VERSION "10.7.5"

NS_ :

BS_:

BU_: ADAS_Info AMP CPD DUMMY_DEBUG DUMMY_ECU EASC HUD MHU XGW_Info

BO_ 18 MHU_Climate_control: 8 CPD
  SG_ CPD_MHU_Climate_control : 7|2@0+ (1,0) [0|3] "" MHU

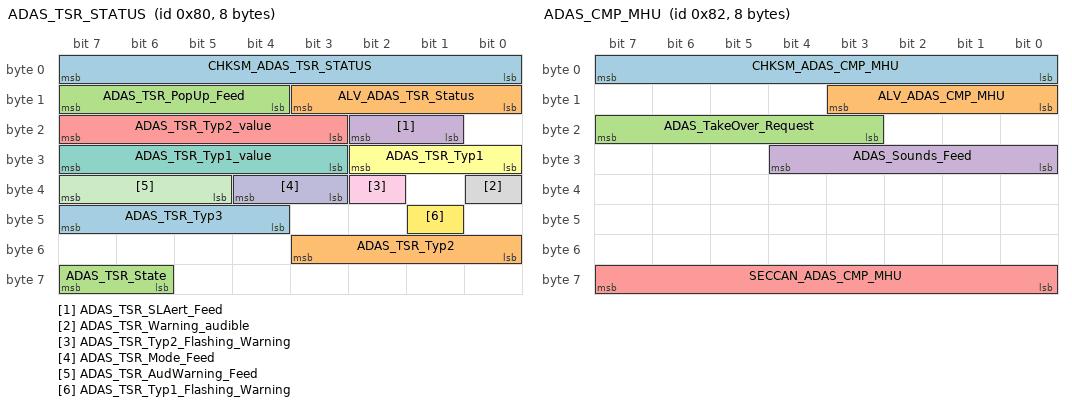
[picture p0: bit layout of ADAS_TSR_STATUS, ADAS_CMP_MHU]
BO_ 128 ADAS_TSR_STATUS: 8 ADAS_Info
  SG_ CHKSM_ADAS_TSR_STATUS : 7|8@0+ (1,0) [0|255] "" HUD,MHU
  SG_ ALV_ADAS_TSR_Status : 11|4@0+ (1,0) [0|14] "" HUD,MHU
  SG_ ADAS_TSR_PopUp_Feed : 15|4@0+ (1,0) [0|15] "-" MHU
  SG_ ADAS_TSR_SLAert_Feed : 18|2@0+ (1,0) [0|3] "-" HUD,MHU
  SG_ ADAS_TSR_Typ2_value : 23|5@0+ (1,0) [0|31] "-" HUD,MHU
  SG_ ADAS_TSR_Typ1 : 26|3@0+ (1,0) [0|7] "-" HUD,MHU
  SG_ ADAS_TSR_Typ1_value : 31|5@0+ (1,0) [0|31] "-" HUD,MHU
  SG_ ADAS_TSR_Warning_audible : 32|1@0+ (1,0) [0|1] "-" HUD,MHU
  SG_ ADAS_TSR_Typ2_Flashing_Warning : 34|1@0+ (1,0) [0|1] "-" HUD,MHU
  SG_ ADAS_TSR_Mode_Feed : 36|2@0+ (1,0) [0|3] "-" HUD,MHU
  SG_ ADAS_TSR_AudWarning_Feed : 39|3@0+ (1,0) [0|1] "-" HUD,MHU
  SG_ ADAS_TSR_Typ1_Flashing_Warning : 41|1@0+ (1,0) [0|1] "-" HUD,MHU
  SG_ ADAS_TSR_Typ3 : 47|4@0+ (1,0) [0|15] "-" HUD,MHU
  SG_ ADAS_TSR_Typ2 : 51|4@0+ (1,0) [0|15] "-" HUD,MHU
  SG_ ADAS_TSR_State : 63|2@0+ (1,0) [0|3] "-" HUD,MHU

BO_ 130 ADAS_CMP_MHU: 8 ADAS_Info
  SG_ CHKSM_ADAS_CMP_MHU : 7|8@0+ (1,0) [0|255] "" MHU
  SG_ ALV_ADAS_CMP_MHU : 11|4@0+ (1,0) [0|14] "" MHU
  SG_ ADAS_TakeOver_Request : 23|5@0+ (1,0) [0|31] "-" MHU
  SG_ ADAS_Sounds_Feed : 28|5@0+ (1,0) [0|31] "-" MHU
  SG_ SECCAN_ADAS_CMP_MHU : 63|8@0+ (1,0) [0|255] "" MHU

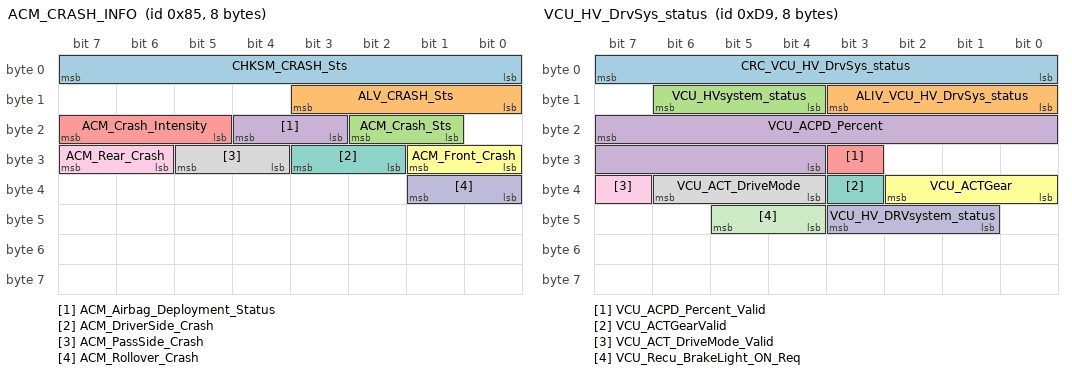
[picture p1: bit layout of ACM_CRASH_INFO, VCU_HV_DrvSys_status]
BO_ 133 ACM_CRASH_INFO: 8 XGW_Info
  SG_ CHKSM_CRASH_Sts : 7|8@0+ (1,0) [0|255] "" MHU
  SG_ ALV_CRASH_Sts : 11|4@0+ (1,0) [0|14] "" MHU
  SG_ ACM_Crash_Sts : 18|2@0+ (1,0) [0|3] "" MHU
  SG_ ACM_Airbag_Deployment_Status : 20|2@0+ (1,0) [0|3] "-" MHU
  SG_ ACM_Crash_Intensity : 23|3@0+ (1,0) [0|7] "" MHU
  SG_ ACM_Front_Crash : 25|2@0+ (1,0) [0|3] "-" MHU
  SG_ ACM_DriverSide_Crash : 27|2@0+ (1,0) [0|3] "" MHU
  SG_ ACM_PassSide_Crash : 29|2@0+ (1,0) [0|3] "-" MHU
  SG_ ACM_Rear_Crash : 31|2@0+ (1,0) [0|3] "-" MHU
  SG_ ACM_Rollover_Crash : 33|2@0+ (1,0) [0|3] "-" MHU

BO_ 147 IDB_MILEAGE: 4 XGW_Info
  SG_ CHKSM_MILEAGE : 7|8@0+ (1,0) [0|255] "" MHU
  SG_ ALIVE_MILEAGE : 11|4@0+ (1,0) [0|14] "" MHU
  SG_ Mileage : 23|16@0+ (1,0) [0|65535] "km" MHU

BO_ 149 IDB_FUNCTION: 8 XGW_Info
  SG_ CHKSM_IDB_FUNCTION : 7|8@0+ (1,0) [0|255] "" MHU
  SG_ ALV_IDB_FUNCTION : 11|4@0+ (1,0) [0|14] "" MHU
  SG_ STAT_ABS : 13|2@0+ (1,0) [0|3] "" MHU
  SG_ AYC_Active : 17|2@0+ (1,0) [0|3] "Bit" MHU
  SG_ ASR_Active : 19|2@0+ (1,0) [0|3] "-" MHU
  SG_ STAT_DSC : 21|2@0+ (1,0) [0|3] "-" MHU
  SG_ DSC_Active : 23|2@0+ (1,0) [0|3] "" MHU
  SG_ HBA_ActiveSignal : 25|2@0+ (1,0) [0|3] "" MHU
  SG_ ARM_ActiveSignal : 27|2@0+ (1,0) [0|3] "-" MHU
  SG_ STAT_AutoHazardBlinking : 29|2@0+ (1,0) [0|3] "Bit" MHU
  SG_ MSR_Active : 31|2@0+ (1,0) [0|3] "-" MHU
  SG_ HSA_ActiveSignal : 33|2@0+ (1,0) [0|3] "" MHU
  SG_ EPBi_ECD_ActiveSignal : 35|2@0+ (1,0) [0|3] "" MHU
  SG_ TSM_Active : 37|2@0+ (1,0) [0|3] "-" MHU
  SG_ HAS_Available : 41|2@0+ (1,0) [0|3] "" MHU
  SG_ STAT_EBD : 43|2@0+ (1,0) [0|3] "" MHU
  SG_ EBD_Active : 45|2@0+ (1,0) [0|3] "" MHU
  SG_ ST_BRG_MSA : 55|4@0+ (1,0) [0|15] "" MHU

BO_ 150 MHU_IDB_Mode_Select: 2 MHU
  SG_ CHKSM_MHU_IDB_Mode_Select : 7|8@0+ (1,0) [0|255] "" XGW_Info
  SG_ ALV_MHU_IDB_Mode_Select : 11|4@0+ (1,0) [0|14] "" XGW_Info
  SG_ MHU_IDB_Mode_Select_Signal : 15|2@0+ (1,0) [0|3] "" XGW_Info

BO_ 217 VCU_HV_DrvSys_status: 8 XGW_Info
  SG_ CRC_VCU_HV_DrvSys_status : 7|8@0+ (1,0) [0|255] "" CPD,MHU
  SG_ ALIV_VCU_HV_DrvSys_status : 11|4@0+ (1,0) [0|14] "" CPD,MHU
  SG_ VCU_HVsystem_status : 14|3@0+ (1,0) [0|7] "-" CPD,MHU
  SG_ VCU_ACPD_Percent : 23|12@0+ (0.0625,0) [0|100] "%" MHU
  SG_ VCU_ACPD_Percent_Valid : 27|1@0+ (1,0) [0|1] "" MHU
  SG_ VCU_ACTGear : 34|3@0+ (1,0) [0|7] "" HUD,MHU
  SG_ VCU_ACTGearValid : 35|1@0+ (1,0) [0|1] "" HUD,MHU
  SG_ VCU_ACT_DriveMode : 38|3@0+ (1,0) [0|7] "" HUD,MHU
  SG_ VCU_ACT_DriveMode_Valid : 39|1@0+ (1,0) [0|1] "-" HUD,MHU
  SG_ VCU_HV_DRVsystem_status : 43|3@0+ (1,0) [0|7] "" MHU
  SG_ VCU_Recu_BrakeLight_ON_Req : 45|2@0+ (1,0) [0|3] "-" MHU

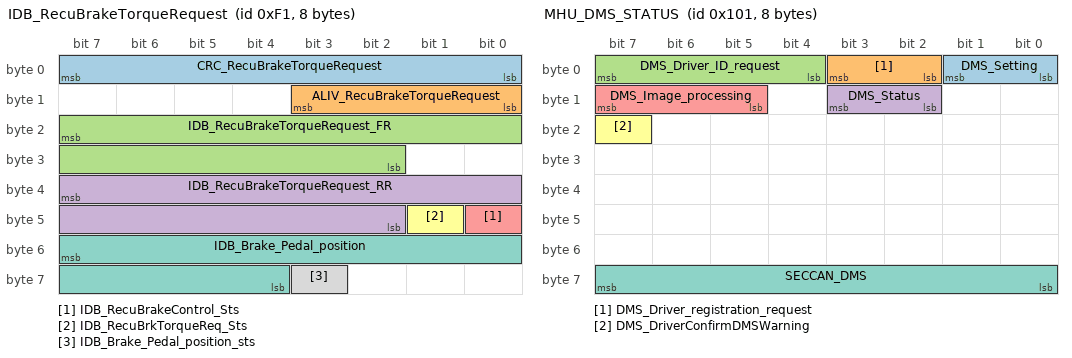
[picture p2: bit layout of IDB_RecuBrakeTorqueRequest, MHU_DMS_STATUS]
BO_ 241 IDB_RecuBrakeTorqueRequest: 8 XGW_Info
  SG_ CRC_RecuBrakeTorqueRequest : 7|8@0+ (1,0) [0|255] "" DUMMY_ECU,MHU
  SG_ ALIV_RecuBrakeTorqueRequest : 11|4@0+ (1,0) [0|14] "" DUMMY_ECU,MHU
  SG_ IDB_RecuBrakeTorqueRequest_FR : 23|14@0+ (1,0) [0|8000] "Nm" DUMMY_ECU
  SG_ IDB_RecuBrakeTorqueRequest_RR : 39|14@0+ (1,0) [0|8000] "Nm" DUMMY_ECU
  SG_ IDB_RecuBrakeControl_Sts : 40|1@0+ (1,0) [0|1] "" DUMMY_ECU
  SG_ IDB_RecuBrkTorqueReq_Sts : 41|1@0+ (1,0) [0|1] "" DUMMY_ECU
  SG_ IDB_Brake_Pedal_position : 55|12@0+ (0.0625,0) [0|100] "%" MHU
  SG_ IDB_Brake_Pedal_position_sts : 59|1@0+ (1,0) [0|1] "" MHU

BO_ 256 MHU_Vehicle_Info: 8 MHU
  SG_ CHKSM_MHU_VEH_INFO : 7|8@0+ (1,0) [0|255] "" ADAS_Info,HUD,XGW_Info
  SG_ ALV_MHU_VEH_INFO : 11|4@0+ (1,0) [0|14] "" ADAS_Info,HUD,XGW_Info
  SG_ MHU_UserProfileId : 23|4@0+ (1,0) [0|15] "-" HUD,XGW_Info
  SG_ MHU_Connectivity_Status : 47|3@0+ (1,0) [0|7] "" ADAS_Info,XGW_Info

BO_ 257 MHU_DMS_STATUS: 8 MHU
  SG_ DMS_Setting : 1|2@0+ (1,0) [0|3] "-" ADAS_Info
  SG_ DMS_Driver_registration_request : 3|2@0+ (1,0) [0|3] "-" ADAS_Info
  SG_ DMS_Driver_ID_request : 7|4@0+ (1,0) [0|15] "-" ADAS_Info
  SG_ DMS_Status : 11|2@0+ (1,0) [0|3] "-" ADAS_Info
  SG_ DMS_Image_processing : 15|3@0+ (1,0) [0|7] "-" ADAS_Info
  SG_ DMS_DriverConfirmDMSWarning : 23|1@0+ (1,0) [0|1] "" ADAS_Info
  SG_ SECCAN_DMS : 63|8@0+ (1,0) [0|255] "" ADAS_Info

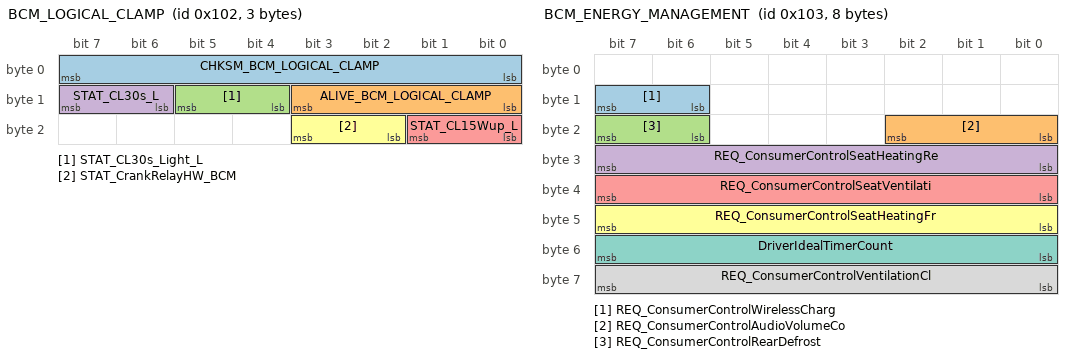
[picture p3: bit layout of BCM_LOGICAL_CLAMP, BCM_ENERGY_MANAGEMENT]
BO_ 258 BCM_LOGICAL_CLAMP: 3 XGW_Info
  SG_ CHKSM_BCM_LOGICAL_CLAMP : 7|8@0+ (1,0) [0|255] "" HUD,MHU
  SG_ ALIVE_BCM_LOGICAL_CLAMP : 11|4@0+ (1,0) [0|14] "" HUD,MHU
  SG_ STAT_CL30s_Light_L : 13|2@0+ (1,0) [0|3] "" MHU
  SG_ STAT_CL30s_L : 15|2@0+ (1,0) [0|3] "Bit" HUD,MHU
  SG_ STAT_CL15Wup_L : 17|2@0+ (1,0) [0|3] "Bit" MHU
  SG_ STAT_CrankRelayHW_BCM : 19|2@0+ (1,0) [0|3] "Bit" MHU

BO_ 259 BCM_ENERGY_MANAGEMENT: 8 XGW_Info
  SG_ REQ_ConsumerControlWirelessCharg : 15|2@0+ (1,0) [0|3] "-" MHU
  SG_ REQ_ConsumerControlAudioVolumeCo : 18|3@0+ (1,0) [0|7] "-" MHU
  SG_ REQ_ConsumerControlRearDefrost : 23|2@0+ (1,0) [0|3] "-" MHU
  SG_ REQ_ConsumerControlSeatHeatingRe : 31|8@0+ (1,0) [0|100] "%" MHU
  SG_ REQ_ConsumerControlSeatVentilati : 39|8@0+ (1,0) [0|100] "%" MHU
  SG_ REQ_ConsumerControlSeatHeatingFr : 47|8@0+ (1,0) [0|100] "%" MHU
  SG_ DriverIdealTimerCount : 55|8@0+ (5,0) [0|1275] "s" MHU
  SG_ REQ_ConsumerControlVentilationCl : 63|8@0+ (1,0) [0|100] "%" MHU

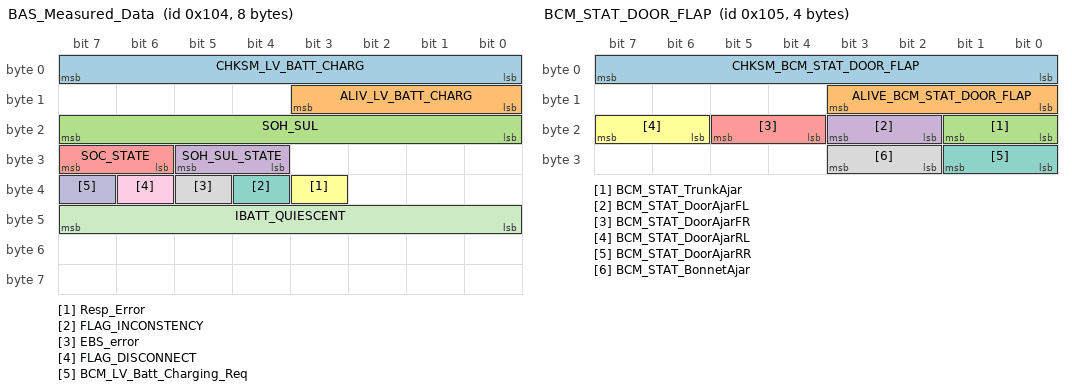
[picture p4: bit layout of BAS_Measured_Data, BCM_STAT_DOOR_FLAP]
BO_ 260 BAS_Measured_Data: 8 XGW_Info
  SG_ CHKSM_LV_BATT_CHARG : 7|8@0+ (1,0) [0|255] "" MHU
  SG_ ALIV_LV_BATT_CHARG : 11|4@0+ (1,0) [0|14] "" MHU
  SG_ SOH_SUL : 23|8@0+ (1,0) [0|100] "%" MHU
  SG_ SOH_SUL_STATE : 29|2@0+ (1,0) [0|3] "" MHU
  SG_ SOC_STATE : 31|2@0+ (1,0) [0|3] "%" MHU
  SG_ Resp_Error : 35|1@0+ (1,0) [0|1] "" MHU
  SG_ FLAG_INCONSTENCY : 36|1@0+ (1,0) [0|1] "%" MHU
  SG_ EBS_error : 37|1@0+ (1,0) [0|1] "" MHU
  SG_ FLAG_DISCONNECT : 38|1@0+ (1,0) [0|1] "" MHU
  SG_ BCM_LV_Batt_Charging_Req : 39|1@0+ (1,0) [0|1] "" MHU
  SG_ IBATT_QUIESCENT : 47|8@0+ (0.00390625,0) [0|0.984375] "" MHU

BO_ 261 BCM_STAT_DOOR_FLAP: 4 XGW_Info
  SG_ CHKSM_BCM_STAT_DOOR_FLAP : 7|8@0+ (1,0) [0|255] "" CPD,MHU
  SG_ ALIVE_BCM_STAT_DOOR_FLAP : 11|4@0+ (1,0) [0|14] "" CPD,MHU
  SG_ BCM_STAT_TrunkAjar : 17|2@0+ (1,0) [0|3] "Bit" CPD,MHU
  SG_ BCM_STAT_DoorAjarFL : 19|2@0+ (1,0) [0|3] "Bit" CPD,MHU
  SG_ BCM_STAT_DoorAjarFR : 21|2@0+ (1,0) [0|3] "Bit" CPD,MHU
  SG_ BCM_STAT_DoorAjarRL : 23|2@0+ (1,0) [0|3] "Bit" CPD,MHU
  SG_ BCM_STAT_DoorAjarRR : 25|2@0+ (1,0) [0|3] "Bit" CPD,MHU
  SG_ BCM_STAT_BonnetAjar : 27|2@0+ (1,0) [0|3] "Bit" CPD,MHU

BO_ 262 BCM_LIGHT: 8 XGW_Info
  SG_ CHKSM_BCM_LIGHT : 7|8@0+ (1,0) [0|255] "" HUD,MHU
  SG_ ALIVE_BCM_LIGHT : 11|4@0+ (1,0) [0|14] "" HUD,MHU
  SG_ BCM_DayRunningLampSts : 13|2@0+ (1,0) [0|3] "" HUD,MHU
  SG_ BCM_ReverseLightSts : 15|2@0+ (1,0) [0|3] "" HUD,MHU
  SG_ BCM_StopLightSts : 17|2@0+ (1,0) [0|3] "" HUD,MHU
  SG_ BCM_LicensePlateLightSts : 19|2@0+ (1,0) [0|3] "" HUD,MHU
  SG_ BCM_Fr_Dimming_dome_lampSts : 21|2@0+ (1,0) [0|3] "" HUD,MHU
  SG_ BCM_Rr_Dimming_dome_lampSts : 23|2@0+ (1,0) [0|3] "" HUD,MHU
  SG_ BCM_STAT_InteriorLight : 25|2@0+ (1,0) [0|3] "Bit" HUD,MHU
  SG_ BCM_STAT_LightActivation : 28|3@0+ (1,0) [0|7] "-" HUD,MHU
  SG_ BCM_HighBeamSts : 31|2@0+ (1,0) [0|3] "" HUD,MHU
  SG_ BCM_STAT_SwitchLightBrightness : 39|7@0+ (1,0) [0|100] "%" HUD,MHU
  SG_ BCM_LowBeamSts : 41|2@0+ (1,0) [0|3] "-" HUD,MHU
  SG_ BCM_RearFogLmpSts : 43|2@0+ (1,0) [0|3] "-" HUD,MHU
  SG_ BCM_FrntFogLmpSts : 45|2@0+ (1,0) [0|3] "" HUD,MHU
  SG_ BCM_PosLmpSts : 47|2@0+ (1,0) [0|3] "-" HUD,MHU
  SG_ BCM_HornSts : 53|2@0+ (1,0) [0|3] "" MHU
  SG_ BCM_TurnIndicatorSts : 55|2@0+ (1,0) [0|3] "" HUD,MHU

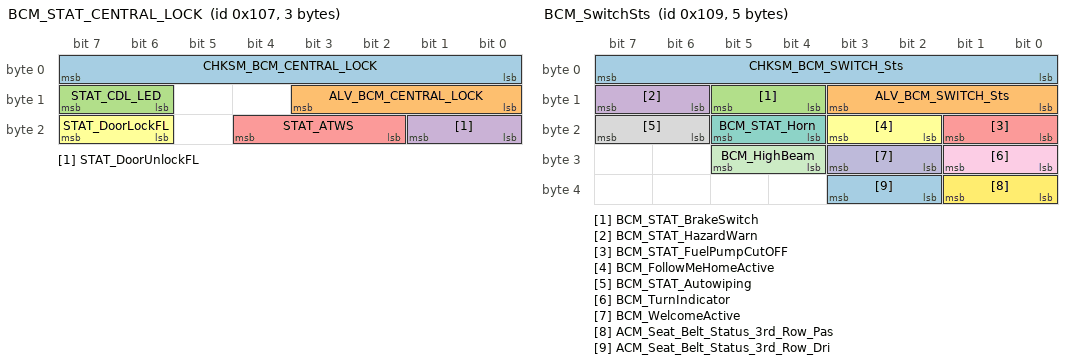
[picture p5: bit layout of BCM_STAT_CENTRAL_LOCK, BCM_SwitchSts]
BO_ 263 BCM_STAT_CENTRAL_LOCK: 3 XGW_Info
  SG_ CHKSM_BCM_CENTRAL_LOCK : 7|8@0+ (1,0) [0|255] "" CPD,MHU
  SG_ ALV_BCM_CENTRAL_LOCK : 11|4@0+ (1,0) [0|14] "" CPD,MHU
  SG_ STAT_CDL_LED : 15|2@0+ (1,0) [0|3] "-" MHU
  SG_ STAT_DoorUnlockFL : 17|2@0+ (1,0) [0|3] "Bit" MHU
  SG_ STAT_ATWS : 20|3@0+ (1,0) [0|7] "Bit" MHU
  SG_ STAT_DoorLockFL : 23|2@0+ (1,0) [0|3] "Bit" CPD,MHU

BO_ 265 BCM_SwitchSts: 5 XGW_Info
  SG_ CHKSM_BCM_SWITCH_Sts : 7|8@0+ (1,0) [0|255] "" MHU
  SG_ ALV_BCM_SWITCH_Sts : 11|4@0+ (1,0) [0|14] "" MHU
  SG_ BCM_STAT_BrakeSwitch : 13|2@0+ (1,0) [0|3] "" MHU
  SG_ BCM_STAT_HazardWarn : 15|2@0+ (1,0) [0|3] "-" MHU
  SG_ BCM_STAT_FuelPumpCutOFF : 17|2@0+ (1,0) [0|3] "" MHU
  SG_ BCM_FollowMeHomeActive : 19|2@0+ (1,0) [0|3] "" MHU
  SG_ BCM_STAT_Horn : 21|2@0+ (1,0) [0|3] "-" MHU
  SG_ BCM_STAT_Autowiping : 23|2@0+ (1,0) [0|3] "" MHU
  SG_ BCM_TurnIndicator : 25|2@0+ (1,0) [0|3] "" MHU
  SG_ BCM_WelcomeActive : 27|2@0+ (1,0) [0|3] "-" MHU
  SG_ BCM_HighBeam : 29|2@0+ (1,0) [0|3] "" MHU
  SG_ ACM_Seat_Belt_Status_3rd_Row_Pas : 33|2@0+ (1,0) [0|3] "" MHU
  SG_ ACM_Seat_Belt_Status_3rd_Row_Dri : 35|2@0+ (1,0) [0|3] "-" MHU

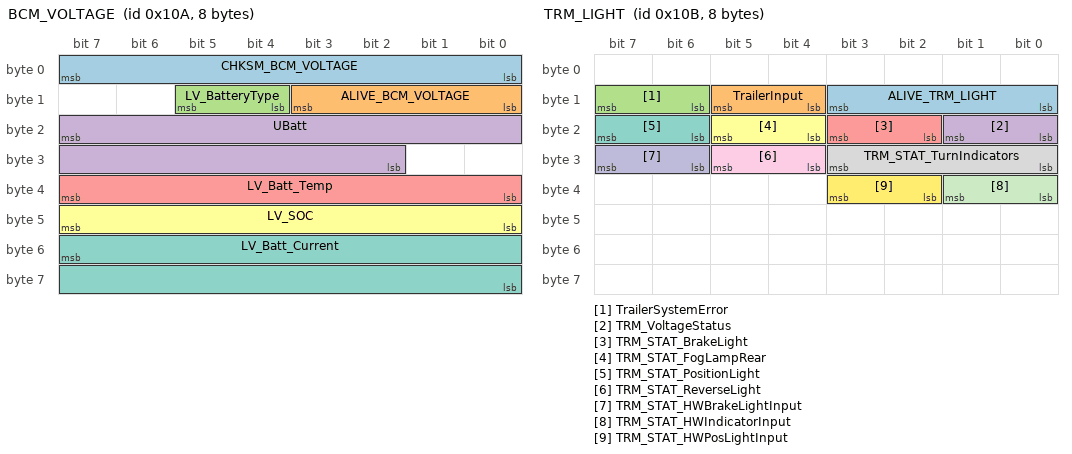
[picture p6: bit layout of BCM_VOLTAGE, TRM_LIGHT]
BO_ 266 BCM_VOLTAGE: 8 XGW_Info
  SG_ CHKSM_BCM_VOLTAGE : 7|8@0+ (1,0) [0|255] "" ADAS_Info,AMP,CPD,EASC,HUD,MHU
  SG_ ALIVE_BCM_VOLTAGE : 11|4@0+ (1,0) [0|14] "" ADAS_Info,AMP,CPD,EASC,HUD,MHU
  SG_ LV_BatteryType : 13|2@0+ (1,0) [0|3] "Number" MHU
  SG_ UBatt : 23|14@0+ (0.0009777,3) [3|18] "V" ADAS_Info,AMP,CPD,EASC,HUD,MHU
  SG_ LV_Batt_Temp : 39|8@0+ (1,-40) [-40|105] "Degree C" ADAS_Info,AMP,CPD,EASC,HUD,MHU
  SG_ LV_SOC : 47|8@0+ (1,0) [0|100] "%" ADAS_Info,AMP,CPD,EASC,HUD,MHU
  SG_ LV_Batt_Current : 55|16@0+ (0.03125,-1536) [-1536|511.90625] "A" ADAS_Info,AMP,CPD,EASC,HUD,MHU

BO_ 267 TRM_LIGHT: 8 XGW_Info
  SG_ ALIVE_TRM_LIGHT : 11|4@0+ (1,0) [0|14] "" MHU
  SG_ TrailerInput : 13|2@0+ (1,0) [0|3] "" MHU
  SG_ TrailerSystemError : 15|2@0+ (1,0) [0|3] "" MHU
  SG_ TRM_VoltageStatus : 17|2@0+ (1,0) [0|3] "" MHU
  SG_ TRM_STAT_BrakeLight : 19|2@0+ (1,0) [0|3] "" MHU
  SG_ TRM_STAT_FogLampRear : 21|2@0+ (1,0) [0|3] "" MHU
  SG_ TRM_STAT_PositionLight : 23|2@0+ (1,0) [0|3] "" MHU
  SG_ TRM_STAT_TurnIndicators : 27|4@0+ (1,0) [0|15] "" MHU
  SG_ TRM_STAT_ReverseLight : 29|2@0+ (1,0) [0|3] "" MHU
  SG_ TRM_STAT_HWBrakeLightInput : 31|2@0+ (1,0) [0|3] "" MHU
  SG_ TRM_STAT_HWIndicatorInput : 33|2@0+ (1,0) [0|3] "" MHU
  SG_ TRM_STAT_HWPosLightInput : 35|2@0+ (1,0) [0|3] "" MHU

BO_ 268 BCM_RemoteCtrlSts: 8 XGW_Info
  SG_ Checksum_0x10C : 7|8@0+ (1,0) [0|255] "" MHU
  SG_ Rolling_Counter_0x10C : 11|4@0+ (1,0) [0|14] "" MHU
  SG_ BCM_TboxAuthStatus : 23|2@0+ (1,0) [0|3] "-" MHU
  SG_ BCM_RandomNum32bit : 31|32@0+ (1,0) [0|4294967295] "-" MHU

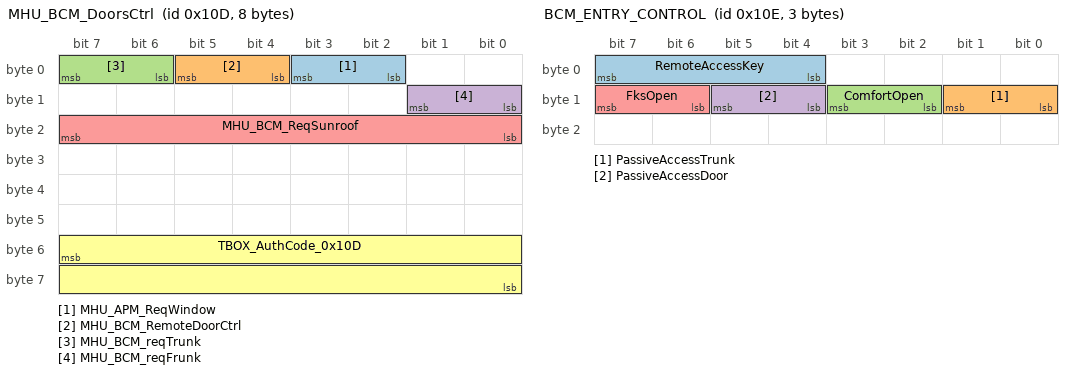
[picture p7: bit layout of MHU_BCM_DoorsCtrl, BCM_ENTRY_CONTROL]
BO_ 269 MHU_BCM_DoorsCtrl: 8 MHU
  SG_ MHU_APM_ReqWindow : 3|2@0+ (1,0) [0|3] "-" XGW_Info
  SG_ MHU_BCM_RemoteDoorCtrl : 5|2@0+ (1,0) [0|3] "-" XGW_Info
  SG_ MHU_BCM_reqTrunk : 7|2@0+ (1,0) [0|3] "-" XGW_Info
  SG_ MHU_BCM_reqFrunk : 9|2@0+ (1,0) [0|3] "-" XGW_Info
  SG_ MHU_BCM_ReqSunroof : 23|8@0+ (1,0) [0|255] "%" XGW_Info
  SG_ TBOX_AuthCode_0x10D : 55|16@0+ (1,0) [0|65535] "-" XGW_Info

BO_ 270 BCM_ENTRY_CONTROL: 3 XGW_Info
  SG_ RemoteAccessKey : 7|4@0+ (1,0) [0|15] "-" CPD,MHU
  SG_ PassiveAccessTrunk : 9|2@0+ (1,0) [0|3] "-" CPD,MHU
  SG_ ComfortOpen : 11|2@0+ (1,0) [0|3] "-" CPD,MHU
  SG_ PassiveAccessDoor : 13|2@0+ (1,0) [0|3] "-" CPD,MHU
  SG_ FksOpen : 15|2@0+ (1,0) [0|3] "" CPD,MHU

BO_ 271 MHU_BCM_HornLightControl: 8 MHU
  SG_ MHU_SetHornOnOff : 3|2@0+ (1,0) [0|3] "-" XGW_Info
  SG_ MHU_SetLowBeam : 5|2@0+ (1,0) [0|3] "" XGW_Info
  SG_ MHU_SetHighBeam : 7|2@0+ (1,0) [0|3] "" XGW_Info
  SG_ TBOX_AuthCode_0x10F : 55|16@0+ (1,0) [0|65535] "-" XGW_Info

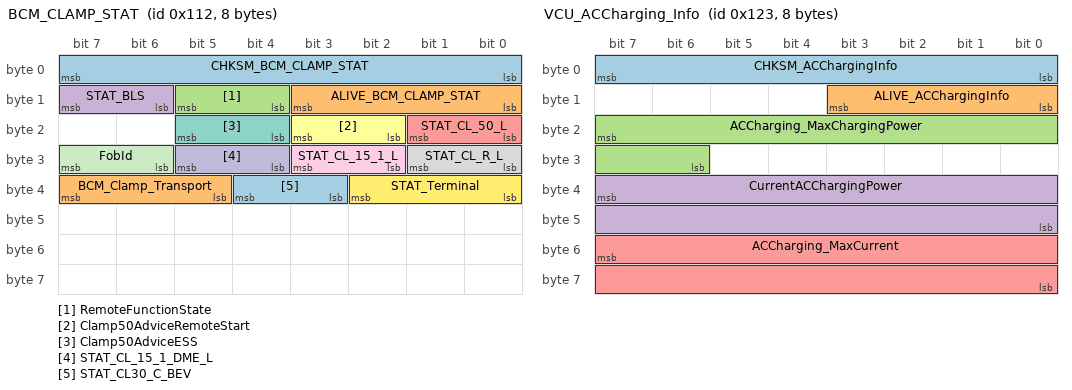
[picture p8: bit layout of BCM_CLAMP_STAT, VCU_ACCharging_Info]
BO_ 274 BCM_CLAMP_STAT: 8 XGW_Info
  SG_ CHKSM_BCM_CLAMP_STAT : 7|8@0+ (1,0) [0|255] "" ADAS_Info,AMP,EASC,HUD,MHU
  SG_ ALIVE_BCM_CLAMP_STAT : 11|4@0+ (1,0) [0|14] "" ADAS_Info,AMP,EASC,HUD,MHU
  SG_ RemoteFunctionState : 13|2@0+ (1,0) [0|3] "" ADAS_Info,AMP,EASC,HUD,MHU
  SG_ STAT_BLS : 15|2@0+ (1,0) [0|3] "-" ADAS_Info,AMP,EASC,HUD,MHU
  SG_ STAT_CL_50_L : 17|2@0+ (1,0) [0|3] "" ADAS_Info,AMP,EASC,HUD,MHU
  SG_ Clamp50AdviceRemoteStart : 19|2@0+ (1,0) [0|3] "-" ADAS_Info,AMP,EASC,HUD,MHU
  SG_ Clamp50AdviceESS : 21|2@0+ (1,0) [0|3] "-" ADAS_Info,AMP,EASC,HUD,MHU
  SG_ STAT_CL_R_L : 25|2@0+ (1,0) [0|3] "" ADAS_Info,AMP,EASC,HUD,MHU
  SG_ STAT_CL_15_1_L : 27|2@0+ (1,0) [0|3] "-" ADAS_Info,AMP,EASC,HUD,MHU
  SG_ STAT_CL_15_1_DME_L : 29|2@0+ (1,0) [0|3] "" ADAS_Info,AMP,EASC,HUD,MHU
  SG_ FobId : 31|2@0+ (1,0) [0|3] "Bit" ADAS_Info,AMP,EASC,HUD,MHU
  SG_ STAT_Terminal : 34|3@0+ (1,0) [0|7] "Bit" ADAS_Info,AMP,CPD,EASC,HUD,MHU
  SG_ STAT_CL30_C_BEV : 36|2@0+ (1,0) [0|3] "Bit" ADAS_Info,AMP,EASC,HUD,MHU
  SG_ BCM_Clamp_Transport : 39|3@0+ (1,0) [0|7] "" ADAS_Info,AMP,EASC,HUD,MHU

BO_ 276 BCM_LVBAT_Data: 8 XGW_Info
  SG_ CHKSM_LVBAT_DATA : 7|8@0+ (1,0) [0|255] ""  MHU
  SG_ ALIV_LVBAT_DATA : 11|4@0+ (1,0) [0|14] ""  MHU
  SG_ LV_ErrorSts : 14|3@0+ (1,0) [0|7] ""  MHU
  SG_ LV_MinCellVolt : 23|8@0+ (0.015625,1) [1|5] "V"  MHU
  SG_ LV_MaxCellVolt : 31|8@0+ (0.015625,1) [1|5] "V"  MHU
  SG_ LV_MinCellTemp : 39|8@0+ (1,-40) [-40|215] "Degree C"  MHU
  SG_ LV_MaxCellTemp : 47|8@0+ (1,-40) [-40|215] "Degree C"  MHU
  SG_ LV_Discharger_Err : 48|1@0+ (1,0) [0|1] ""  MHU
  SG_ LV_Discharger_Sts : 49|1@0+ (1,0) [0|1] ""  MHU
  SG_ LV_Charger_Err : 50|1@0+ (1,0) [0|1] ""  MHU
  SG_ LV_Charger_Sts : 51|1@0+ (1,0) [0|1] ""  MHU
  SG_ LV_OverVoltage : 52|1@0+ (1,0) [0|1] ""  MHU
  SG_ LV_UnderVoltage : 53|1@0+ (1,0) [0|1] ""  MHU
  SG_ LV_OverCurrent : 54|1@0+ (1,0) [0|1] ""  MHU
  SG_ LV_UnderTemp : 55|1@0+ (1,0) [0|1] ""  MHU
  SG_ LV_OverTemp : 56|1@0+ (1,0) [0|1] ""  MHU
  SG_ LV_OverCharge : 57|1@0+ (1,0) [0|1] ""  MHU
  SG_ LV_OverDischarge : 58|1@0+ (1,0) [0|1] ""  MHU
  SG_ LV_CellBalance_Sts : 59|1@0+ (1,0) [0|1] ""  MHU
  SG_ LV_CellBalance_Error : 60|1@0+ (1,0) [0|1] ""  MHU
  SG_ LV_ThermalRunaway : 61|1@0+ (1,0) [0|1] ""  MHU

BO_ 277 BCM_Childlock: 8 XGW_Info
  SG_ BCM_ChildLock_Feedback : 7|2@0+ (1,0) [0|3] "" MHU

BO_ 282 MHU_ServiceMode_Setting: 8 MHU
  SG_ MHU_SET_WiperServicePositionMod : 5|2@0+ (1,0) [0|3] "" XGW_Info
  SG_ MHU_Read_KeyFobOnCenterConsole : 7|2@0+ (1,0) [0|3] "" XGW_Info

BO_ 283 MHU_BCM_RemoteClampCtrl: 8 MHU
  SG_ TBOX_STAT_TerminalReq : 7|3@0+ (1,0) [0|7] "-" XGW_Info
  SG_ TBOX_AuthCode_0x11B : 55|16@0+ (1,0) [0|65535] "" XGW_Info

BO_ 284 MHU_BCM_FOTAClampCtrl: 8 MHU
  SG_ TBOX_FOTA_STAT_TerminalReq : 7|3@0+ (1,0) [0|7] "-" XGW_Info

BO_ 291 VCU_ACCharging_Info: 8 XGW_Info
  SG_ CHKSM_ACChargingInfo : 7|8@0+ (1,0) [0|255] "" MHU
  SG_ ALIVE_ACChargingInfo : 11|4@0+ (1,0) [0|14] "" MHU
  SG_ ACCharging_MaxChargingPower : 23|10@0+ (0.1,0) [0|102.2] "kW" MHU
  SG_ CurrentACChargingPower : 39|16@0+ (0.1,0) [0|6553.5] "kW" MHU
  SG_ ACCharging_MaxCurrent : 55|16@0+ (0.1,0) [0|3276.7] "A" MHU

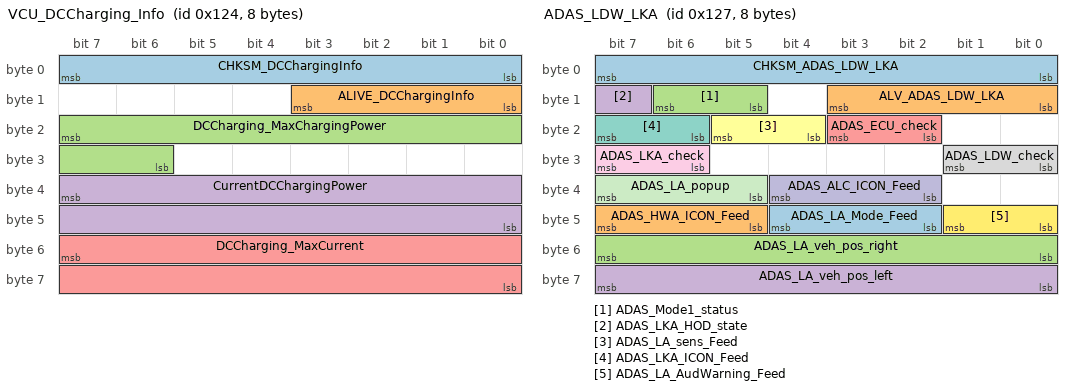
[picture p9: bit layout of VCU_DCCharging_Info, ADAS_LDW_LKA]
BO_ 292 VCU_DCCharging_Info: 8 XGW_Info
  SG_ CHKSM_DCChargingInfo : 7|8@0+ (1,0) [0|255] "" MHU
  SG_ ALIVE_DCChargingInfo : 11|4@0+ (1,0) [0|14] "" MHU
  SG_ DCCharging_MaxChargingPower : 23|10@0+ (0.1,0) [0|102.2] "kW" MHU
  SG_ CurrentDCChargingPower : 39|16@0+ (0.1,0) [0|6553.5] "kW" MHU
  SG_ DCCharging_MaxCurrent : 55|16@0+ (0.1,0) [0|3276.7] "A" MHU

BO_ 294 MHU_ISA_Speed: 1 MHU
  SG_ MHU_ISA_SpeedLimitCon_Percent : 3|3@0+ (1,0) [0|7] "-" ADAS_Info
  SG_ MHU_ISA_Speed_Setting : 7|4@0+ (1,0) [0|15] "-" ADAS_Info

BO_ 295 ADAS_LDW_LKA: 8 ADAS_Info
  SG_ CHKSM_ADAS_LDW_LKA : 7|8@0+ (1,0) [0|255] "" HUD,MHU
  SG_ ALV_ADAS_LDW_LKA : 11|4@0+ (1,0) [0|14] "" HUD,MHU
  SG_ ADAS_Mode1_status : 14|2@0+ (1,0) [0|3] "-" HUD,MHU
  SG_ ADAS_LKA_HOD_state : 15|1@0+ (1,0) [0|1] "-" HUD,MHU
  SG_ ADAS_ECU_check : 19|2@0+ (1,0) [0|3] "-" HUD,MHU
  SG_ ADAS_LA_sens_Feed : 21|2@0+ (1,0) [0|3] "-" HUD,MHU
  SG_ ADAS_LKA_ICON_Feed : 23|2@0+ (1,0) [0|3] "-" HUD,MHU
  SG_ ADAS_LDW_check : 25|2@0+ (1,0) [0|3] "-" HUD,MHU
  SG_ ADAS_LKA_check : 31|2@0+ (1,0) [0|3] "-" HUD,MHU
  SG_ ADAS_ALC_ICON_Feed : 36|3@0+ (1,0) [0|7] "-" HUD,MHU
  SG_ ADAS_LA_popup : 39|3@0+ (1,0) [0|7] "-" HUD,MHU
  SG_ ADAS_LA_AudWarning_Feed : 41|2@0+ (1,0) [0|3] "-" HUD,MHU
  SG_ ADAS_LA_Mode_Feed : 44|3@0+ (1,0) [0|7] "-" HUD,MHU
  SG_ ADAS_HWA_ICON_Feed : 47|3@0+ (1,0) [0|7] "-" HUD,MHU
  SG_ ADAS_LA_veh_pos_right : 55|8@0- (0.1,0) [-12.8|12.7] "m" HUD,MHU
  SG_ ADAS_LA_veh_pos_left : 63|8@0- (0.1,0) [-12.8|12.7] "m" HUD,MHU

BO_ 296 ADAS_FCW_RCTA: 8 ADAS_Info
  SG_ CHKSM_ADAS_FCW_RCTA : 7|8@0+ (1,0) [0|255] "" HUD,MHU
  SG_ ALV_ADAS_FCW_RCTA : 11|4@0+ (1,0) [0|14] "" HUD,MHU
  SG_ ADAS_RCTA_IndLeft : 13|2@0+ (1,0) [0|3] "-" HUD,MHU
  SG_ ADAS_RCTA_IndRight : 15|2@0+ (1,0) [0|3] "-" HUD,MHU
  SG_ ADAS_RCTA_SndWarn : 17|2@0+ (1,0) [0|3] "-" HUD,MHU
  SG_ ADAS_IA_check : 18|1@0+ (1,0) [0|1] "-" HUD,MHU
  SG_ ADAS_RCTA_state : 21|3@0+ (1,0) [0|7] "-" HUD,MHU
  SG_ ADAS_RCTA_sens_Feed : 23|2@0+ (1,0) [0|3] "-" HUD,MHU
  SG_ ADAS_IA_Left_warning : 25|2@0+ (1,0) [0|3] "-" HUD,MHU
  SG_ ADAS_FCW_Mode_Feed : 26|1@0+ (1,0) [0|1] "-" HUD,MHU
  SG_ ADAS_FCW_Sens_Feed : 28|2@0+ (1,0) [0|3] "-" HUD,MHU
  SG_ ADAS_FCW_state : 31|2@0+ (1,0) [0|3] "-" HUD,MHU
  SG_ ADAS_IA_state : 34|3@0+ (1,0) [0|7] "-" HUD,MHU
  SG_ ADAS_FCW_check : 36|2@0+ (1,0) [0|3] "-" HUD,MHU
  SG_ ADAS_IA_Right_warning : 38|2@0+ (1,0) [0|3] "-" HUD,MHU
  SG_ ADAS_IA_Mode_Feed : 39|1@0+ (1,0) [0|1] "-" HUD,MHU
  SG_ ADAS_RCTA_check : 42|2@0+ (1,0) [0|3] "-" HUD,MHU
  SG_ ADAS_RCTA_Mode_Feed : 43|1@0+ (1,0) [0|1] "-" HUD,MHU
  SG_ ADAS_FCW_warning : 47|2@0+ (1,0) [0|3] "-" HUD,MHU
  SG_ ADAS_LA_LeftLaneColor_Feed : 50|3@0+ (1,0) [0|7] "-" HUD,MHU
  SG_ ADAS_LA_RightLaneColor_Feed : 53|3@0+ (1,0) [0|7] "-" HUD,MHU

BO_ 297 MHU_LOCALSETTING: 8 MHU
  SG_ CHKSM_MHU_LocalSetting : 7|8@0+ (1,0) [0|255] "" ADAS_Info,HUD
  SG_ ALIVE_MHU_LocalSetting : 11|4@0+ (1,0) [0|14] "" ADAS_Info,HUD
  SG_ MHU_SETTING_DMSWarning : 47|2@0+ (1,0) [0|3] "" ADAS_Info,HUD
  SG_ MHU_STAT_SelectedCountry : 55|10@0+ (1,0) [0|1023] "" ADAS_Info,HUD

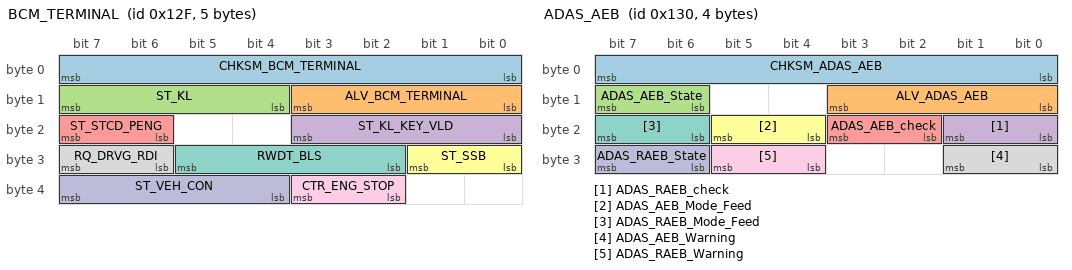
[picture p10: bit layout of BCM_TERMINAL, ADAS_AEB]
BO_ 303 BCM_TERMINAL: 5 XGW_Info
  SG_ CHKSM_BCM_TERMINAL : 7|8@0+ (1,0) [0|255] "" EASC,HUD,MHU
  SG_ ALV_BCM_TERMINAL : 11|4@0+ (1,0) [0|14] "" EASC,HUD,MHU
  SG_ ST_KL : 15|4@0+ (1,0) [0|15] "-" HUD,MHU
  SG_ ST_KL_KEY_VLD : 19|4@0+ (1,0) [0|15] "" HUD,MHU
  SG_ ST_STCD_PENG : 23|2@0+ (1,0) [0|3] "" HUD,MHU
  SG_ ST_SSB : 25|2@0+ (1,0) [0|3] "-" HUD,MHU
  SG_ RWDT_BLS : 29|4@0+ (1,0) [0|15] "-" HUD,MHU
  SG_ RQ_DRVG_RDI : 31|2@0+ (1,0) [0|3] "" HUD,MHU
  SG_ CTR_ENG_STOP : 35|2@0+ (1,0) [0|3] "Bit" HUD,MHU
  SG_ ST_VEH_CON : 39|4@0+ (1,0) [0|15] "-" EASC,HUD

BO_ 304 ADAS_AEB: 4 ADAS_Info
  SG_ CHKSM_ADAS_AEB : 7|8@0+ (1,0) [0|255] "" HUD,MHU
  SG_ ALV_ADAS_AEB : 11|4@0+ (1,0) [0|14] "" HUD,MHU
  SG_ ADAS_AEB_State : 15|2@0+ (1,0) [0|3] "-" HUD,MHU
  SG_ ADAS_RAEB_check : 17|2@0+ (1,0) [0|3] "-" HUD,MHU
  SG_ ADAS_AEB_check : 19|2@0+ (1,0) [0|3] "-" HUD,MHU
  SG_ ADAS_AEB_Mode_Feed : 21|2@0+ (1,0) [0|3] "-" HUD,MHU
  SG_ ADAS_RAEB_Mode_Feed : 23|2@0+ (1,0) [0|3] "-" HUD,MHU
  SG_ ADAS_AEB_Warning : 25|2@0+ (1,0) [0|3] "-" HUD,MHU
  SG_ ADAS_RAEB_Warning : 29|2@0+ (1,0) [0|3] "-" HUD,MHU
  SG_ ADAS_RAEB_State : 31|2@0+ (1,0) [0|3] "-" HUD,MHU

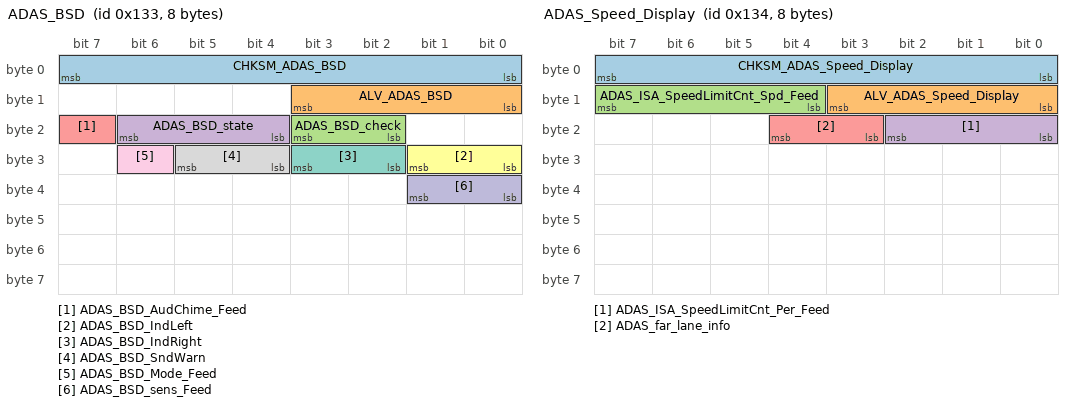
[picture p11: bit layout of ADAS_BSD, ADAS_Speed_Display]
BO_ 307 ADAS_BSD: 8 ADAS_Info
  SG_ CHKSM_ADAS_BSD : 7|8@0+ (1,0) [0|255] "" HUD,MHU
  SG_ ALV_ADAS_BSD : 11|4@0+ (1,0) [0|14] "" HUD,MHU
  SG_ ADAS_BSD_check : 19|2@0+ (1,0) [0|3] "-" HUD,MHU
  SG_ ADAS_BSD_state : 22|3@0+ (1,0) [0|7] "-" HUD,MHU
  SG_ ADAS_BSD_AudChime_Feed : 23|1@0+ (1,0) [0|1] "-" HUD,MHU
  SG_ ADAS_BSD_IndLeft : 25|2@0+ (1,0) [0|3] "-" HUD,MHU
  SG_ ADAS_BSD_IndRight : 27|2@0+ (1,0) [0|3] "-" HUD,MHU
  SG_ ADAS_BSD_SndWarn : 29|2@0+ (1,0) [0|3] "-" HUD,MHU
  SG_ ADAS_BSD_Mode_Feed : 30|1@0+ (1,0) [0|1] "-" HUD,MHU
  SG_ ADAS_BSD_sens_Feed : 33|2@0+ (1,0) [0|3] "-" HUD,MHU

BO_ 308 ADAS_Speed_Display: 8 ADAS_Info
  SG_ CHKSM_ADAS_Speed_Display : 7|8@0+ (1,0) [0|255] "" HUD,MHU
  SG_ ALV_ADAS_Speed_Display : 11|4@0+ (1,0) [0|14] "" HUD,MHU
  SG_ ADAS_ISA_SpeedLimitCnt_Spd_Feed : 15|4@0+ (1,0) [0|15] "-" HUD,MHU
  SG_ ADAS_ISA_SpeedLimitCnt_Per_Feed : 18|3@0+ (1,0) [0|7] "-" HUD,MHU
  SG_ ADAS_far_lane_info : 20|2@0+ (1,0) [0|3] "-" HUD,MHU

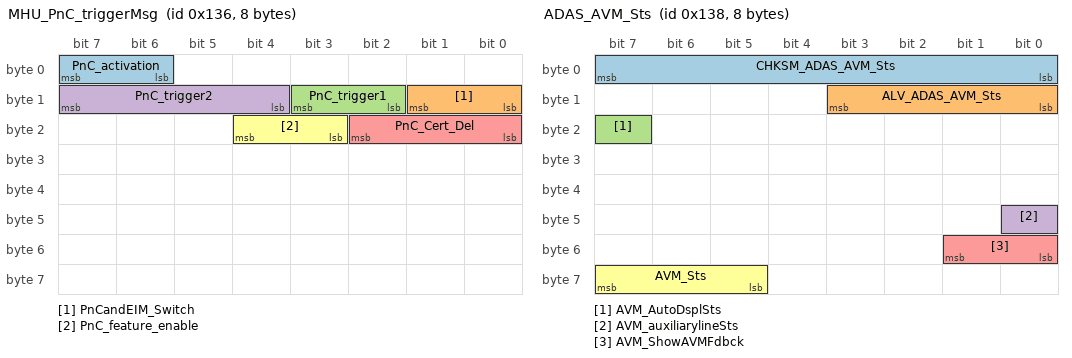
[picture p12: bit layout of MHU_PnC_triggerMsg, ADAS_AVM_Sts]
BO_ 310 MHU_PnC_triggerMsg: 8 MHU
  SG_ PnC_activation : 7|2@0+ (1,0) [0|3] "" XGW_Info
  SG_ PnCandEIM_Switch : 9|2@0+ (1,0) [0|3] "" XGW_Info
  SG_ PnC_trigger1 : 11|2@0+ (1,0) [0|3] "" XGW_Info
  SG_ PnC_trigger2 : 15|4@0+ (1,0) [0|15] "" XGW_Info
  SG_ PnC_Cert_Del : 18|3@0+ (1,0) [0|7] "" XGW_Info
  SG_ PnC_feature_enable : 20|2@0+ (1,0) [0|3] "" XGW_Info

BO_ 311 VCU_PnC_ErrorMsg: 8 XGW_Info
  SG_ OK_OldSessionJoined : 1|2@0+ (1,0) [0|3] "" MHU
  SG_ OK_NewSessionEstablished : 3|2@0+ (1,0) [0|3] "" MHU
  SG_ OK_CertificateExpireSoon : 5|2@0+ (1,0) [0|3] "" MHU
  SG_ PnC_OK : 7|2@0+ (1,0) [0|3] "" MHU
  SG_ Failed_CertificateNoAllowAtEVSE : 9|2@0+ (1,0) [0|3] "" MHU
  SG_ Failed_ContactorError : 11|2@0+ (1,0) [0|3] "" MHU
  SG_ Failed_NoChargeServiceSelectd : 13|2@0+ (1,0) [0|3] "" MHU
  SG_ PnC_Failed : 15|2@0+ (1,0) [0|3] "" MHU
  SG_ Failed_ServiceIDInvalid : 17|2@0+ (1,0) [0|3] "" MHU
  SG_ Falied_UnknownSession : 19|2@0+ (1,0) [0|3] "" MHU
  SG_ Failed_SignatureError : 21|2@0+ (1,0) [0|3] "" MHU
  SG_ Failed_SequenceError : 23|2@0+ (1,0) [0|3] "" MHU
  SG_ Failed_CertChainError : 25|2@0+ (1,0) [0|3] "" MHU
  SG_ Failed_NoCertificateAvailable : 27|2@0+ (1,0) [0|3] "" MHU
  SG_ Failed_CertificateRevoked : 29|2@0+ (1,0) [0|3] "" MHU
  SG_ Failed_PaymentSelectionInvalid : 31|2@0+ (1,0) [0|3] "" MHU
  SG_ Failed_WrongChargeParameter : 33|2@0+ (1,0) [0|3] "" MHU
  SG_ Failed_WrongEnergyTranferMode : 35|2@0+ (1,0) [0|3] "" MHU
  SG_ Failed_ChallengeInvalid : 37|2@0+ (1,0) [0|3] "" MHU
  SG_ Failed_ContractCancelled : 39|2@0+ (1,0) [0|3] "" MHU
  SG_ Failed_MeteringSignatureNotValid : 41|2@0+ (1,0) [0|3] "" MHU
  SG_ Failed_PowerDeliverNotApplied : 43|2@0+ (1,0) [0|3] "" MHU
  SG_ Failed_TarrifSelectionInvalid : 45|2@0+ (1,0) [0|3] "" MHU
  SG_ Failed_ChargingProfileInvalid : 47|2@0+ (1,0) [0|3] "" MHU
  SG_ Error_message_4 : 49|2@0+ (1,0) [0|3] "" MHU
  SG_ Error_message_3 : 51|2@0+ (1,0) [0|3] "" MHU
  SG_ Error_message_1 : 53|2@0+ (1,0) [0|3] "" MHU
  SG_ Error_message_2 : 55|2@0+ (1,0) [0|3] "" MHU
  SG_ PnC_ChargeSessionEnded : 57|2@0+ (1,0) [0|3] "" MHU
  SG_ PnC_Status : 59|2@0+ (1,0) [0|3] "" MHU
  SG_ PnC_Contract_Status : 61|2@0+ (1,0) [0|3] "" MHU
  SG_ Error_message_5 : 63|2@0+ (1,0) [0|3] "" MHU

BO_ 312 ADAS_AVM_Sts: 8 ADAS_Info
  SG_ CHKSM_ADAS_AVM_Sts : 7|8@0+ (1,0) [0|255] "" MHU
  SG_ ALV_ADAS_AVM_Sts : 11|4@0+ (1,0) [0|14] "" MHU
  SG_ AVM_AutoDsplSts : 23|1@0+ (1,0) [0|1] "" MHU
  SG_ AVM_auxiliarylineSts : 40|1@0+ (1,0) [0|1] "-" MHU
  SG_ AVM_ShowAVMFdbck : 49|2@0+ (1,0) [0|3] "-" MHU
  SG_ AVM_Sts : 63|3@0+ (1,0) [0|7] "-" MHU

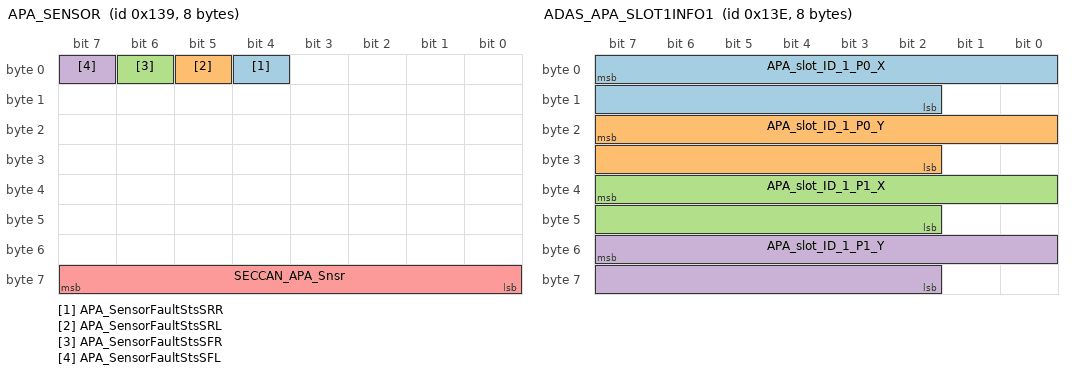
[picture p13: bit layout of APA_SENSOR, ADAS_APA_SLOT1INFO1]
BO_ 313 APA_SENSOR: 8 ADAS_Info
  SG_ APA_SensorFaultStsSRR : 4|1@0+ (1,0) [0|1] "-" MHU
  SG_ APA_SensorFaultStsSRL : 5|1@0+ (1,0) [0|1] "-" MHU
  SG_ APA_SensorFaultStsSFR : 6|1@0+ (1,0) [0|1] "-" MHU
  SG_ APA_SensorFaultStsSFL : 7|1@0+ (1,0) [0|1] "-" MHU
  SG_ SECCAN_APA_Snsr : 63|8@0+ (1,0) [0|255] "" MHU

BO_ 317 VCU_PnC_ErrorMsg_2: 8 XGW_Info
  SG_ SessionPaymentType : 7|2@0+ (1,0) [0|3] "" MHU

BO_ 318 ADAS_APA_SLOT1INFO1: 8 ADAS_Info
  SG_ APA_slot_ID_1_P0_X : 7|14@0+ (0.01,-80) [-80|83.3] "-" MHU
  SG_ APA_slot_ID_1_P0_Y : 23|14@0+ (0.01,-80) [-80|83.3] "-" MHU
  SG_ APA_slot_ID_1_P1_X : 39|14@0+ (0.01,-80) [-80|83.3] "-" MHU
  SG_ APA_slot_ID_1_P1_Y : 55|14@0+ (0.01,-80) [-80|83.3] "-" MHU

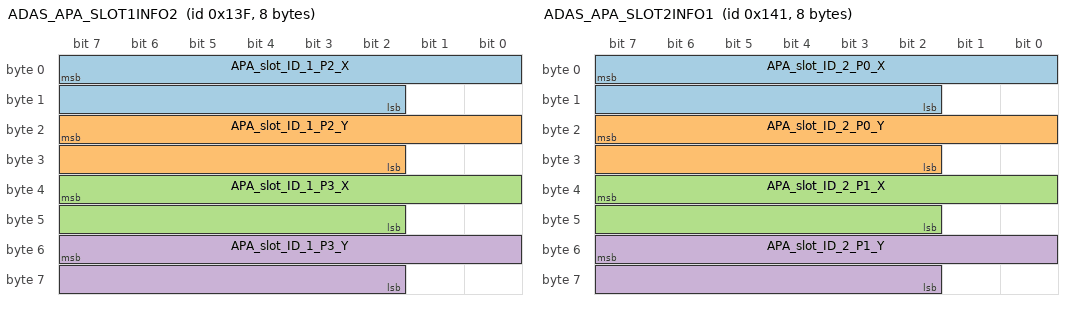
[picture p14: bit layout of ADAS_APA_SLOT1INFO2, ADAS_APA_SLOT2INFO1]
BO_ 319 ADAS_APA_SLOT1INFO2: 8 ADAS_Info
  SG_ APA_slot_ID_1_P2_X : 7|14@0+ (0.01,-80) [-80|83.3] "-" MHU
  SG_ APA_slot_ID_1_P2_Y : 23|14@0+ (0.01,-80) [-80|83.3] "-" MHU
  SG_ APA_slot_ID_1_P3_X : 39|14@0+ (0.01,-80) [-80|83.3] "-" MHU
  SG_ APA_slot_ID_1_P3_Y : 55|14@0+ (0.01,-80) [-80|83.3] "-" MHU

BO_ 320 ADAS_APA_SLOT1INFO3: 8 ADAS_Info
  SG_ APA_ParkingSlotType1 : 9|2@0+ (1,0) [0|3] "-" MHU
  SG_ APA_slot_1 : 39|8@0+ (1,0) [0|255] "-" MHU
  SG_ SECCAN_APA_Slot1Info : 63|8@0+ (1,0) [0|255] "" MHU

BO_ 321 ADAS_APA_SLOT2INFO1: 8 ADAS_Info
  SG_ APA_slot_ID_2_P0_X : 7|14@0+ (0.01,-80) [-80|83.3] "-" MHU
  SG_ APA_slot_ID_2_P0_Y : 23|14@0+ (0.01,-80) [-80|83.3] "-" MHU
  SG_ APA_slot_ID_2_P1_X : 39|14@0+ (0.01,-80) [-80|83.3] "-" MHU
  SG_ APA_slot_ID_2_P1_Y : 55|14@0+ (0.01,-80) [-80|83.3] "-" MHU

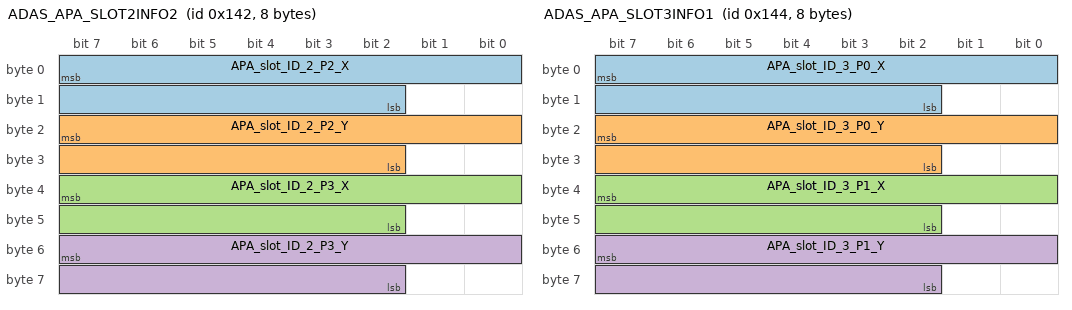
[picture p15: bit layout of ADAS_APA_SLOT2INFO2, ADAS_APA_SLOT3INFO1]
BO_ 322 ADAS_APA_SLOT2INFO2: 8 ADAS_Info
  SG_ APA_slot_ID_2_P2_X : 7|14@0+ (0.01,-80) [-80|83.3] "-" MHU
  SG_ APA_slot_ID_2_P2_Y : 23|14@0+ (0.01,-80) [-80|83.3] "-" MHU
  SG_ APA_slot_ID_2_P3_X : 39|14@0+ (0.01,-80) [-80|83.3] "-" MHU
  SG_ APA_slot_ID_2_P3_Y : 55|14@0+ (0.01,-80) [-80|83.3] "-" MHU

BO_ 323 ADAS_APA_SLOT2INFO3: 8 ADAS_Info
  SG_ APA_ParkingSlotType2 : 9|2@0+ (1,0) [0|3] "-" MHU
  SG_ APA_slot_2 : 39|8@0+ (1,0) [0|255] "-" MHU
  SG_ SECCAN_APA_Slot2Info : 63|8@0+ (1,0) [0|255] "" MHU

BO_ 324 ADAS_APA_SLOT3INFO1: 8 ADAS_Info
  SG_ APA_slot_ID_3_P0_X : 7|14@0+ (0.01,-80) [-80|83.3] "-" MHU
  SG_ APA_slot_ID_3_P0_Y : 23|14@0+ (0.01,-80) [-80|83.3] "-" MHU
  SG_ APA_slot_ID_3_P1_X : 39|14@0+ (0.01,-80) [-80|83.3] "-" MHU
  SG_ APA_slot_ID_3_P1_Y : 55|14@0+ (0.01,-80) [-80|83.3] "-" MHU

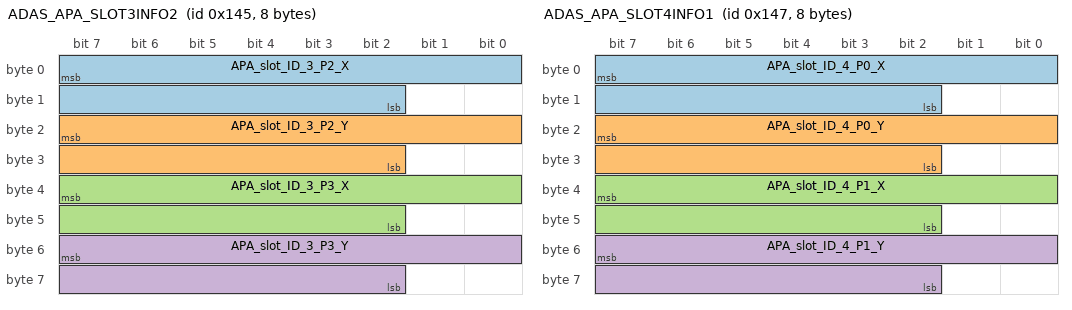
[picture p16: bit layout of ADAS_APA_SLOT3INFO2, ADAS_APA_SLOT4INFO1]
BO_ 325 ADAS_APA_SLOT3INFO2: 8 ADAS_Info
  SG_ APA_slot_ID_3_P2_X : 7|14@0+ (0.01,-80) [-80|83.3] "-" MHU
  SG_ APA_slot_ID_3_P2_Y : 23|14@0+ (0.01,-80) [-80|83.3] "-" MHU
  SG_ APA_slot_ID_3_P3_X : 39|14@0+ (0.01,-80) [-80|83.3] "-" MHU
  SG_ APA_slot_ID_3_P3_Y : 55|14@0+ (0.01,-80) [-80|83.3] "-" MHU

BO_ 326 ADAS_APA_SLOT3INFO3: 8 ADAS_Info
  SG_ APA_slot_3 : 39|8@0+ (1,0) [0|255] "-" MHU
  SG_ APA_ParkingSlotType3 : 52|2@0+ (1,0) [0|3] "-" MHU
  SG_ SECCAN_APA_Slot3Info : 63|8@0+ (1,0) [0|255] "" MHU

BO_ 327 ADAS_APA_SLOT4INFO1: 8 ADAS_Info
  SG_ APA_slot_ID_4_P0_X : 7|14@0+ (0.01,-80) [-80|83.3] "-" MHU
  SG_ APA_slot_ID_4_P0_Y : 23|14@0+ (0.01,-80) [-80|83.3] "-" MHU
  SG_ APA_slot_ID_4_P1_X : 39|14@0+ (0.01,-80) [-80|83.3] "-" MHU
  SG_ APA_slot_ID_4_P1_Y : 55|14@0+ (0.01,-80) [-80|83.3] "-" MHU

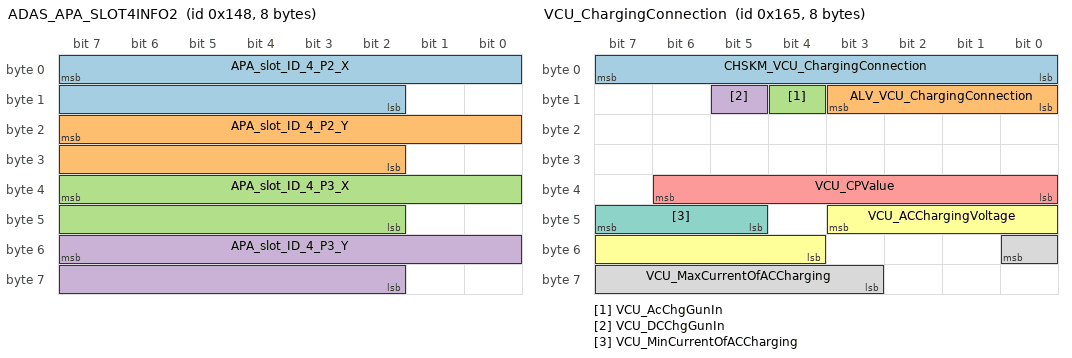
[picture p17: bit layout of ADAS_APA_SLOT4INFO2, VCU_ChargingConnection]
BO_ 328 ADAS_APA_SLOT4INFO2: 8 ADAS_Info
  SG_ APA_slot_ID_4_P2_X : 7|14@0+ (0.01,-80) [-80|83.3] "-" MHU
  SG_ APA_slot_ID_4_P2_Y : 23|14@0+ (0.01,-80) [-80|83.3] "-" MHU
  SG_ APA_slot_ID_4_P3_X : 39|14@0+ (0.01,-80) [-80|83.3] "-" MHU
  SG_ APA_slot_ID_4_P3_Y : 55|14@0+ (0.01,-80) [-80|83.3] "-" MHU

BO_ 329 ADAS_APA_SLOT4INFO3: 8 ADAS_Info
  SG_ APA_ParkingSlotType4 : 9|2@0+ (1,0) [0|3] "-" MHU
  SG_ APA_slot_4 : 39|8@0+ (1,0) [0|255] "-" MHU
  SG_ SECCAN_APA_Slot4Info : 63|8@0+ (1,0) [0|255] "" MHU

BO_ 330 ADAS_APA_SLOT5INFO1: 8 ADAS_Info
  SG_ APA_slot_ID_5_P0_X : 7|14@0+ (0.01,-80) [-80|83.3] "-" MHU
  SG_ APA_slot_ID_5_P0_Y : 23|14@0+ (0.01,-80) [-80|83.3] "-" MHU
  SG_ APA_slot_ID_5_P1_X : 39|14@0+ (0.01,-80) [-80|83.3] "-" MHU
  SG_ APA_slot_ID_5_P1_Y : 55|14@0+ (0.01,-80) [-80|83.3] "-" MHU

BO_ 331 ADAS_APA_SLOT5INFO2: 8 ADAS_Info
  SG_ APA_slot_ID_5_P2_X : 7|14@0+ (0.01,-80) [-80|83.3] "-" MHU
  SG_ APA_slot_ID_5_P2_Y : 23|14@0+ (0.01,-80) [-80|83.3] "-" MHU
  SG_ APA_slot_ID_5_P3_X : 39|14@0+ (0.01,-80) [-80|83.3] "-" MHU
  SG_ APA_slot_ID_5_P3_Y : 55|14@0+ (0.01,-80) [-80|83.3] "-" MHU

BO_ 332 ADAS_APA_SLOT5INFO3: 8 ADAS_Info
  SG_ APA_ParkingSlotType5 : 9|2@0+ (1,0) [0|3] "-" MHU
  SG_ APA_slot_5 : 39|8@0+ (1,0) [0|255] "-" MHU
  SG_ SECCAN_APA_Slot5Info : 63|8@0+ (1,0) [0|255] "" MHU

BO_ 333 ADAS_APA_SLOT6INFO1: 8 ADAS_Info
  SG_ APA_slot_ID_6_P0_X : 7|14@0+ (0.01,-80) [-80|83.3] "-" MHU
  SG_ APA_slot_ID_6_P0_Y : 23|14@0+ (0.01,-80) [-80|83.3] "-" MHU
  SG_ APA_slot_ID_6_P1_X : 39|14@0+ (0.01,-80) [-80|83.3] "-" MHU
  SG_ APA_slot_ID_6_P1_Y : 55|14@0+ (0.01,-80) [-80|83.3] "-" MHU

BO_ 334 ADAS_APA_SLOT6INFO2: 8 ADAS_Info
  SG_ APA_slot_ID_6_P2_X : 7|14@0+ (0.01,-80) [-80|83.3] "-" MHU
  SG_ APA_slot_ID_6_P2_Y : 23|14@0+ (0.01,-80) [-80|83.3] "-" MHU
  SG_ APA_slot_ID_6_P3_X : 39|14@0+ (0.01,-80) [-80|83.3] "-" MHU
  SG_ APA_slot_ID_6_P3_Y : 55|14@0+ (0.01,-80) [-80|83.3] "-" MHU

BO_ 335 ADAS_APA_SLOT6INFO3: 8 ADAS_Info
  SG_ APA_ParkingSlotType6 : 9|2@0+ (1,0) [0|3] "-" MHU
  SG_ APA_slot_6 : 39|8@0+ (1,0) [0|255] "-" MHU
  SG_ SECCAN_APA_Slot6Info : 63|8@0+ (1,0) [0|255] "" MHU

BO_ 357 VCU_ChargingConnection: 8 XGW_Info
  SG_ CHSKM_VCU_ChargingConnection : 7|8@0+ (1,0) [0|255] "" MHU
  SG_ ALV_VCU_ChargingConnection : 11|4@0+ (1,0) [0|14] "" MHU
  SG_ VCU_AcChgGunIn : 12|1@0+ (1,0) [0|1] "-" MHU
  SG_ VCU_DCChgGunIn : 13|1@0+ (1,0) [0|1] "-" MHU
  SG_ VCU_CPValue : 38|7@0+ (1,0) [0|100] "%" MHU
  SG_ VCU_ACChargingVoltage : 43|8@0+ (1,0) [0|255] "V" MHU
  SG_ VCU_MinCurrentOfACCharging : 47|3@0+ (1,0) [0|7] "A" MHU
  SG_ VCU_MaxCurrentOfACCharging : 48|6@0+ (1,0) [0|63] "A" MHU

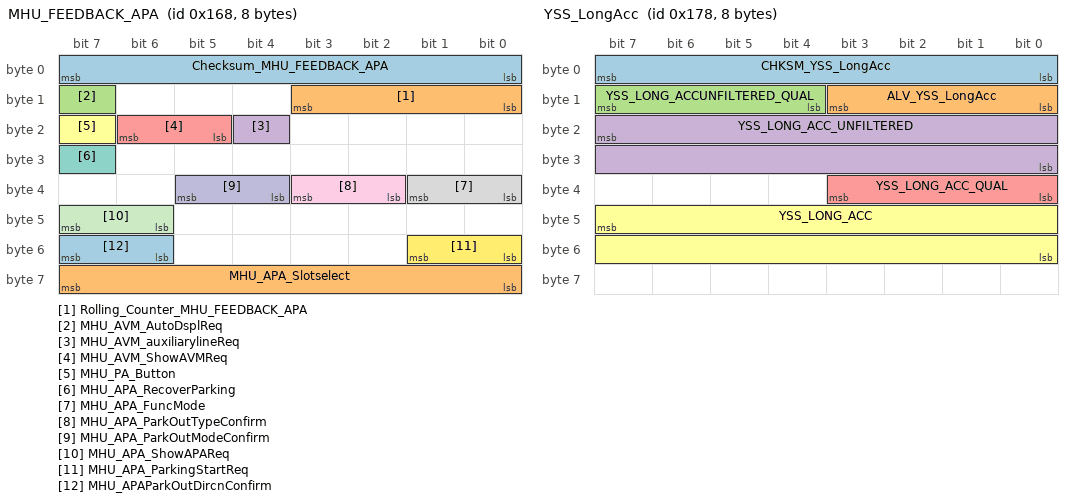
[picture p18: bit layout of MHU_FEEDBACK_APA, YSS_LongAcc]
BO_ 360 MHU_FEEDBACK_APA: 8 MHU
  SG_ Checksum_MHU_FEEDBACK_APA : 7|8@0+ (1,0) [0|255] "" ADAS_Info
  SG_ Rolling_Counter_MHU_FEEDBACK_APA : 11|4@0+ (1,0) [0|14] "" ADAS_Info
  SG_ MHU_AVM_AutoDsplReq : 15|1@0+ (1,0) [0|1] "" ADAS_Info
  SG_ MHU_AVM_auxiliarylineReq : 20|1@0+ (1,0) [0|1] "-" ADAS_Info
  SG_ MHU_AVM_ShowAVMReq : 22|2@0+ (1,0) [0|3] "-" ADAS_Info
  SG_ MHU_PA_Button : 23|1@0+ (1,0) [0|1] "-" ADAS_Info
  SG_ MHU_APA_RecoverParking : 31|1@0+ (1,0) [0|1] "-" ADAS_Info
  SG_ MHU_APA_FuncMode : 33|2@0+ (1,0) [0|3] "-" ADAS_Info
  SG_ MHU_APA_ParkOutTypeConfirm : 35|2@0+ (1,0) [0|3] "-" ADAS_Info
  SG_ MHU_APA_ParkOutModeConfirm : 37|2@0+ (1,0) [0|3] "-" ADAS_Info
  SG_ MHU_APA_ShowAPAReq : 47|2@0+ (1,0) [0|3] "-" ADAS_Info
  SG_ MHU_APA_ParkingStartReq : 49|2@0+ (1,0) [0|3] "-" ADAS_Info
  SG_ MHU_APAParkOutDircnConfirm : 55|2@0+ (1,0) [0|3] "-" ADAS_Info
  SG_ MHU_APA_Slotselect : 63|8@0+ (1,0) [0|255] "-" ADAS_Info

BO_ 372 BMS_CurMeas: 8 XGW_Info
  SG_ CHSKM_BMS_CurMeas : 7|8@0+ (1,0) [0|255] "" MHU
  SG_ ALV_BMS_CurMeas : 11|4@0+ (1,0) [0|14] "" MHU
  SG_ BMS_PackCur_MEAS : 23|16@0+ (0.1,-3276.8) [-3276.8|3276.7] "A" MHU

BO_ 374 BMS_HVMeas1: 8 XGW_Info
  SG_ Checksum_0x176 : 7|8@0+ (1,0) [0|255] "" MHU
  SG_ Rolling_Counter_0x176 : 11|4@0+ (1,0) [0|14] "" MHU
  SG_ BMS_HVPackVol_MEAS : 23|16@0+ (0.1,0) [0|800] "V" MHU
  SG_ BMS_HVLinkVol_MEAS : 39|16@0+ (0.1,0) [0|800] "V" MHU

BO_ 376 YSS_LongAcc: 8 XGW_Info
  SG_ CHKSM_YSS_LongAcc : 7|8@0+ (1,0) [0|255] "" MHU
  SG_ ALV_YSS_LongAcc : 11|4@0+ (1,0) [0|14] "" MHU
  SG_ YSS_LONG_ACCUNFILTERED_QUAL : 15|4@0+ (1,0) [0|15] "" MHU
  SG_ YSS_LONG_ACC_UNFILTERED : 23|16@0+ (0.002,-65.532) [-65.532|65.532] "m/s2" MHU
  SG_ YSS_LONG_ACC_QUAL : 35|4@0+ (1,0) [0|15] "" MHU
  SG_ YSS_LONG_ACC : 47|16@0+ (0.002,-65.532) [-65.532|65.532] "m/s2" MHU

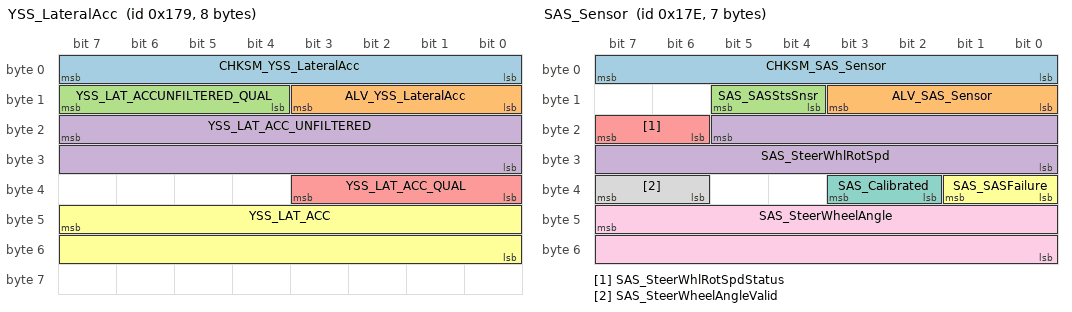
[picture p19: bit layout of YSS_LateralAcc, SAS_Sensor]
BO_ 377 YSS_LateralAcc: 8 XGW_Info
  SG_ CHKSM_YSS_LateralAcc : 7|8@0+ (1,0) [0|255] "" MHU
  SG_ ALV_YSS_LateralAcc : 11|4@0+ (1,0) [0|14] "" MHU
  SG_ YSS_LAT_ACCUNFILTERED_QUAL : 15|4@0+ (1,0) [0|15] "" MHU
  SG_ YSS_LAT_ACC_UNFILTERED : 23|16@0+ (0.002,-65.532) [-65.532|65.532] "m/s2" MHU
  SG_ YSS_LAT_ACC_QUAL : 35|4@0+ (1,0) [0|15] "" MHU
  SG_ YSS_LAT_ACC : 47|16@0+ (0.002,-65.532) [-65.532|65.532] "m/s2" MHU

BO_ 382 SAS_Sensor: 7 XGW_Info
  SG_ CHKSM_SAS_Sensor : 7|8@0+ (1,0) [0|255] "" HUD,MHU
  SG_ ALV_SAS_Sensor : 11|4@0+ (1,0) [0|14] "" HUD,MHU
  SG_ SAS_SASStsSnsr : 13|2@0+ (1,0) [0|1] "-" HUD,MHU
  SG_ SAS_SteerWhlRotSpd : 21|14@0+ (0.125,-1024) [-1024|1023.875] "degree/s" HUD,MHU
  SG_ SAS_SteerWhlRotSpdStatus : 23|2@0+ (1,0) [0|1] "" HUD,MHU
  SG_ SAS_SASFailure : 33|2@0+ (1,0) [0|1] "" HUD,MHU
  SG_ SAS_Calibrated : 35|2@0+ (1,0) [0|1] "" HUD,MHU
  SG_ SAS_SteerWheelAngleValid : 39|2@0+ (1,0) [0|1] "" HUD,MHU
  SG_ SAS_SteerWheelAngle : 47|16@0+ (0.0238,-780) [-780|779.7] "deg" HUD,MHU

BO_ 385 VCU_Debug: 8 XGW_Info
 SG_ VCU_Debug1 : 7|8@0+ (1,0) [0|255] ""  MHU
 SG_ VCU_Debug2 : 15|8@0+ (1,0) [0|255] ""  MHU
 SG_ VCU_Debug3 : 23|8@0+ (1,0) [0|255] ""  MHU
 SG_ VCU_Debug4 : 27|5@0+ (1,0) [0|31] ""  MHU

CM_ "This dbc file for FRS build";
CM_ BU_ ADAS_Info "Advance Driver Assistance System";
CM_ BU_ AMP "Amplifier";
CM_ BU_ CPD "Child Presence Detection";
CM_ BU_ EASC "Electric Ajustment Steering Column";
CM_ BU_ HUD "Head Up Display";
CM_ BU_ MHU "Media Head Unit";
CM_ BU_ XGW_Info "Gateway";
CM_ BO_ 18 "MHU_Climate_control";
CM_ BO_ 128 "ADAS_TSR_STATUS";
CM_ BO_ 130 "ADAS_CMP_MHU";
CM_ BO_ 133 "ACM Message for crash details";
CM_ BO_ 147 "Mileage information ";
CM_ BO_ 149 "EPBi Function";
CM_ BO_ 150 "IDB select mode from MHU";
CM_ BO_ 217 "High Voltage Drive System Status";
CM_ BO_ 241 "IDB Recu Brake Torque Request";
CM_ BO_ 256 "MHU_Vehicle_Info";
CM_ BO_ 257 "MHU request Message";
CM_ BO_ 258 "Logical Clamp status for  Vehicle";
CM_ BO_ 259 "BCM Energy Management";
CM_ BO_ 260 "Actual name BCM_LVBAT_COM_INFO";
CM_ BO_ 261 "BCM door flap state";
CM_ BO_ 262 "BCM LIGHT";
CM_ BO_ 263 "BCM Status Central Lock";
CM_ BO_ 265 "BCM switches status";
CM_ BO_ 266 "Low Voltage Battery";
CM_ BO_ 267 "TRM_LIGHT";
CM_ BO_ 268 "GW_BCM_RemoteCtrlSts";
CM_ BO_ 269 "MHU_BCM_DoorsCtrl";
CM_ BO_ 270 "BCM ENTRY CONTROLBCM Entry Control";
CM_ BO_ 271 "MHU_BCM_HornLightControl";
CM_ BO_ 274 "Clamp status for BEV vehicle";
CM_ BO_ 276 "For Li-ion LV Battery only";
CM_ BO_ 277 "BCM_Childlock";
CM_ BO_ 282 "MHU_ServiceMode_Setting";
CM_ BO_ 283 "MHU_BCM_RemoteClampCtrl";
CM_ BO_ 284 "MHU_BCM_FOTAClampCtrl";
CM_ BO_ 291 "VCU ACCharging Info.";
CM_ BO_ 292 "VCU DCCharging Info.";
CM_ BO_ 294 "MHU_ISA_Speed_Setting";
CM_ BO_ 295 "ADAS Lane Departure Warning and Lane Keeping Assist";
CM_ BO_ 296 "ADAS Forward Collision and Rear Cross Traffic Alert  Warning";
CM_ BO_ 297 "MHU LOCAL SETTING";
CM_ BO_ 303 "BCM Terminal for vehicle";
CM_ BO_ 304 "ADAS Automatic Emergency Brake";
CM_ BO_ 307 "ADAS Blind Sport Detection";
CM_ BO_ 308 "Disaplay and speed status";
CM_ BO_ 310 "MHU_PnC_trigger";
CM_ BO_ 311 "VCU_PnC_Error";
CM_ BO_ 312 "AVM signals";
CM_ BO_ 313 "APA Sensor Status";
CM_ BO_ 317 "VCU_PnC_Error";
CM_ BO_ 318 "APA Slot 1 info 1 signals";
CM_ BO_ 319 "APA Slot 1 info 2 signals";
CM_ BO_ 320 "APA Slot 1 info 3 Signals";
CM_ BO_ 321 "APA Slot 2 info 1 signals";
CM_ BO_ 322 "APA Slot 2 info 2 signals";
CM_ BO_ 323 "APA Slot 2 info 3 signals";
CM_ BO_ 324 "APA Slot 3 info 1 signals";
CM_ BO_ 325 "APA Slot 3 info 2 signals";
CM_ BO_ 326 "APA Slot 3 info 3 signals";
CM_ BO_ 327 "APA Slot 4 Info 1 Signals";
CM_ BO_ 328 "APA Slot 4 Info 2 Signals";
CM_ BO_ 329 "APA Slot 4 Info 3 Signals";
CM_ BO_ 330 "APA Slot 5 info 1 signals";
CM_ BO_ 331 "APA Slot 5 info 2 signals";
CM_ BO_ 332 "APA Slot 5 info 3 signals";
CM_ BO_ 333 "APA Slot 6 info 1 signals";
CM_ BO_ 334 "APA Slot 6 info 2 signals";
CM_ BO_ 335 "APA Slot 6 info 3 signals";
CM_ BO_ 357 "Charging connection ";
CM_ BO_ 360 "MHU and T-Box Feedback signals";
CM_ BO_ 372 "BMS CurMeas";
CM_ BO_ 374 "BMS high voltage measurement";
CM_ BO_ 376 "YSS_LongAcc";
CM_ BO_ 377 "YSS_LateralAcc";
CM_ BO_ 382 "Steering angle sensor";
CM_ BO_ 385 "VCU_Debug";
CM_ SG_ 18 CPD_MHU_Climate_control "CPD request open climate";
CM_ SG_ 128 CHKSM_ADAS_TSR_STATUS "Checksum";
CM_ SG_ 128 ALV_ADAS_TSR_Status "Alive Counter";
CM_ SG_ 128 ADAS_TSR_PopUp_Feed "PopUP Messaging for TSR function";
CM_ SG_ 128 ADAS_TSR_SLAert_Feed "Feedback of TSR Speed Limit Alert select";
CM_ SG_ 128 ADAS_TSR_Typ2_value "Traffic Sign conditional speed limit value";
CM_ SG_ 128 ADAS_TSR_Typ1 "Traffic Sign Speed Type";
CM_ SG_ 128 ADAS_TSR_Typ1_value "Traffic Sign Speed value";
CM_ SG_ 128 ADAS_TSR_Warning_audible "Speed limit warning";
CM_ SG_ 128 ADAS_TSR_Typ2_Flashing_Warning "Traffic Sign Type 2 warning";
CM_ SG_ 128 ADAS_TSR_Mode_Feed "Traffic Sign Recognition Mode Feedback";
CM_ SG_ 128 ADAS_TSR_AudWarning_Feed "Feedback of TSR Audible Warning On Off";
CM_ SG_ 128 ADAS_TSR_Typ1_Flashing_Warning "Speed limit warning";
CM_ SG_ 128 ADAS_TSR_Typ3 "Traffic Sign Type detected";
CM_ SG_ 128 ADAS_TSR_Typ2 "Traffic Sign minimun Speed Type";
CM_ SG_ 128 ADAS_TSR_State "Traffic Sign Recognition Mode Feedback";
CM_ SG_ 130 CHKSM_ADAS_CMP_MHU "Checksum";
CM_ SG_ 130 ALV_ADAS_CMP_MHU "Alive Counter";
CM_ SG_ 130 ADAS_TakeOver_Request "Request Driver Take Over Request for ADAS Function";
CM_ SG_ 130 ADAS_Sounds_Feed "Sounds Feedback Request for ADAS function";
CM_ SG_ 130 SECCAN_ADAS_CMP_MHU "Secret portion from Secure CAN algorithm";
CM_ SG_ 133 CHKSM_CRASH_Sts "Checksum";
CM_ SG_ 133 ALV_CRASH_Sts "Alive Counter";
CM_ SG_ 133 ACM_Crash_Sts "Crash status";
CM_ SG_ 133 ACM_Airbag_Deployment_Status "Signal to indicate if airbag pretensioner pyrofuse is deployed";
CM_ SG_ 133 ACM_Crash_Intensity "Indicate crash intensity level";
CM_ SG_ 133 ACM_Front_Crash "Output information for direction of crash";
CM_ SG_ 133 ACM_DriverSide_Crash "Output information for direction of crash";
CM_ SG_ 133 ACM_PassSide_Crash "Output information for direction of crash";
CM_ SG_ 133 ACM_Rear_Crash "Output information for direction of crash";
CM_ SG_ 133 ACM_Rollover_Crash "Output information for direction of crash";
CM_ SG_ 147 CHKSM_MILEAGE "Checksum";
CM_ SG_ 147 ALIVE_MILEAGE "Alive counter";
CM_ SG_ 147 Mileage "Mileage";
CM_ SG_ 149 CHKSM_IDB_FUNCTION "Checksum";
CM_ SG_ 149 ALV_IDB_FUNCTION "Alive counter";
CM_ SG_ 149 STAT_ABS "ABS Status";
CM_ SG_ 149 AYC_Active "Active yaw control";
CM_ SG_ 149 ASR_Active "ASR Traction Control active";
CM_ SG_ 149 STAT_DSC "Dynamic Stability Control status";
CM_ SG_ 149 DSC_Active "DSC function active.";
CM_ SG_ 149 HBA_ActiveSignal "HBA active signal";
CM_ SG_ 149 ARM_ActiveSignal "ARM active signal";
CM_ SG_ 149 STAT_AutoHazardBlinking "Indicates IDB/ABS emergency brake";
CM_ SG_ 149 MSR_Active "engine drag torque control active";
CM_ SG_ 149 HSA_ActiveSignal "HSA active signal, It will set to 0x1: Active when HHC activated, it will set back to 0x0:Inactive when HHC not active or deactivated.";
CM_ SG_ 149 EPBi_ECD_ActiveSignal "this signal indicates EPBi active or not after EPBi receives ECD request";
CM_ SG_ 149 TSM_Active "TSM Active";
CM_ SG_ 149 HAS_Available "HAS Hill Hold Available";
CM_ SG_ 149 STAT_EBD "EBD Electronic Brake Distribution Status";
CM_ SG_ 149 EBD_Active "EBD function active.";
CM_ SG_ 149 ST_BRG_MSA "Prediction of whether the vehicle is held by the DSC at v = 0 km/h. (Receiver: EMS)";
CM_ SG_ 150 CHKSM_MHU_IDB_Mode_Select "Checksum";
CM_ SG_ 150 ALV_MHU_IDB_Mode_Select "Alive counter";
CM_ SG_ 150 MHU_IDB_Mode_Select_Signal "Select mode for IDB";
CM_ SG_ 217 CRC_VCU_HV_DrvSys_status "Checksum";
CM_ SG_ 217 ALIV_VCU_HV_DrvSys_status "Alive counter";
CM_ SG_ 217 VCU_HVsystem_status "High Voltage system status";
CM_ SG_ 217 VCU_ACPD_Percent "The signal contains the actual angle of the acceleration pedal100% acceleration pedal position shall only provided in case of kick down.Without kickdown the maximum value shall be 99.";
CM_ SG_ 217 VCU_ACPD_Percent_Valid "Qualifier for corresponding signal.  In value table not defined values are reserved";
CM_ SG_ 217 VCU_ACTGear "actual gear,Provide gear shift signal";
CM_ SG_ 217 VCU_ACTGearValid "Indicate the current gear position
";
CM_ SG_ 217 VCU_ACT_DriveMode "Vehicle drive mode";
CM_ SG_ 217 VCU_ACT_DriveMode_Valid "Vehicle drive mode status";
CM_ SG_ 217 VCU_HV_DRVsystem_status "Status of driving system ( Highvoltage )";
CM_ SG_ 217 VCU_Recu_BrakeLight_ON_Req "VCU request brake light ON when regen";
CM_ SG_ 241 CRC_RecuBrakeTorqueRequest "Checksum";
CM_ SG_ 241 ALIV_RecuBrakeTorqueRequest "Alive counter";
CM_ SG_ 241 IDB_RecuBrakeTorqueRequest_FR "The signal shows the recuperation torque request of the brake system (FR)";
CM_ SG_ 241 IDB_RecuBrakeTorqueRequest_RR "The signal shows the recuperation torque request of the brake system (RR)";
CM_ SG_ 241 IDB_RecuBrakeControl_Sts "Regen cooperation control enable status of IDB
This signal that IDB system is possible to regenerative braking cooperation control including status of VCU(Regen enable status of motor).";
CM_ SG_ 241 IDB_RecuBrkTorqueReq_Sts "Indicate Regenerative Braking function is active or not
This signal that regen cooperation is controlling(Target Regen Torque > 0)";
CM_ SG_ 241 IDB_Brake_Pedal_position "Brake pedal position";
CM_ SG_ 241 IDB_Brake_Pedal_position_sts "Qualifier for corresponding signal of Brake pedal position";
CM_ SG_ 256 CHKSM_MHU_VEH_INFO "Checksum";
CM_ SG_ 256 ALV_MHU_VEH_INFO "Alive Counter";
CM_ SG_ 256 MHU_UserProfileId "User profile ID, support 10 user profiles in maxinum, 0xF is invalid signal";
CM_ SG_ 256 MHU_Connectivity_Status "Internet Connection Connectivity Status";
CM_ SG_ 257 DMS_Setting "MHU request change warning responsiveness";
CM_ SG_ 257 DMS_Driver_registration_request "MHU request identification or delete user";
CM_ SG_ 257 DMS_Driver_ID_request "MHU send ID that need to be registed or deleted";
CM_ SG_ 257 DMS_Status "MHU request turn on/off DMS status";
CM_ SG_ 257 DMS_Image_processing "MHU confirm about received Image processing";
CM_ SG_ 257 DMS_DriverConfirmDMSWarning "MHU send Okay signal to confirm DMS warning promp pop-up";
CM_ SG_ 257 SECCAN_DMS "Seed portion from Secure CAN algorithm";
CM_ SG_ 258 CHKSM_BCM_LOGICAL_CLAMP "Checksum";
CM_ SG_ 258 ALIVE_BCM_LOGICAL_CLAMP "Alive counter";
CM_ SG_ 258 STAT_CL30s_Light_L "Logical clamp status";
CM_ SG_ 258 STAT_CL30s_L "Status Clamp 30s Logical ON/OFF";
CM_ SG_ 258 STAT_CL15Wup_L "Status Clamp 15 WakeUp Signal Logical";
CM_ SG_ 258 STAT_CrankRelayHW_BCM "Represents the status of the starter relais";
CM_ SG_ 259 REQ_ConsumerControlWirelessCharg "Consumer control WLC  for powermanagement";
CM_ SG_ 259 REQ_ConsumerControlAudioVolumeCo "Consumer control audio volume for powermanagement";
CM_ SG_ 259 REQ_ConsumerControlRearDefrost "Consumer control rear defrost for powermanagement";
CM_ SG_ 259 REQ_ConsumerControlSeatHeatingRe "Consumer control rear seat heating  for powermanagement";
CM_ SG_ 259 REQ_ConsumerControlSeatVentilati "Consumer control seat venting for powermanagement";
CM_ SG_ 259 REQ_ConsumerControlSeatHeatingFr "Consumer control front seat heating  for powermanagement";
CM_ SG_ 259 DriverIdealTimerCount "Driver Ideal Timer Counter";
CM_ SG_ 259 REQ_ConsumerControlVentilationCl "Consumer control  ventilation (blower control clima) for powermanagement";
CM_ SG_ 260 CHKSM_LV_BATT_CHARG "Checksum
";
CM_ SG_ 260 ALIV_LV_BATT_CHARG "Alive counter
";
CM_ SG_ 260 SOH_SUL "Actual name LV_SOH (State of Health)";
CM_ SG_ 260 SOH_SUL_STATE "Actual name LV_SOH_Sts (SOH Status)
";
CM_ SG_ 260 SOC_STATE "SOC Status";
CM_ SG_ 260 Resp_Error "Resp_Error";
CM_ SG_ 260 FLAG_INCONSTENCY "Battery inconsistency flag
";
CM_ SG_ 260 EBS_error "EBS error
";
CM_ SG_ 260 FLAG_DISCONNECT "Battery disconnection flag

";
CM_ SG_ 260 BCM_LV_Batt_Charging_Req "BCM_LV_REQ";
CM_ SG_ 260 IBATT_QUIESCENT "IBATT_QUIESCENT ";
CM_ SG_ 261 CHKSM_BCM_STAT_DOOR_FLAP "Checksum";
CM_ SG_ 261 ALIVE_BCM_STAT_DOOR_FLAP "Alive counter";
CM_ SG_ 261 BCM_STAT_TrunkAjar "Trunk Ajar Door Status";
CM_ SG_ 261 BCM_STAT_DoorAjarFL "Ajar Door Front Left Status";
CM_ SG_ 261 BCM_STAT_DoorAjarFR "Ajar Door Front Right Status";
CM_ SG_ 261 BCM_STAT_DoorAjarRL "Ajar Door Rear Left Status";
CM_ SG_ 261 BCM_STAT_DoorAjarRR "Ajar Door Rear Right Status";
CM_ SG_ 261 BCM_STAT_BonnetAjar "Ajar Bonnet Status";
CM_ SG_ 262 CHKSM_BCM_LIGHT "Checksum";
CM_ SG_ 262 ALIVE_BCM_LIGHT "Alive counter";
CM_ SG_ 262 BCM_DayRunningLampSts "DayRunning Lamp output Status";
CM_ SG_ 262 BCM_ReverseLightSts "Reverse light output Status";
CM_ SG_ 262 BCM_StopLightSts "Stop light output Status";
CM_ SG_ 262 BCM_LicensePlateLightSts "License plate light output";
CM_ SG_ 262 BCM_Fr_Dimming_dome_lampSts "Dimming dome lamp Front Status";
CM_ SG_ 262 BCM_Rr_Dimming_dome_lampSts "Dimming dome lamp Rear Status";
CM_ SG_ 262 BCM_STAT_InteriorLight "Status for functional illumination in the interior light switch button";
CM_ SG_ 262 BCM_STAT_LightActivation "Status of light ";
CM_ SG_ 262 BCM_HighBeamSts "High beam output Status";
CM_ SG_ 262 BCM_STAT_SwitchLightBrightness "Confirm Brighness level of Switch illumination";
CM_ SG_ 262 BCM_LowBeamSts "Low beam output  Status";
CM_ SG_ 262 BCM_RearFogLmpSts "Rear fog output Status";
CM_ SG_ 262 BCM_FrntFogLmpSts "Front fog output Status";
CM_ SG_ 262 BCM_PosLmpSts "Position light output Status";
CM_ SG_ 262 BCM_HornSts "Horn output Status";
CM_ SG_ 262 BCM_TurnIndicatorSts "Turn light output  Status";
CM_ SG_ 263 CHKSM_BCM_CENTRAL_LOCK "Checksum ";
CM_ SG_ 263 ALV_BCM_CENTRAL_LOCK "Alive counter";
CM_ SG_ 263 STAT_CDL_LED "Status of functional CDL button LED, value 2 represents implausible state";
CM_ SG_ 263 STAT_DoorUnlockFL "UnLock Status Driver Door not used for lock status";
CM_ SG_ 263 STAT_ATWS "Locking/UnLocking Status Anti theft Invalid value = 7";
CM_ SG_ 263 STAT_DoorLockFL "Lock Status Driver Door used as central lock information";
CM_ SG_ 265 CHKSM_BCM_SWITCH_Sts "Checksum";
CM_ SG_ 265 ALV_BCM_SWITCH_Sts "Alive counter";
CM_ SG_ 265 BCM_STAT_BrakeSwitch "Brake pedal switch BCM pressed (only for brake light)";
CM_ SG_ 265 BCM_STAT_HazardWarn "Hazard Warning switch activation";
CM_ SG_ 265 BCM_STAT_FuelPumpCutOFF "Status Fuel Pump cut off by crash";
CM_ SG_ 265 BCM_FollowMeHomeActive "BCM_FollowMeHomeActive";
CM_ SG_ 265 BCM_STAT_Horn "Status switch horn";
CM_ SG_ 265 BCM_STAT_Autowiping "Status for Autowiping ON /OFF";
CM_ SG_ 265 BCM_TurnIndicator "BCM_TurnIndicator";
CM_ SG_ 265 BCM_WelcomeActive "BCM Welcome Active";
CM_ SG_ 265 BCM_HighBeam "BCM_High beam ";
CM_ SG_ 265 ACM_Seat_Belt_Status_3rd_Row_Pas "Seatbelt status for seatbelt reminder function for 3rd Row Pass";
CM_ SG_ 265 ACM_Seat_Belt_Status_3rd_Row_Dri "Seatbelt status for seatbelt reminder function for 3rd Row Driver";
CM_ SG_ 266 CHKSM_BCM_VOLTAGE "Checksum";
CM_ SG_ 266 ALIVE_BCM_VOLTAGE "Alive counter";
CM_ SG_ 266 UBatt "Battery Voltage";
CM_ SG_ 266 LV_Batt_Temp "Low voltage Battery Temperature";
CM_ SG_ 266 LV_SOC "State Of charge for Low Voltage Battery";
CM_ SG_ 266 LV_Batt_Current "Current of Low Voltage Battery";
CM_ SG_ 266 LV_BatteryType "LV Battery Type (Lead Acid or Lithium)";
CM_ SG_ 267 ALIVE_TRM_LIGHT "Alive counter rolling counter of the message if it's over 14 then will swap back to 0 and increase again. Invalid Value = F";
CM_ SG_ 267 TrailerInput "Trailer synchronization confirmation with HW/SW";
CM_ SG_ 267 TrailerSystemError "Trailer error detection";
CM_ SG_ 267 TRM_VoltageStatus "Trailer voltage status";
CM_ SG_ 267 TRM_STAT_BrakeLight "Trailer Brake light status";
CM_ SG_ 267 TRM_STAT_FogLampRear "Trailer Rear fog lamp status";
CM_ SG_ 267 TRM_STAT_PositionLight "Trailer Position light status";
CM_ SG_ 267 TRM_STAT_TurnIndicators "Trailer Turn Indicatiors status";
CM_ SG_ 267 TRM_STAT_ReverseLight "Trailer Reverse light status";
CM_ SG_ 267 TRM_STAT_HWBrakeLightInput "Trailer hardwired Brake light inputstatus";
CM_ SG_ 267 TRM_STAT_HWIndicatorInput "Trailer hardwired Turn Indicatiors input status";
CM_ SG_ 267 TRM_STAT_HWPosLightInput "Trailer hardwired Position light input status";
CM_ SG_ 268 Checksum_0x10C "Checksum";
CM_ SG_ 268 Rolling_Counter_0x10C "Rolling_Counter";
CM_ SG_ 268 BCM_TboxAuthStatus "MHU's TBOX authentication status";
CM_ SG_ 268 BCM_RandomNum32bit "BCM's random OTP 32 bits and refresh every 20 secs";
CM_ SG_ 269 MHU_APM_ReqWindow "Request control Window from MHU";
CM_ SG_ 269 MHU_BCM_RemoteDoorCtrl "MHU set door state remotely.";
CM_ SG_ 269 MHU_BCM_reqTrunk "MHU Set Trunk Ajar Door or Tailgate";
CM_ SG_ 269 MHU_BCM_reqFrunk "MHU unlock frunk or bonnet";
CM_ SG_ 269 MHU_BCM_ReqSunroof "MHU open sunroof by percentage value";
CM_ SG_ 269 TBOX_AuthCode_0x10D "TBOX Message Authentication Code of message 0x10D";
CM_ SG_ 270 RemoteAccessKey "Status of remote key button Tailgate opening long press > 1.5 sec;";
CM_ SG_ 270 PassiveAccessTrunk "BCM request for passive entry trunk";
CM_ SG_ 270 ComfortOpen "Doorhandle or RKE request for comfort open.";
CM_ SG_ 270 PassiveAccessDoor "BCM request for passive entry door";
CM_ SG_ 270 FksOpen "The signal is send by BCM after BCM confirms that the vehilce should let PTG open";
CM_ SG_ 271 MHU_SetHornOnOff "Set horn ON/OFF";
CM_ SG_ 271 MHU_SetLowBeam "Set low beam light ON/FF";
CM_ SG_ 271 MHU_SetHighBeam "Set high beam light ON/FF";
CM_ SG_ 271 TBOX_AuthCode_0x10F "TBOX Message Authentication Code of message 0x10F";
CM_ SG_ 274 CHKSM_BCM_CLAMP_STAT "Checksum";
CM_ SG_ 274 ALIVE_BCM_CLAMP_STAT "Alive counter";
CM_ SG_ 274 RemoteFunctionState "0x1(remote function) will be sent after PreRemoteStart=0x1 first time in ignition OFF state, and this signal will be kept 0x1 until SESAM exit remote state.";
CM_ SG_ 274 STAT_BLS "Signal represent plausibility of both HW Inputs for brake light switch.";
CM_ SG_ 274 STAT_CL_50_L "Logical clamp status";
CM_ SG_ 274 Clamp50AdviceRemoteStart "Engine Start announcement (Clamp 50) for remote start";
CM_ SG_ 274 Clamp50AdviceESS "Engine Start announcement (Clamp 50) for ESS";
CM_ SG_ 274 STAT_CL_R_L "Logical clamp status";
CM_ SG_ 274 STAT_CL_15_1_L "Logical clamp status";
CM_ SG_ 274 STAT_CL_15_1_DME_L "Logical clamp status";
CM_ SG_ 274 FobId "Information of FOB ID.";
CM_ SG_ 274 STAT_Terminal "Represent the status of physical terminal";
CM_ SG_ 274 STAT_CL30_C_BEV "Logical clamp status";
CM_ SG_ 274 BCM_Clamp_Transport "BCM_Clamp_Transport";
CM_ SG_ 276 CHKSM_LVBAT_DATA "Checksum";
CM_ SG_ 276 ALIV_LVBAT_DATA "Alive counter";
CM_ SG_ 276 LV_ErrorSts "LV Error status";
CM_ SG_ 276 LV_MinCellVolt "Min cell voltage";
CM_ SG_ 276 LV_MaxCellVolt "Max cell voltage";
CM_ SG_ 276 LV_MinCellTemp "Min cell temperature";
CM_ SG_ 276 LV_MaxCellTemp "Max cell temperature";
CM_ SG_ 276 LV_Discharger_Err "Discharge contactor (MOSFET) malfunction";
CM_ SG_ 276 LV_Discharger_Sts "The charge MOSFET status: Close/Open";
CM_ SG_ 276 LV_Charger_Err "Charge contactor (MOSFET) malfunction";
CM_ SG_ 276 LV_Charger_Sts "The discharge MOSFET status: Close/Open";
CM_ SG_ 276 LV_OverVoltage "Over voltage flag";
CM_ SG_ 276 LV_UnderVoltage "Under voltage flag";
CM_ SG_ 276 LV_OverCurrent "Over current flag";
CM_ SG_ 276 LV_UnderTemp "Under temperature flag";
CM_ SG_ 276 LV_OverTemp "Over temperature flag";
CM_ SG_ 276 LV_OverCharge "Over charge";
CM_ SG_ 276 LV_OverDischarge "Over discharge";
CM_ SG_ 276 LV_CellBalance_Sts "Cell balance operation status";
CM_ SG_ 276 LV_CellBalance_Error "Cell balance error status";
CM_ SG_ 276 LV_ThermalRunaway "Thermal runaway warning";
CM_ SG_ 277 BCM_ChildLock_Feedback "Response for Childlock Status
";
CM_ SG_ 282 MHU_SET_WiperServicePositionMod "MHU request BCM to keyfob on the center comtrol to link this key to user profile";
CM_ SG_ 282 MHU_Read_KeyFobOnCenterConsole "MHU request BCM to keyfob on the center comtrol to link this key to user profile";
CM_ SG_ 283 TBOX_STAT_TerminalReq "CAR state switching request";
CM_ SG_ 283 TBOX_AuthCode_0x11B "TBOX Message Authentication Code of message";
CM_ SG_ 284 TBOX_FOTA_STAT_TerminalReq "CAR state switching request for FOTA";
CM_ SG_ 291 CHKSM_ACChargingInfo "Checksum";
CM_ SG_ 291 ALIVE_ACChargingInfo "Alive counter";
CM_ SG_ 291 ACCharging_MaxChargingPower "Max  Power of AC Charging gun.";
CM_ SG_ 291 CurrentACChargingPower "Nominal power from AC charnge gun";
CM_ SG_ 291 ACCharging_MaxCurrent "Max current of AC Charging gun";
CM_ SG_ 292 CHKSM_DCChargingInfo "Checksum";
CM_ SG_ 292 ALIVE_DCChargingInfo "Alive counter";
CM_ SG_ 292 DCCharging_MaxChargingPower "Max power from the DC charging gun";
CM_ SG_ 292 CurrentDCChargingPower "Nominal power output from DC charge gun";
CM_ SG_ 292 DCCharging_MaxCurrent "Max current from the DC charging gun";
CM_ SG_ 294 MHU_ISA_SpeedLimitCon_Percent "Speed Limit Control Off Setting Percentage";
CM_ SG_ 294 MHU_ISA_Speed_Setting "Speed Limit Control Offset setting KPH or MPH";
CM_ SG_ 295 CHKSM_ADAS_LDW_LKA "Checksum";
CM_ SG_ 295 ALV_ADAS_LDW_LKA "Alive Counter";
CM_ SG_ 295 ADAS_Mode1_status "System mode: Mode 1 & 2";
CM_ SG_ 295 ADAS_LKA_HOD_state "Hands On and Off status";
CM_ SG_ 295 ADAS_ECU_check "ADAS ECU fault";
CM_ SG_ 295 ADAS_LA_sens_Feed "Sensitivity Feedback";
CM_ SG_ 295 ADAS_LKA_ICON_Feed "ICON Feedback Request for LKA function";
CM_ SG_ 295 ADAS_LDW_check "Lane Departure Warning Check";
CM_ SG_ 295 ADAS_LKA_check "Lans Keeping Assist Check";
CM_ SG_ 295 ADAS_ALC_ICON_Feed "ICON Feedback Request for ALC function";
CM_ SG_ 295 ADAS_LA_popup "Lane assist function popup message
0: No popup
1: Hand off warning, please take the steering wheel
2. Take control! Vehicle departing lane\
3. Emergency steering was engaged for your safety
4: reserved
5: reserved";
CM_ SG_ 295 ADAS_LA_AudWarning_Feed "Setting Audible warning for LA On off feed";
CM_ SG_ 295 ADAS_LA_Mode_Feed "Feedback of LA mode select (From MHU setting)";
CM_ SG_ 295 ADAS_HWA_ICON_Feed "ICON Feedback Request for HWA function";
CM_ SG_ 295 ADAS_LA_veh_pos_right "Vehicle position? to right lane";
CM_ SG_ 295 ADAS_LA_veh_pos_left "Vehicle position? to left lane";
CM_ SG_ 296 CHKSM_ADAS_FCW_RCTA "Checksum";
CM_ SG_ 296 ALV_ADAS_FCW_RCTA "Alive Counter";
CM_ SG_ 296 ADAS_RCTA_IndLeft "Left Rear Cross Traffic Alert (RCTA) System Warning";
CM_ SG_ 296 ADAS_RCTA_IndRight "Right Rear Cross Traffic Alert (RCTA) System Warning ";
CM_ SG_ 296 ADAS_RCTA_SndWarn "Rear Cross Traffic Alert warning sound en disable";
CM_ SG_ 296 ADAS_IA_check "Intersection Assist State Check";
CM_ SG_ 296 ADAS_RCTA_state "Rear Cross Traffic Alert  Warning State";
CM_ SG_ 296 ADAS_RCTA_sens_Feed "Rear Cross Traffic Alert  Warning Sensitivity Feedback";
CM_ SG_ 296 ADAS_IA_Left_warning "Intersecion assist left warning";
CM_ SG_ 296 ADAS_FCW_Mode_Feed "Forward Collision Warning  Mode select";
CM_ SG_ 296 ADAS_FCW_Sens_Feed "Forward Collision Warning Sensitivity";
CM_ SG_ 296 ADAS_FCW_state "Forward Collision Warning State";
CM_ SG_ 296 ADAS_IA_state "Intersection Assist State";
CM_ SG_ 296 ADAS_FCW_check "Forward Collision Warning Check";
CM_ SG_ 296 ADAS_IA_Right_warning "Intersecion assist right warning";
CM_ SG_ 296 ADAS_IA_Mode_Feed "Intersection Assist State  Mode select";
CM_ SG_ 296 ADAS_RCTA_check "Rear Cross Traffic Alert Check";
CM_ SG_ 296 ADAS_RCTA_Mode_Feed "Rear Cross Traffic Alert  Warning On Off Feedback";
CM_ SG_ 296 ADAS_FCW_warning "Forward Collision Warning Warning popup";
CM_ SG_ 296 ADAS_LA_LeftLaneColor_Feed "Color of LEFT lane for Lane Assist function";
CM_ SG_ 296 ADAS_LA_RightLaneColor_Feed "Color of RIGHT lane for Lane Assist function";
CM_ SG_ 297 CHKSM_MHU_LocalSetting "Checksum";
CM_ SG_ 297 ALIVE_MHU_LocalSetting "Alive Counter";
CM_ SG_ 297 MHU_SETTING_DMSWarning "DMS warning setting to HUD";
CM_ SG_ 297 MHU_STAT_SelectedCountry "Current selected country  encoding by ISO 3166-1 numeric";
CM_ SG_ 303 CHKSM_BCM_TERMINAL "Checksum";
CM_ SG_ 303 ALV_BCM_TERMINAL "Alive counter";
CM_ SG_ 303 ST_KL "Clamp status";
CM_ SG_ 303 ST_KL_KEY_VLD "Key valid";
CM_ SG_ 303 ST_STCD_PENG "Plausibility signal for starter release";
CM_ SG_ 303 ST_SSB "Status of Start Stop Button";
CM_ SG_ 303 RWDT_BLS "Raw data Brake light switch";
CM_ SG_ 303 RQ_DRVG_RDI "Engine start advice (will be send out before the engine start)";
CM_ SG_ 303 CTR_ENG_STOP "This signal allows the engine to be switched off without removing the ignition (KL15). ";
CM_ SG_ 303 ST_VEH_CON "The signal is formed from the current klemme state, the engine running status and the vehicle movement. It also shows whether the vehicle is in washline mode. Attention: This signal only evaluates the condition of the internal combustion engine.";
CM_ SG_ 304 CHKSM_ADAS_AEB "Checksum";
CM_ SG_ 304 ALV_ADAS_AEB "Alive Counter";
CM_ SG_ 304 ADAS_AEB_State "Automatic Emergency Brake State";
CM_ SG_ 304 ADAS_RAEB_check "Rear Automatic Emergency Brake Check";
CM_ SG_ 304 ADAS_AEB_check "Automatic Emergency Brake Check";
CM_ SG_ 304 ADAS_AEB_Mode_Feed "AAEB Mode feedback";
CM_ SG_ 304 ADAS_RAEB_Mode_Feed "Rear Automatic Emergency Brake  Mode select";
CM_ SG_ 304 ADAS_AEB_Warning "Automatic Emergency Brake Warning Mode ";
CM_ SG_ 304 ADAS_RAEB_Warning "Rear Automatic Emergency Brake warning";
CM_ SG_ 304 ADAS_RAEB_State "Rear Automatic Emergency Brake State";
CM_ SG_ 307 CHKSM_ADAS_BSD "Checksum";
CM_ SG_ 307 ALV_ADAS_BSD "Alive Counter";
CM_ SG_ 307 ADAS_BSD_check "Blind Sport Detection Check";
CM_ SG_ 307 ADAS_BSD_state "Blind Sport Detection State Feedback";
CM_ SG_ 307 ADAS_BSD_AudChime_Feed "Blind Sport Detection Audible Chime Feedback ";
CM_ SG_ 307 ADAS_BSD_IndLeft "Left Blind Sport Detection Warning";
CM_ SG_ 307 ADAS_BSD_IndRight "Right Blind Sport Detection Warning";
CM_ SG_ 307 ADAS_BSD_SndWarn "Rear Blind Sport Detection warning sound en disable";
CM_ SG_ 307 ADAS_BSD_Mode_Feed "Blind Sport Detection On Off Feedback ";
CM_ SG_ 307 ADAS_BSD_sens_Feed "Blind Sport Detection sensitivity Feedback ";
CM_ SG_ 308 CHKSM_ADAS_Speed_Display "Checksum";
CM_ SG_ 308 ALV_ADAS_Speed_Display "Alive Counter";
CM_ SG_ 308 ADAS_ISA_SpeedLimitCnt_Spd_Feed "Speed Limit Control Offset setting KPH or MPH Feedback";
CM_ SG_ 308 ADAS_ISA_SpeedLimitCnt_Per_Feed "Speed Limit Control Off Setting Percentage Feedback";
CM_ SG_ 308 ADAS_far_lane_info "status of far right and far left lane";
CM_ SG_ 310 PnC_activation "To activate and deactivate the PnC from MHU";
CM_ SG_ 310 PnCandEIM_Switch "To switch between EIM and PNC from MHU";
CM_ SG_ 310 PnC_trigger1 "Reserved trigger 1";
CM_ SG_ 310 PnC_trigger2 "Reserved trigger 2";
CM_ SG_ 310 PnC_Cert_Del "To delete the stored certificates in the VCU ";
CM_ SG_ 310 PnC_feature_enable "To enable and disable the feature";
CM_ SG_ 311 OK_OldSessionJoined "To inform about the old session when Session request is successful and same session id as used in the request message is contained in the response message";
CM_ SG_ 311 OK_NewSessionEstablished "To inform about the new session when Session request is successful and different session id is contained in the response message than the session id in request message";
CM_ SG_ 311 OK_CertificateExpireSoon "Your contract certificate is about to expire, you can extend your contract on the PnC Menu.
";
CM_ SG_ 311 PnC_OK "PnC connection successful 
";
CM_ SG_ 311 Failed_CertificateNoAllowAtEVSE "To activate and deactivate the PnC from MHU.
";
CM_ SG_ 311 Failed_ContactorError "To activate and deactivate the PnC from MHU
";
CM_ SG_ 311 Failed_NoChargeServiceSelectd "To inform about requested service with service ID value equal to one which was not in PaymentService SelectionReq and was offered by SECC";
CM_ SG_ 311 PnC_Failed "PnC connection unsuccessful. Please try again.
";
CM_ SG_ 311 Failed_ServiceIDInvalid "if service id is not part of the offered service list during service directory

";
CM_ SG_ 311 Falied_UnknownSession "To describe the Session ID is not equal to Session ID stored for the currently active V2G comm session 
";
CM_ SG_ 311 Failed_SignatureError "The security element validation failure in message header";
CM_ SG_ 311 Failed_SequenceError "To inform that the SECC has received an unexpected request message";
CM_ SG_ 311 Failed_CertChainError "To inform that the ContractSignatureCertChain contained in the CertificateInstallation request message is not Valid";
CM_ SG_ 311 Failed_NoCertificateAvailable "To inform that new certificate can not be retrieved from secondary actor within V2G_SECC_Msg_Performance_Time according to table 109 of ISO standard";
CM_ SG_ 311 Failed_CertificateRevoked "To activate and deactivate the PnC from MHU";
CM_ SG_ 311 Failed_PaymentSelectionInvalid "If the selected payment option contained in the PaymentServiceSelectionRequest message wa not part of the offered paymentOption list 

";
CM_ SG_ 311 Failed_WrongChargeParameter "To inform that the content of attribute 'EVChargeParameter in the ChargeParameterDiscoveryReq message is not valid, e.g. wrong parameter set is provided, one or multiple parameters cannot be interpreted. 

";
CM_ SG_ 311 Failed_WrongEnergyTranferMode "To inform that the content of";
CM_ SG_ 311 Failed_ChallengeInvalid "To inform that the challenge response contained in the AuthorizationReq message in attribute GenChallenge";
CM_ SG_ 311 Failed_ContractCancelled "To inform that EMAID provided by EVCC during certificateUpdateReq is not accepted by secondary actor.

";
CM_ SG_ 311 Failed_MeteringSignatureNotValid "To inform when the SECC is not able to validate the signature, or the contained meter reading does not fit to the provided meter reading during 'ChargingStatusRes' and the SECC requires that the signature is valid";
CM_ SG_ 311 Failed_PowerDeliverNotApplied "To inform when the EVSE is not able to deliver energy

";
CM_ SG_ 311 Failed_TarrifSelectionInvalid "To inform that the the content of attribute 'ChargingProfile' in the PowerDeliveryReq message contains a SAtuplelD which was not contained in the 'SASchedules' attribute provided in 'ChargeParameterDiscoveryReS";
CM_ SG_ 311 Failed_ChargingProfileInvalid "To inform that the content of attribute 'ChargingProfile' in the PowerDeliveryReq message violates a power limitation provided in 'ChargeParameterDiscoveryRes'";
CM_ SG_ 311 Error_message_4 "Reserved message 4
";
CM_ SG_ 311 Error_message_3 "Reserved message 3

";
CM_ SG_ 311 Error_message_1 "Reserved message 1 

";
CM_ SG_ 311 Error_message_2 "Reserved message 2";
CM_ SG_ 311 PnC_ChargeSessionEnded "To inform the User about charging session ended";
CM_ SG_ 311 PnC_Status "To inform that PnC is enabled or disabled to user


";
CM_ SG_ 311 PnC_Contract_Status "Reserved message 6
";
CM_ SG_ 311 Error_message_5 "Reserved message 5";
CM_ SG_ 312 CHKSM_ADAS_AVM_Sts "Checksum";
CM_ SG_ 312 ALV_ADAS_AVM_Sts "Alive Counter";
CM_ SG_ 312 AVM_AutoDsplSts "Auto Display SVM when turn left or right with limit speed ";
CM_ SG_ 312 AVM_auxiliarylineSts "Open and closed state of auxiliary wire";
CM_ SG_ 312 AVM_ShowAVMFdbck "AVM start feedback signal";
CM_ SG_ 312 AVM_Sts "AVM Status";
CM_ SG_ 313 APA_SensorFaultStsSRR "side right rear ultrasonic sensor failure";
CM_ SG_ 313 APA_SensorFaultStsSRL "side left rear ultrasonic sensor failure";
CM_ SG_ 313 APA_SensorFaultStsSFR "side right front ultrasonic sensor failure";
CM_ SG_ 313 APA_SensorFaultStsSFL "side left front ultrasonic sensor failure";
CM_ SG_ 313 SECCAN_APA_Snsr "Secret portion from Secure CAN algorithm";
CM_ SG_ 317 SessionPaymentType "To inform the MHU whether the PnC or EIM is active
";
CM_ SG_ 318 APA_slot_ID_1_P0_X "Point P0 coordinate of slot1";
CM_ SG_ 318 APA_slot_ID_1_P0_Y "Point P0 coordinate of slot1";
CM_ SG_ 318 APA_slot_ID_1_P1_X "Point P1 coordinate of slot1";
CM_ SG_ 318 APA_slot_ID_1_P1_Y "Point P1 coordinate of slot1";
CM_ SG_ 319 APA_slot_ID_1_P2_X "Point P2 coordinate of slot1";
CM_ SG_ 319 APA_slot_ID_1_P2_Y "Point P2 coordinate of slot1";
CM_ SG_ 319 APA_slot_ID_1_P3_X "Point P3 coordinate of slot1";
CM_ SG_ 319 APA_slot_ID_1_P3_Y "Point P3 coordinate of slot1";
CM_ SG_ 320 APA_ParkingSlotType1 "Type of  slot1";
CM_ SG_ 320 APA_slot_1 "slot_ID";
CM_ SG_ 320 SECCAN_APA_Slot1Info "Secret portion from Secure CAN algorithm";
CM_ SG_ 321 APA_slot_ID_2_P0_X "Point P0 coordinate of slot2";
CM_ SG_ 321 APA_slot_ID_2_P0_Y "Point P0 coordinate of slot2";
CM_ SG_ 321 APA_slot_ID_2_P1_X "Point P1 coordinate of slot2";
CM_ SG_ 321 APA_slot_ID_2_P1_Y "Point P1 coordinate of slot2";
CM_ SG_ 322 APA_slot_ID_2_P2_X "Point P2 coordinate of slot2";
CM_ SG_ 322 APA_slot_ID_2_P2_Y "Point P2 coordinate of slot2";
CM_ SG_ 322 APA_slot_ID_2_P3_X "Point P3 coordinate of slot2";
CM_ SG_ 322 APA_slot_ID_2_P3_Y "Point P3 coordinate of slot2";
CM_ SG_ 323 APA_ParkingSlotType2 "Type of  slot2";
CM_ SG_ 323 APA_slot_2 "slot_ID";
CM_ SG_ 323 SECCAN_APA_Slot2Info "Secret portion from Secure CAN algorithm";
CM_ SG_ 324 APA_slot_ID_3_P0_X "Point P0 coordinate of slot3";
CM_ SG_ 324 APA_slot_ID_3_P0_Y "Point P0 coordinate of slot3";
CM_ SG_ 324 APA_slot_ID_3_P1_X "Point P1 coordinate of slot3";
CM_ SG_ 324 APA_slot_ID_3_P1_Y "Point P1 coordinate of slot3";
CM_ SG_ 325 APA_slot_ID_3_P2_X "Point P2 coordinate of slot3";
CM_ SG_ 325 APA_slot_ID_3_P2_Y "Point P2 coordinate of slot3";
CM_ SG_ 325 APA_slot_ID_3_P3_X "Point P3 coordinate of slot3";
CM_ SG_ 325 APA_slot_ID_3_P3_Y "Point P3 coordinate of slot3";
CM_ SG_ 326 APA_slot_3 "slot_ID";
CM_ SG_ 326 APA_ParkingSlotType3 "Type of  slot3";
CM_ SG_ 326 SECCAN_APA_Slot3Info "Secret portion from Secure CAN algorithm";
CM_ SG_ 327 APA_slot_ID_4_P0_X "Point P0 coordinate of slot4";
CM_ SG_ 327 APA_slot_ID_4_P0_Y "Point P0 coordinate of slot4";
CM_ SG_ 327 APA_slot_ID_4_P1_X "Point P1 coordinate of slot4";
CM_ SG_ 327 APA_slot_ID_4_P1_Y "Point P1 coordinate of slot4";
CM_ SG_ 328 APA_slot_ID_4_P2_X "Point P2 coordinate of slot4";
CM_ SG_ 328 APA_slot_ID_4_P2_Y "Point P2 coordinate of slot4";
CM_ SG_ 328 APA_slot_ID_4_P3_X "Point P3 coordinate of slot4";
CM_ SG_ 328 APA_slot_ID_4_P3_Y "Point P3 coordinate of slot4";
CM_ SG_ 329 APA_ParkingSlotType4 "Type of  slot4";
CM_ SG_ 329 APA_slot_4 "slot_ID";
CM_ SG_ 329 SECCAN_APA_Slot4Info "Secret portion from Secure CAN algorithm";
CM_ SG_ 330 APA_slot_ID_5_P0_X "Point P0 coordinate of slot5";
CM_ SG_ 330 APA_slot_ID_5_P0_Y "Point P0 coordinate of slot5";
CM_ SG_ 330 APA_slot_ID_5_P1_X "Point P1 coordinate of slot5";
CM_ SG_ 330 APA_slot_ID_5_P1_Y "Point P1 coordinate of slot5";
CM_ SG_ 331 APA_slot_ID_5_P2_X "Point P2 coordinate of slot5";
CM_ SG_ 331 APA_slot_ID_5_P2_Y "Point P2 coordinate of slot5";
CM_ SG_ 331 APA_slot_ID_5_P3_X "Point P3 coordinate of slot5";
CM_ SG_ 331 APA_slot_ID_5_P3_Y "Point P3 coordinate of slot5";
CM_ SG_ 332 APA_ParkingSlotType5 "Type of  slot5";
CM_ SG_ 332 APA_slot_5 "slot_ID";
CM_ SG_ 332 SECCAN_APA_Slot5Info "Secret portion from Secure CAN algorithm";
CM_ SG_ 333 APA_slot_ID_6_P0_X "Point P0 coordinate of slot6";
CM_ SG_ 333 APA_slot_ID_6_P0_Y "Point P0 coordinate of slot6";
CM_ SG_ 333 APA_slot_ID_6_P1_X "Point P1 coordinate of slot6";
CM_ SG_ 333 APA_slot_ID_6_P1_Y "Point P1 coordinate of slot6";
CM_ SG_ 334 APA_slot_ID_6_P2_X "Point P2 coordinate of slot6";
CM_ SG_ 334 APA_slot_ID_6_P2_Y "Point P2 coordinate of slot6";
CM_ SG_ 334 APA_slot_ID_6_P3_X "Point P3 coordinate of slot6";
CM_ SG_ 334 APA_slot_ID_6_P3_Y "Point P3 coordinate of slot6";
CM_ SG_ 335 APA_ParkingSlotType6 "Type of  slot6";
CM_ SG_ 335 APA_slot_6 "slot_ID";
CM_ SG_ 335 SECCAN_APA_Slot6Info "Secret portion from Secure CAN algorithm";
CM_ SG_ 357 CHSKM_VCU_ChargingConnection "Checksum";
CM_ SG_ 357 ALV_VCU_ChargingConnection "Alive Counter";
CM_ SG_ 357 VCU_AcChgGunIn "Slow Charge Gun Insert Status ";
CM_ SG_ 357 VCU_DCChgGunIn "Connection status of DC Fast charging Gun";
CM_ SG_ 357 VCU_CPValue "Charging port duty Cycle value (PWM)";
CM_ SG_ 357 VCU_ACChargingVoltage "The Power of this AC charging connection in KW";
CM_ SG_ 357 VCU_MinCurrentOfACCharging "Minium Charging current of this AC Charging connection";
CM_ SG_ 357 VCU_MaxCurrentOfACCharging "Maximum Charging current of AC Charging";
CM_ SG_ 360 Checksum_MHU_FEEDBACK_APA "Checksum";
CM_ SG_ 360 Rolling_Counter_MHU_FEEDBACK_APA "Roling counter
";
CM_ SG_ 360 MHU_AVM_AutoDsplReq "Auto Display SVM when turn left or right with limit speed 15kph setting request";
CM_ SG_ 360 MHU_AVM_auxiliarylineReq "Guideline status setting";
CM_ SG_ 360 MHU_AVM_ShowAVMReq "request AVM Active";
CM_ SG_ 360 MHU_PA_Button "PA Active button pressed";
CM_ SG_ 360 MHU_APA_RecoverParking "APA Parking Recovery Request";
CM_ SG_ 360 MHU_APA_FuncMode "Functional mode request";
CM_ SG_ 360 MHU_APA_ParkOutTypeConfirm "APA park out type confirmation";
CM_ SG_ 360 MHU_APA_ParkOutModeConfirm "APA park out mode confirmation";
CM_ SG_ 360 MHU_APA_ShowAPAReq "Request to turn on APA functionality";
CM_ SG_ 360 MHU_APA_ParkingStartReq "Begin parking request";
CM_ SG_ 360 MHU_APAParkOutDircnConfirm "park out direction is confirmed";
CM_ SG_ 360 MHU_APA_Slotselect "Parking choice ID";
CM_ SG_ 372 CHSKM_BMS_CurMeas "Checksum";
CM_ SG_ 372 ALV_BMS_CurMeas "Alive Counter";
CM_ SG_ 372 BMS_PackCur_MEAS "Battery Pack Total Current";
CM_ SG_ 374 Checksum_0x176 "Checksum";
CM_ SG_ 374 Rolling_Counter_0x176 "Rolling Counter";
CM_ SG_ 374 BMS_HVPackVol_MEAS "Pack Voltage";
CM_ SG_ 374 BMS_HVLinkVol_MEAS "Link Voltage";
CM_ SG_ 376 CHKSM_YSS_LongAcc "Checksum";
CM_ SG_ 376 ALV_YSS_LongAcc "Alive Counter";
CM_ SG_ 376 YSS_LONG_ACCUNFILTERED_QUAL "This signal contains the physical value of the Longitudinal acceleration with 0.002m/s2 LSB.";
CM_ SG_ 376 YSS_LONG_ACC_UNFILTERED "This signal contains the physical value of the Longitudinal acceleration with 0.002m/s2 LSB.";
CM_ SG_ 376 YSS_LONG_ACC_QUAL "This signal contains the qualifier of the Longitudinal acceleration.";
CM_ SG_ 376 YSS_LONG_ACC "This signal contains the physical value of the Longitudinal acceleration with 0.002m/s2 LSB.";
CM_ SG_ 377 CHKSM_YSS_LateralAcc "Checksum";
CM_ SG_ 377 ALV_YSS_LateralAcc "Alive Counter";
CM_ SG_ 377 YSS_LAT_ACCUNFILTERED_QUAL "This signal contains the qualifier of the Lateral acceleration.";
CM_ SG_ 377 YSS_LAT_ACC_UNFILTERED "This signal contains the physical value of the Lateral acceleration with 0.002m/s2 LSB.";
CM_ SG_ 377 YSS_LAT_ACC_QUAL "This signal contains the qualifier of the Lateral acceleration.";
CM_ SG_ 377 YSS_LAT_ACC "This signal contains the physical value of the Lateral acceleration with 0.002m/s2 LSB.";
CM_ SG_ 382 CHKSM_SAS_Sensor "Checksum";
CM_ SG_ 382 ALV_SAS_Sensor "Alive Counter";
CM_ SG_ 382 SAS_SASStsSnsr "The flag of  SAS status Punch Steering angle status";
CM_ SG_ 382 SAS_SteerWhlRotSpd "The current rotation speed of the steering wheel.";
CM_ SG_ 382 SAS_SteerWhlRotSpdStatus "The status of SteerWheelRotSpd";
CM_ SG_ 382 SAS_SASFailure "Angle sensor disabled.";
CM_ SG_ 382 SAS_Calibrated "SAS calibration state";
CM_ SG_ 382 SAS_SteerWheelAngleValid "Effective signal for steering angle";
CM_ SG_ 382 SAS_SteerWheelAngle "The current angle of the steering wheel(Positive, to left; Negative, to right)";
CM_ SG_ 385 VCU_Debug1 "PUPD_state";
CM_ SG_ 385 VCU_Debug2 "Charging Status";
CM_ SG_ 385 VCU_Debug3 "Termal Status";
CM_ SG_ 385 VCU_Debug4 "VCU Diagnostic System Error Level";

BA_DEF_ BO_  "GenMsgSendType" ENUM "Cyclic","NotUsed","NotUsed","NotUsed","NotUsed","NotUsed","NotUsed","IfActive","NoMsgSendType","NotUsed";
BA_DEF_ BO_  "GenMsgILSupport" ENUM "No","Yes";
BA_DEF_ BO_  "DiagResponse" ENUM "No","Yes";
BA_DEF_ BO_  "DiagRequest" ENUM "No","Yes";
BA_DEF_ BO_  "NmAsrMessage" ENUM "No","Yes";
BA_DEF_ BO_  "DiagState" ENUM "No","Yes";
BA_DEF_ BO_  "DiagUudtResponse" ENUM "False","True";
BA_DEF_ BO_  "GenMsgStartDelayTime" INT 0 65535;
BA_DEF_ BO_  "GenMsgDelayTime" INT 0 0;
BA_DEF_ BO_  "GenMsgNrOfRepetition" INT 0 0;
BA_DEF_ BO_  "GenMsgCycleTimeFast" INT 0 0;
BA_DEF_ BO_  "GenMsgCycleTime" INT 0 0;
BA_DEF_ BU_  "NmStationAddress" HEX 0 0;
BA_DEF_ BU_  "Address" HEX 0 255;
BA_DEF_ BU_  "TpSTMin" INT 0 255;
BA_DEF_ BU_  "ILUsed" ENUM "No","Yes";
BA_DEF_ BU_  "NmAsrNode" ENUM "No","Yes";
BA_DEF_ BU_  "NmAsrNodeIdentifier" HEX 0 255;
BA_DEF_ BU_  "NmAsrCanMsgCycleOffset" INT 0 65535;
BA_DEF_ BU_  "NmAsrCanMsgReducedTime" INT 320 640;
BA_DEF_ SG_  "GenSigSendType" ENUM "Cyclic","OnWrite","OnWriteWithRepetition","OnChange","OnChangeWithRepetition","IfActive","IfActiveWithRepetition","NoSigSendType","NotUsed","NotUsed","NotUsed","NotUsed","NotUsed";
BA_DEF_ SG_  "InvalidValue" STRING;
BA_DEF_ SG_  "GenSigStartValue" INT 0 0;
BA_DEF_ SG_  "GenSigTimeoutTime_ALL" INT 0 65535;
BA_DEF_  "DBName" STRING;
BA_DEF_  "NmAsrBaseAddress" HEX 0 2047;
BA_DEF_  "NmAsrMessageCount" INT 1 256;
BA_DEF_  "NmAsrTimeoutTime" INT 0 65535;
BA_DEF_  "NmAsrWaitBusSleepTime" INT 0 65535;
BA_DEF_  "NmAsrRepeatMessageTime" INT 0 65535;
BA_DEF_  "NmAsrCanMsgCycleTime" INT 0 65535;
BA_DEF_  "Baudrate" INT 0 1000000;
BA_DEF_  "BusType" STRING;
BA_DEF_  "NmType" STRING;
BA_DEF_  "Manufacturer" STRING;
BA_DEF_ BU_  "ECU" STRING;

BA_DEF_DEF_  "Address" 0;
BA_DEF_DEF_  "Baudrate" 500000;
BA_DEF_DEF_  "DiagRequest" "No";
BA_DEF_DEF_  "DiagResponse" "No";
BA_DEF_DEF_  "DiagState" "No";
BA_DEF_DEF_  "DiagUudtResponse" "False";
BA_DEF_DEF_  "ECU" "";
BA_DEF_DEF_  "GenMsgCycleTime" 0;
BA_DEF_DEF_  "GenMsgCycleTimeFast" 0;
BA_DEF_DEF_  "GenMsgDelayTime" 0;
BA_DEF_DEF_  "GenMsgILSupport" "Yes";
BA_DEF_DEF_  "GenMsgNrOfRepetition" 0;
BA_DEF_DEF_  "GenMsgSendType" "NoMsgSendType";
BA_DEF_DEF_  "GenMsgStartDelayTime" 0;
BA_DEF_DEF_  "GenSigSendType" "Cyclic";
BA_DEF_DEF_  "GenSigStartValue" 0;
BA_DEF_DEF_  "GenSigTimeoutTime_ALL" 0;
BA_DEF_DEF_  "ILUsed" "Yes";
BA_DEF_DEF_  "Manufacturer" "VinFast";
BA_DEF_DEF_  "NmAsrBaseAddress" 1280;
BA_DEF_DEF_  "NmAsrCanMsgCycleOffset" 0;
BA_DEF_DEF_  "NmAsrCanMsgCycleTime" 640;
BA_DEF_DEF_  "NmAsrCanMsgReducedTime" 320;
BA_DEF_DEF_  "NmAsrMessage" "No";
BA_DEF_DEF_  "NmAsrMessageCount" 128;
BA_DEF_DEF_  "NmAsrNode" "Yes";
BA_DEF_DEF_  "NmAsrNodeIdentifier" 0;
BA_DEF_DEF_  "NmAsrRepeatMessageTime" 3200;
BA_DEF_DEF_  "NmAsrTimeoutTime" 2000;
BA_DEF_DEF_  "NmAsrWaitBusSleepTime" 1500;
BA_DEF_DEF_  "NmStationAddress" 0;
BA_DEF_DEF_  "TpSTMin" 20;

BA_ "BusType" "CAN";
BA_ "DBName" "Info";
BA_ "NmType" "NmAsr";
BA_ "Address" BU_ ADAS_Info 64;
BA_ "ECU" BU_ ADAS_Info "ADAS_InfoCAN";
BA_ "NmAsrNodeIdentifier" BU_ ADAS_Info 64;
BA_ "NmStationAddress" BU_ ADAS_Info 64;
BA_ "Address" BU_ AMP 5;
BA_ "ECU" BU_ AMP "AMP__D_";
BA_ "NmAsrNodeIdentifier" BU_ AMP 5;
BA_ "NmStationAddress" BU_ AMP 5;
BA_ "Address" BU_ CPD 47;
BA_ "ECU" BU_ CPD "CPD";
BA_ "NmAsrCanMsgCycleOffset" BU_ CPD 235;
BA_ "NmAsrNodeIdentifier" BU_ CPD 47;
BA_ "NmStationAddress" BU_ CPD 47;
BA_ "ECU" BU_ DUMMY_DEBUG "DUMMY_DEBUG";
BA_ "ECU" BU_ DUMMY_ECU "DUMMY_ECU";
BA_ "Address" BU_ EASC 73;
BA_ "ECU" BU_ EASC "EASC";
BA_ "NmAsrCanMsgCycleOffset" BU_ EASC 365;
BA_ "NmAsrNodeIdentifier" BU_ EASC 73;
BA_ "NmStationAddress" BU_ EASC 73;
BA_ "Address" BU_ HUD 13;
BA_ "ECU" BU_ HUD "HUD";
BA_ "NmAsrCanMsgCycleOffset" BU_ HUD 65;
BA_ "NmAsrNodeIdentifier" BU_ HUD 13;
BA_ "NmStationAddress" BU_ HUD 13;
BA_ "Address" BU_ MHU 4;
BA_ "ECU" BU_ MHU "MHU";
BA_ "NmAsrCanMsgCycleOffset" BU_ MHU 20;
BA_ "NmAsrCanMsgReducedTime" BU_ MHU 330;
BA_ "NmAsrNodeIdentifier" BU_ MHU 4;
BA_ "NmStationAddress" BU_ MHU 4;
BA_ "Address" BU_ XGW_Info 2;
BA_ "ECU" BU_ XGW_Info "XGW_InfoCAN";
BA_ "NmAsrCanMsgCycleOffset" BU_ XGW_Info 10;
BA_ "NmAsrCanMsgReducedTime" BU_ XGW_Info 325;
BA_ "NmAsrNodeIdentifier" BU_ XGW_Info 2;
BA_ "NmStationAddress" BU_ XGW_Info 2;
BA_ "GenMsgCycleTime" BO_ 18 50;
BA_ "GenMsgSendType" BO_ 18 0;
BA_ "GenMsgCycleTime" BO_ 128 50;
BA_ "GenMsgSendType" BO_ 128 0;
BA_ "GenMsgCycleTime" BO_ 130 50;
BA_ "GenMsgSendType" BO_ 130 0;
BA_ "GenMsgCycleTime" BO_ 133 20;
BA_ "GenMsgSendType" BO_ 133 0;
BA_ "GenMsgCycleTime" BO_ 147 100;
BA_ "GenMsgSendType" BO_ 147 0;
BA_ "GenMsgCycleTime" BO_ 149 100;
BA_ "GenMsgSendType" BO_ 149 0;
BA_ "GenMsgCycleTime" BO_ 150 100;
BA_ "GenMsgSendType" BO_ 150 0;
BA_ "GenMsgCycleTime" BO_ 217 40;
BA_ "GenMsgSendType" BO_ 217 0;
BA_ "GenMsgCycleTime" BO_ 241 20;
BA_ "GenMsgSendType" BO_ 241 0;
BA_ "GenMsgCycleTime" BO_ 256 1000;
BA_ "GenMsgSendType" BO_ 256 0;
BA_ "GenMsgCycleTimeFast" BO_ 257 50;
BA_ "GenMsgNrOfRepetition" BO_ 257 2;
BA_ "GenMsgCycleTime" BO_ 258 100;
BA_ "GenMsgSendType" BO_ 258 0;
BA_ "GenMsgCycleTime" BO_ 259 1000;
BA_ "GenMsgSendType" BO_ 259 0;
BA_ "GenMsgCycleTime" BO_ 260 100;
BA_ "GenMsgSendType" BO_ 260 0;
BA_ "GenMsgCycleTime" BO_ 261 100;
BA_ "GenMsgSendType" BO_ 261 0;
BA_ "GenMsgCycleTime" BO_ 262 100;
BA_ "GenMsgSendType" BO_ 262 0;
BA_ "GenMsgCycleTime" BO_ 263 100;
BA_ "GenMsgSendType" BO_ 263 0;
BA_ "GenMsgCycleTime" BO_ 265 100;
BA_ "GenMsgCycleTimeFast" BO_ 265 30;
BA_ "GenMsgNrOfRepetition" BO_ 265 3;
BA_ "GenMsgSendType" BO_ 265 0;
BA_ "GenMsgCycleTime" BO_ 266 500;
BA_ "GenMsgSendType" BO_ 266 0;
BA_ "GenMsgCycleTime" BO_ 267 100;
BA_ "GenMsgSendType" BO_ 267 0;
BA_ "GenMsgCycleTime" BO_ 268 100;
BA_ "GenMsgSendType" BO_ 268 0;
BA_ "GenMsgCycleTimeFast" BO_ 269 30;
BA_ "GenMsgNrOfRepetition" BO_ 269 3;
BA_ "GenMsgCycleTime" BO_ 270 100;
BA_ "GenMsgCycleTimeFast" BO_ 270 30;
BA_ "GenMsgNrOfRepetition" BO_ 270 3;
BA_ "GenMsgSendType" BO_ 270 0;
BA_ "GenMsgCycleTimeFast" BO_ 271 30;
BA_ "GenMsgNrOfRepetition" BO_ 271 3;
BA_ "GenMsgCycleTime" BO_ 274 100;
BA_ "GenMsgCycleTimeFast" BO_ 274 20;
BA_ "GenMsgNrOfRepetition" BO_ 274 3;
BA_ "GenMsgSendType" BO_ 274 0;
BA_ "GenMsgCycleTime" BO_ 276 100;
BA_ "GenMsgSendType" BO_ 276 0;
BA_ "GenMsgCycleTimeFast" BO_ 282 100;
BA_ "GenMsgNrOfRepetition" BO_ 282 2;
BA_ "GenMsgCycleTimeFast" BO_ 283 30;
BA_ "GenMsgNrOfRepetition" BO_ 283 3;
BA_ "GenMsgCycleTimeFast" BO_ 284 30;
BA_ "GenMsgNrOfRepetition" BO_ 284 3;
BA_ "GenMsgCycleTime" BO_ 291 500;
BA_ "GenMsgSendType" BO_ 291 0;
BA_ "GenMsgCycleTime" BO_ 292 500;
BA_ "GenMsgSendType" BO_ 292 0;
BA_ "GenMsgCycleTime" BO_ 294 50;
BA_ "GenMsgSendType" BO_ 294 0;
BA_ "GenMsgCycleTime" BO_ 295 80;
BA_ "GenMsgSendType" BO_ 295 0;
BA_ "GenMsgCycleTime" BO_ 296 100;
BA_ "GenMsgSendType" BO_ 296 0;
BA_ "GenMsgCycleTime" BO_ 297 1000;
BA_ "GenMsgSendType" BO_ 297 0;
BA_ "GenMsgCycleTime" BO_ 303 100;
BA_ "GenMsgSendType" BO_ 303 0;
BA_ "GenMsgCycleTime" BO_ 304 100;
BA_ "GenMsgSendType" BO_ 304 0;
BA_ "GenMsgCycleTime" BO_ 307 100;
BA_ "GenMsgSendType" BO_ 307 0;
BA_ "GenMsgCycleTime" BO_ 308 50;
BA_ "GenMsgNrOfRepetition" BO_ 308 3;
BA_ "GenMsgSendType" BO_ 308 0;
BA_ "GenMsgCycleTime" BO_ 312 50;
BA_ "GenMsgSendType" BO_ 312 0;
BA_ "GenMsgCycleTime" BO_ 313 50;
BA_ "GenMsgSendType" BO_ 313 0;
BA_ "GenMsgCycleTime" BO_ 318 50;
BA_ "GenMsgSendType" BO_ 318 0;
BA_ "GenMsgCycleTime" BO_ 319 50;
BA_ "GenMsgSendType" BO_ 319 0;
BA_ "GenMsgCycleTime" BO_ 320 50;
BA_ "GenMsgSendType" BO_ 320 0;
BA_ "GenMsgCycleTime" BO_ 321 50;
BA_ "GenMsgSendType" BO_ 321 0;
BA_ "GenMsgCycleTime" BO_ 322 50;
BA_ "GenMsgSendType" BO_ 322 0;
BA_ "GenMsgCycleTime" BO_ 323 50;
BA_ "GenMsgSendType" BO_ 323 0;
BA_ "GenMsgCycleTime" BO_ 324 50;
BA_ "GenMsgSendType" BO_ 324 0;
BA_ "GenMsgCycleTime" BO_ 325 50;
BA_ "GenMsgSendType" BO_ 325 0;
BA_ "GenMsgCycleTime" BO_ 326 50;
BA_ "GenMsgSendType" BO_ 326 0;
BA_ "GenMsgCycleTime" BO_ 327 50;
BA_ "GenMsgSendType" BO_ 327 0;
BA_ "GenMsgCycleTime" BO_ 328 50;
BA_ "GenMsgSendType" BO_ 328 0;
BA_ "GenMsgCycleTime" BO_ 329 50;
BA_ "GenMsgSendType" BO_ 329 0;
BA_ "GenMsgCycleTime" BO_ 330 50;
BA_ "GenMsgSendType" BO_ 330 0;
BA_ "GenMsgCycleTime" BO_ 331 50;
BA_ "GenMsgSendType" BO_ 331 0;
BA_ "GenMsgCycleTime" BO_ 332 50;
BA_ "GenMsgSendType" BO_ 332 0;
BA_ "GenMsgCycleTime" BO_ 333 50;
BA_ "GenMsgSendType" BO_ 333 0;
BA_ "GenMsgCycleTime" BO_ 334 50;
BA_ "GenMsgSendType" BO_ 334 0;
BA_ "GenMsgCycleTime" BO_ 335 50;
BA_ "GenMsgSendType" BO_ 335 0;
BA_ "GenMsgCycleTime" BO_ 357 50;
BA_ "GenMsgSendType" BO_ 357 0;
BA_ "GenMsgCycleTime" BO_ 360 100;
BA_ "GenMsgCycleTimeFast" BO_ 360 50;
BA_ "GenMsgNrOfRepetition" BO_ 360 2;
BA_ "GenMsgSendType" BO_ 360 0;
BA_ "GenMsgCycleTime" BO_ 372 150;
BA_ "GenMsgSendType" BO_ 372 0;
BA_ "GenMsgCycleTime" BO_ 374 150;
BA_ "GenMsgSendType" BO_ 374 0;
BA_ "GenMsgCycleTime" BO_ 376 10;
BA_ "GenMsgSendType" BO_ 376 0;
BA_ "GenMsgCycleTime" BO_ 377 10;
BA_ "GenMsgSendType" BO_ 377 0;
BA_ "GenMsgCycleTime" BO_ 382 20;
BA_ "GenMsgSendType" BO_ 382 0;
BA_ "GenMsgSendType" BO_ 385 0;
BA_ "GenMsgCycleTime" BO_ 385 100;
BA_ "GenSigTimeoutTime_ALL" SG_ 18 CPD_MHU_Climate_control 500;
BA_ "InvalidValue" SG_ 18 CPD_MHU_Climate_control "null";
BA_ "GenSigTimeoutTime_ALL" SG_ 128 CHKSM_ADAS_TSR_STATUS 500;
BA_ "GenSigTimeoutTime_ALL" SG_ 128 ALV_ADAS_TSR_Status 500;
BA_ "InvalidValue" SG_ 128 ALV_ADAS_TSR_Status "Fh";
BA_ "GenSigTimeoutTime_ALL" SG_ 128 ADAS_TSR_PopUp_Feed 500;
BA_ "InvalidValue" SG_ 128 ADAS_TSR_PopUp_Feed "Fh";
BA_ "GenSigStartValue" SG_ 128 ADAS_TSR_SLAert_Feed 1;
BA_ "GenSigTimeoutTime_ALL" SG_ 128 ADAS_TSR_SLAert_Feed 500;
BA_ "InvalidValue" SG_ 128 ADAS_TSR_SLAert_Feed "3h";
BA_ "GenSigTimeoutTime_ALL" SG_ 128 ADAS_TSR_Typ2_value 500;
BA_ "InvalidValue" SG_ 128 ADAS_TSR_Typ2_value "null";
BA_ "GenSigTimeoutTime_ALL" SG_ 128 ADAS_TSR_Typ1 500;
BA_ "InvalidValue" SG_ 128 ADAS_TSR_Typ1 "7h";
BA_ "GenSigTimeoutTime_ALL" SG_ 128 ADAS_TSR_Typ1_value 500;
BA_ "InvalidValue" SG_ 128 ADAS_TSR_Typ1_value "null";
BA_ "GenSigTimeoutTime_ALL" SG_ 128 ADAS_TSR_Warning_audible 500;
BA_ "InvalidValue" SG_ 128 ADAS_TSR_Warning_audible "3h";
BA_ "GenSigTimeoutTime_ALL" SG_ 128 ADAS_TSR_Typ2_Flashing_Warning 500;
BA_ "InvalidValue" SG_ 128 ADAS_TSR_Typ2_Flashing_Warning "1";
BA_ "GenSigTimeoutTime_ALL" SG_ 128 ADAS_TSR_Mode_Feed 500;
BA_ "InvalidValue" SG_ 128 ADAS_TSR_Mode_Feed "3h";
BA_ "GenSigTimeoutTime_ALL" SG_ 128 ADAS_TSR_AudWarning_Feed 500;
BA_ "InvalidValue" SG_ 128 ADAS_TSR_AudWarning_Feed "7h";
BA_ "GenSigTimeoutTime_ALL" SG_ 128 ADAS_TSR_Typ1_Flashing_Warning 500;
BA_ "InvalidValue" SG_ 128 ADAS_TSR_Typ1_Flashing_Warning "1";
BA_ "GenSigTimeoutTime_ALL" SG_ 128 ADAS_TSR_Typ3 500;
BA_ "InvalidValue" SG_ 128 ADAS_TSR_Typ3 "7h";
BA_ "GenSigTimeoutTime_ALL" SG_ 128 ADAS_TSR_Typ2 500;
BA_ "InvalidValue" SG_ 128 ADAS_TSR_Typ2 "Fh";
BA_ "GenSigTimeoutTime_ALL" SG_ 128 ADAS_TSR_State 500;
BA_ "InvalidValue" SG_ 128 ADAS_TSR_State "3h";
BA_ "GenSigTimeoutTime_ALL" SG_ 130 CHKSM_ADAS_CMP_MHU 500;
BA_ "GenSigTimeoutTime_ALL" SG_ 130 ALV_ADAS_CMP_MHU 500;
BA_ "InvalidValue" SG_ 130 ALV_ADAS_CMP_MHU "Fh";
BA_ "GenSigTimeoutTime_ALL" SG_ 130 ADAS_TakeOver_Request 500;
BA_ "InvalidValue" SG_ 130 ADAS_TakeOver_Request "1Fh";
BA_ "GenSigTimeoutTime_ALL" SG_ 130 ADAS_Sounds_Feed 500;
BA_ "InvalidValue" SG_ 130 ADAS_Sounds_Feed "1Fh";
BA_ "GenSigTimeoutTime_ALL" SG_ 130 SECCAN_ADAS_CMP_MHU 500;
BA_ "GenSigTimeoutTime_ALL" SG_ 133 CHKSM_CRASH_Sts 200;
BA_ "InvalidValue" SG_ 133 CHKSM_CRASH_Sts "null";
BA_ "GenSigTimeoutTime_ALL" SG_ 133 ALV_CRASH_Sts 200;
BA_ "InvalidValue" SG_ 133 ALV_CRASH_Sts "Fh";
BA_ "GenSigTimeoutTime_ALL" SG_ 133 ACM_Crash_Sts 200;
BA_ "InvalidValue" SG_ 133 ACM_Crash_Sts "3h";
BA_ "GenSigTimeoutTime_ALL" SG_ 133 ACM_Airbag_Deployment_Status 200;
BA_ "InvalidValue" SG_ 133 ACM_Airbag_Deployment_Status "3h";
BA_ "GenSigTimeoutTime_ALL" SG_ 133 ACM_Crash_Intensity 200;
BA_ "InvalidValue" SG_ 133 ACM_Crash_Intensity "7h";
BA_ "GenSigTimeoutTime_ALL" SG_ 133 ACM_Front_Crash 200;
BA_ "InvalidValue" SG_ 133 ACM_Front_Crash "3h";
BA_ "GenSigTimeoutTime_ALL" SG_ 133 ACM_DriverSide_Crash 200;
BA_ "InvalidValue" SG_ 133 ACM_DriverSide_Crash "3h";
BA_ "GenSigTimeoutTime_ALL" SG_ 133 ACM_PassSide_Crash 200;
BA_ "InvalidValue" SG_ 133 ACM_PassSide_Crash "3h";
BA_ "GenSigTimeoutTime_ALL" SG_ 133 ACM_Rear_Crash 200;
BA_ "InvalidValue" SG_ 133 ACM_Rear_Crash "3h";
BA_ "GenSigTimeoutTime_ALL" SG_ 133 ACM_Rollover_Crash 200;
BA_ "InvalidValue" SG_ 133 ACM_Rollover_Crash "3h";
BA_ "GenSigTimeoutTime_ALL" SG_ 147 CHKSM_MILEAGE 500;
BA_ "InvalidValue" SG_ 147 CHKSM_MILEAGE "null";
BA_ "GenSigTimeoutTime_ALL" SG_ 147 ALIVE_MILEAGE 500;
BA_ "InvalidValue" SG_ 147 ALIVE_MILEAGE "Fh";
BA_ "GenSigTimeoutTime_ALL" SG_ 147 Mileage 500;
BA_ "InvalidValue" SG_ 147 Mileage "FFFFh";
BA_ "GenSigTimeoutTime_ALL" SG_ 149 CHKSM_IDB_FUNCTION 500;
BA_ "InvalidValue" SG_ 149 CHKSM_IDB_FUNCTION "null";
BA_ "GenSigTimeoutTime_ALL" SG_ 149 ALV_IDB_FUNCTION 500;
BA_ "InvalidValue" SG_ 149 ALV_IDB_FUNCTION "Fh";
BA_ "GenSigTimeoutTime_ALL" SG_ 149 STAT_ABS 500;
BA_ "InvalidValue" SG_ 149 STAT_ABS "3h";
BA_ "GenSigTimeoutTime_ALL" SG_ 149 AYC_Active 500;
BA_ "InvalidValue" SG_ 149 AYC_Active "3h";
BA_ "GenSigTimeoutTime_ALL" SG_ 149 ASR_Active 500;
BA_ "InvalidValue" SG_ 149 ASR_Active "3h";
BA_ "GenSigTimeoutTime_ALL" SG_ 149 STAT_DSC 500;
BA_ "InvalidValue" SG_ 149 STAT_DSC "3h";
BA_ "GenSigTimeoutTime_ALL" SG_ 149 DSC_Active 500;
BA_ "InvalidValue" SG_ 149 DSC_Active "3h";
BA_ "GenSigTimeoutTime_ALL" SG_ 149 HBA_ActiveSignal 500;
BA_ "InvalidValue" SG_ 149 HBA_ActiveSignal "3h";
BA_ "GenSigTimeoutTime_ALL" SG_ 149 ARM_ActiveSignal 500;
BA_ "InvalidValue" SG_ 149 ARM_ActiveSignal "3h";
BA_ "GenSigTimeoutTime_ALL" SG_ 149 STAT_AutoHazardBlinking 500;
BA_ "InvalidValue" SG_ 149 STAT_AutoHazardBlinking "3h";
BA_ "GenSigTimeoutTime_ALL" SG_ 149 MSR_Active 500;
BA_ "InvalidValue" SG_ 149 MSR_Active "3h";
BA_ "GenSigTimeoutTime_ALL" SG_ 149 HSA_ActiveSignal 500;
BA_ "InvalidValue" SG_ 149 HSA_ActiveSignal "3h";
BA_ "GenSigTimeoutTime_ALL" SG_ 149 EPBi_ECD_ActiveSignal 500;
BA_ "InvalidValue" SG_ 149 EPBi_ECD_ActiveSignal "3h";
BA_ "GenSigTimeoutTime_ALL" SG_ 149 TSM_Active 500;
BA_ "InvalidValue" SG_ 149 TSM_Active "3h";
BA_ "GenSigTimeoutTime_ALL" SG_ 149 HAS_Available 500;
BA_ "InvalidValue" SG_ 149 HAS_Available "3h";
BA_ "GenSigTimeoutTime_ALL" SG_ 149 STAT_EBD 500;
BA_ "InvalidValue" SG_ 149 STAT_EBD "3h";
BA_ "GenSigTimeoutTime_ALL" SG_ 149 EBD_Active 500;
BA_ "InvalidValue" SG_ 149 EBD_Active "3h";
BA_ "GenSigTimeoutTime_ALL" SG_ 149 ST_BRG_MSA 500;
BA_ "InvalidValue" SG_ 149 ST_BRG_MSA "Fh";
BA_ "GenSigTimeoutTime_ALL" SG_ 150 CHKSM_MHU_IDB_Mode_Select 500;
BA_ "InvalidValue" SG_ 150 CHKSM_MHU_IDB_Mode_Select "null";
BA_ "GenSigTimeoutTime_ALL" SG_ 150 ALV_MHU_IDB_Mode_Select 500;
BA_ "InvalidValue" SG_ 150 ALV_MHU_IDB_Mode_Select "Fh";
BA_ "GenSigTimeoutTime_ALL" SG_ 150 MHU_IDB_Mode_Select_Signal 500;
BA_ "InvalidValue" SG_ 150 MHU_IDB_Mode_Select_Signal "null";
BA_ "GenSigTimeoutTime_ALL" SG_ 217 CRC_VCU_HV_DrvSys_status 400;
BA_ "GenSigTimeoutTime_ALL" SG_ 217 CRC_VCU_HV_DrvSys_status 200;
BA_ "InvalidValue" SG_ 217 CRC_VCU_HV_DrvSys_status "Fh";
BA_ "InvalidValue" SG_ 217 CRC_VCU_HV_DrvSys_status "null";
BA_ "GenSigTimeoutTime_ALL" SG_ 217 ALIV_VCU_HV_DrvSys_status 200;
BA_ "GenSigTimeoutTime_ALL" SG_ 217 ALIV_VCU_HV_DrvSys_status 400;
BA_ "InvalidValue" SG_ 217 ALIV_VCU_HV_DrvSys_status "Fh";
BA_ "GenSigTimeoutTime_ALL" SG_ 217 VCU_HVsystem_status 200;
BA_ "GenSigTimeoutTime_ALL" SG_ 217 VCU_HVsystem_status 400;
BA_ "InvalidValue" SG_ 217 VCU_HVsystem_status "null";
BA_ "GenSigTimeoutTime_ALL" SG_ 217 VCU_ACPD_Percent 200;
BA_ "GenSigTimeoutTime_ALL" SG_ 217 VCU_ACPD_Percent 400;
BA_ "InvalidValue" SG_ 217 VCU_ACPD_Percent "FFFh";
BA_ "GenSigTimeoutTime_ALL" SG_ 217 VCU_ACPD_Percent_Valid 400;
BA_ "GenSigTimeoutTime_ALL" SG_ 217 VCU_ACPD_Percent_Valid 200;
BA_ "InvalidValue" SG_ 217 VCU_ACPD_Percent_Valid "null";
BA_ "GenSigTimeoutTime_ALL" SG_ 217 VCU_ACTGear 200;
BA_ "GenSigTimeoutTime_ALL" SG_ 217 VCU_ACTGear 400;
BA_ "InvalidValue" SG_ 217 VCU_ACTGear "null";
BA_ "GenSigTimeoutTime_ALL" SG_ 217 VCU_ACTGearValid 200;
BA_ "GenSigTimeoutTime_ALL" SG_ 217 VCU_ACTGearValid 400;
BA_ "InvalidValue" SG_ 217 VCU_ACTGearValid "null";
BA_ "GenSigTimeoutTime_ALL" SG_ 217 VCU_ACT_DriveMode 200;
BA_ "GenSigTimeoutTime_ALL" SG_ 217 VCU_ACT_DriveMode 400;
BA_ "InvalidValue" SG_ 217 VCU_ACT_DriveMode "null";
BA_ "GenSigStartValue" SG_ 217 VCU_ACT_DriveMode_Valid 1;
BA_ "GenSigTimeoutTime_ALL" SG_ 217 VCU_ACT_DriveMode_Valid 200;
BA_ "GenSigTimeoutTime_ALL" SG_ 217 VCU_ACT_DriveMode_Valid 400;
BA_ "InvalidValue" SG_ 217 VCU_ACT_DriveMode_Valid "null";
BA_ "GenSigTimeoutTime_ALL" SG_ 217 VCU_HV_DRVsystem_status 200;
BA_ "GenSigTimeoutTime_ALL" SG_ 217 VCU_HV_DRVsystem_status 400;
BA_ "InvalidValue" SG_ 217 VCU_HV_DRVsystem_status "null";
BA_ "GenSigTimeoutTime_ALL" SG_ 217 VCU_Recu_BrakeLight_ON_Req 200;
BA_ "GenSigTimeoutTime_ALL" SG_ 217 VCU_Recu_BrakeLight_ON_Req 400;
BA_ "InvalidValue" SG_ 217 VCU_Recu_BrakeLight_ON_Req "3h";
BA_ "GenSigTimeoutTime_ALL" SG_ 241 CRC_RecuBrakeTorqueRequest 200;
BA_ "InvalidValue" SG_ 241 CRC_RecuBrakeTorqueRequest "null";
BA_ "GenSigTimeoutTime_ALL" SG_ 241 ALIV_RecuBrakeTorqueRequest 200;
BA_ "InvalidValue" SG_ 241 ALIV_RecuBrakeTorqueRequest "Fh";
BA_ "GenSigTimeoutTime_ALL" SG_ 241 IDB_RecuBrakeTorqueRequest_FR 200;
BA_ "InvalidValue" SG_ 241 IDB_RecuBrakeTorqueRequest_FR "null";
BA_ "GenSigTimeoutTime_ALL" SG_ 241 IDB_RecuBrakeTorqueRequest_RR 200;
BA_ "InvalidValue" SG_ 241 IDB_RecuBrakeTorqueRequest_RR "null";
BA_ "GenSigTimeoutTime_ALL" SG_ 241 IDB_RecuBrakeControl_Sts 200;
BA_ "InvalidValue" SG_ 241 IDB_RecuBrakeControl_Sts "null";
BA_ "GenSigTimeoutTime_ALL" SG_ 241 IDB_RecuBrkTorqueReq_Sts 200;
BA_ "InvalidValue" SG_ 241 IDB_RecuBrkTorqueReq_Sts "null";
BA_ "GenSigTimeoutTime_ALL" SG_ 241 IDB_Brake_Pedal_position 200;
BA_ "InvalidValue" SG_ 241 IDB_Brake_Pedal_position "null";
BA_ "GenSigTimeoutTime_ALL" SG_ 241 IDB_Brake_Pedal_position_sts 200;
BA_ "InvalidValue" SG_ 241 IDB_Brake_Pedal_position_sts "null";
BA_ "GenSigTimeoutTime_ALL" SG_ 256 CHKSM_MHU_VEH_INFO 5000;
BA_ "InvalidValue" SG_ 256 CHKSM_MHU_VEH_INFO "null";
BA_ "GenSigTimeoutTime_ALL" SG_ 256 ALV_MHU_VEH_INFO 5000;
BA_ "InvalidValue" SG_ 256 ALV_MHU_VEH_INFO "Fh";
BA_ "GenSigTimeoutTime_ALL" SG_ 256 MHU_UserProfileId 5000;
BA_ "InvalidValue" SG_ 256 MHU_UserProfileId "Fh";
BA_ "GenSigTimeoutTime_ALL" SG_ 256 MHU_Connectivity_Status 5000;
BA_ "InvalidValue" SG_ 256 MHU_Connectivity_Status "0";
BA_ "GenSigSendType" SG_ 257 DMS_Setting 2;
BA_ "InvalidValue" SG_ 257 DMS_Setting "7h";
BA_ "GenSigSendType" SG_ 257 DMS_Driver_registration_request 2;
BA_ "InvalidValue" SG_ 257 DMS_Driver_registration_request "7h";
BA_ "GenSigSendType" SG_ 257 DMS_Driver_ID_request 2;
BA_ "InvalidValue" SG_ 257 DMS_Driver_ID_request "7h";
BA_ "GenSigSendType" SG_ 257 DMS_Status 2;
BA_ "GenSigStartValue" SG_ 257 DMS_Status 1;
BA_ "InvalidValue" SG_ 257 DMS_Status "7h";
BA_ "GenSigSendType" SG_ 257 DMS_Image_processing 2;
BA_ "InvalidValue" SG_ 257 DMS_Image_processing "7h";
BA_ "GenSigSendType" SG_ 257 DMS_DriverConfirmDMSWarning 2;
BA_ "InvalidValue" SG_ 257 DMS_DriverConfirmDMSWarning "0h";
BA_ "GenSigTimeoutTime_ALL" SG_ 258 CHKSM_BCM_LOGICAL_CLAMP 500;
BA_ "InvalidValue" SG_ 258 CHKSM_BCM_LOGICAL_CLAMP "null";
BA_ "GenSigTimeoutTime_ALL" SG_ 258 ALIVE_BCM_LOGICAL_CLAMP 500;
BA_ "InvalidValue" SG_ 258 ALIVE_BCM_LOGICAL_CLAMP "Fh";
BA_ "GenSigTimeoutTime_ALL" SG_ 258 STAT_CL30s_Light_L 500;
BA_ "InvalidValue" SG_ 258 STAT_CL30s_Light_L "3h";
BA_ "GenSigStartValue" SG_ 258 STAT_CL30s_L 3;
BA_ "GenSigTimeoutTime_ALL" SG_ 258 STAT_CL30s_L 500;
BA_ "InvalidValue" SG_ 258 STAT_CL30s_L "3h";
BA_ "GenSigStartValue" SG_ 258 STAT_CL15Wup_L 3;
BA_ "GenSigTimeoutTime_ALL" SG_ 258 STAT_CL15Wup_L 500;
BA_ "InvalidValue" SG_ 258 STAT_CL15Wup_L "3h";
BA_ "GenSigTimeoutTime_ALL" SG_ 258 STAT_CrankRelayHW_BCM 500;
BA_ "InvalidValue" SG_ 258 STAT_CrankRelayHW_BCM "3h";
BA_ "GenSigSendType" SG_ 259 REQ_ConsumerControlWirelessCharg 3;
BA_ "GenSigTimeoutTime_ALL" SG_ 259 REQ_ConsumerControlWirelessCharg 5000;
BA_ "InvalidValue" SG_ 259 REQ_ConsumerControlWirelessCharg "3h";
BA_ "GenSigSendType" SG_ 259 REQ_ConsumerControlAudioVolumeCo 3;
BA_ "GenSigTimeoutTime_ALL" SG_ 259 REQ_ConsumerControlAudioVolumeCo 5000;
BA_ "InvalidValue" SG_ 259 REQ_ConsumerControlAudioVolumeCo "7h";
BA_ "GenSigSendType" SG_ 259 REQ_ConsumerControlRearDefrost 3;
BA_ "GenSigTimeoutTime_ALL" SG_ 259 REQ_ConsumerControlRearDefrost 5000;
BA_ "InvalidValue" SG_ 259 REQ_ConsumerControlRearDefrost "3h";
BA_ "GenSigSendType" SG_ 259 REQ_ConsumerControlSeatHeatingRe 3;
BA_ "GenSigTimeoutTime_ALL" SG_ 259 REQ_ConsumerControlSeatHeatingRe 5000;
BA_ "InvalidValue" SG_ 259 REQ_ConsumerControlSeatHeatingRe "FFh";
BA_ "GenSigSendType" SG_ 259 REQ_ConsumerControlSeatVentilati 3;
BA_ "GenSigTimeoutTime_ALL" SG_ 259 REQ_ConsumerControlSeatVentilati 5000;
BA_ "InvalidValue" SG_ 259 REQ_ConsumerControlSeatVentilati "FFh";
BA_ "GenSigSendType" SG_ 259 REQ_ConsumerControlSeatHeatingFr 3;
BA_ "GenSigTimeoutTime_ALL" SG_ 259 REQ_ConsumerControlSeatHeatingFr 5000;
BA_ "InvalidValue" SG_ 259 REQ_ConsumerControlSeatHeatingFr "FFh";
BA_ "GenSigSendType" SG_ 259 DriverIdealTimerCount 3;
BA_ "GenSigTimeoutTime_ALL" SG_ 259 DriverIdealTimerCount 5000;
BA_ "InvalidValue" SG_ 259 DriverIdealTimerCount "FFh";
BA_ "GenSigSendType" SG_ 259 REQ_ConsumerControlVentilationCl 3;
BA_ "GenSigStartValue" SG_ 259 REQ_ConsumerControlVentilationCl 100;
BA_ "GenSigTimeoutTime_ALL" SG_ 259 REQ_ConsumerControlVentilationCl 5000;
BA_ "InvalidValue" SG_ 259 REQ_ConsumerControlVentilationCl "FFh";
BA_ "GenSigTimeoutTime_ALL" SG_ 260 CHKSM_LV_BATT_CHARG 500;
BA_ "InvalidValue" SG_ 260 CHKSM_LV_BATT_CHARG "null";
BA_ "GenSigTimeoutTime_ALL" SG_ 260 ALIV_LV_BATT_CHARG 500;
BA_ "InvalidValue" SG_ 260 ALIV_LV_BATT_CHARG "Fh";
BA_ "GenSigStartValue" SG_ 260 SOH_SUL 255;
BA_ "GenSigTimeoutTime_ALL" SG_ 260 SOH_SUL 500;
BA_ "InvalidValue" SG_ 260 SOH_SUL "FFh";
BA_ "GenSigStartValue" SG_ 260 SOH_SUL_STATE 3;
BA_ "GenSigTimeoutTime_ALL" SG_ 260 SOH_SUL_STATE 500;
BA_ "InvalidValue" SG_ 260 SOH_SUL_STATE "3h";
BA_ "GenSigStartValue" SG_ 260 SOC_STATE 3;
BA_ "GenSigTimeoutTime_ALL" SG_ 260 SOC_STATE 500;
BA_ "InvalidValue" SG_ 260 SOC_STATE "3h";
BA_ "GenSigTimeoutTime_ALL" SG_ 260 Resp_Error 500;
BA_ "InvalidValue" SG_ 260 Resp_Error "null";
BA_ "GenSigTimeoutTime_ALL" SG_ 260 FLAG_INCONSTENCY 500;
BA_ "InvalidValue" SG_ 260 FLAG_INCONSTENCY "null";
BA_ "GenSigTimeoutTime_ALL" SG_ 260 EBS_error 500;
BA_ "InvalidValue" SG_ 260 EBS_error "null";
BA_ "GenSigTimeoutTime_ALL" SG_ 260 FLAG_DISCONNECT 500;
BA_ "InvalidValue" SG_ 260 FLAG_DISCONNECT "null";
BA_ "GenSigTimeoutTime_ALL" SG_ 260 BCM_LV_Batt_Charging_Req 500;
BA_ "InvalidValue" SG_ 260 BCM_LV_Batt_Charging_Req "null";
BA_ "GenSigTimeoutTime_ALL" SG_ 260 IBATT_QUIESCENT 500;
BA_ "GenSigTimeoutTime_ALL" SG_ 261 CHKSM_BCM_STAT_DOOR_FLAP 500;
BA_ "InvalidValue" SG_ 261 CHKSM_BCM_STAT_DOOR_FLAP "null";
BA_ "GenSigTimeoutTime_ALL" SG_ 261 ALIVE_BCM_STAT_DOOR_FLAP 500;
BA_ "InvalidValue" SG_ 261 ALIVE_BCM_STAT_DOOR_FLAP "Fh";
BA_ "GenSigTimeoutTime_ALL" SG_ 261 BCM_STAT_TrunkAjar 500;
BA_ "InvalidValue" SG_ 261 BCM_STAT_TrunkAjar "3h";
BA_ "GenSigTimeoutTime_ALL" SG_ 261 BCM_STAT_DoorAjarFL 500;
BA_ "InvalidValue" SG_ 261 BCM_STAT_DoorAjarFL "3h";
BA_ "GenSigTimeoutTime_ALL" SG_ 261 BCM_STAT_DoorAjarFR 500;
BA_ "InvalidValue" SG_ 261 BCM_STAT_DoorAjarFR "3h";
BA_ "GenSigTimeoutTime_ALL" SG_ 261 BCM_STAT_DoorAjarRL 500;
BA_ "InvalidValue" SG_ 261 BCM_STAT_DoorAjarRL "3h";
BA_ "GenSigTimeoutTime_ALL" SG_ 261 BCM_STAT_DoorAjarRR 500;
BA_ "InvalidValue" SG_ 261 BCM_STAT_DoorAjarRR "3h";
BA_ "GenSigTimeoutTime_ALL" SG_ 261 BCM_STAT_BonnetAjar 500;
BA_ "InvalidValue" SG_ 261 BCM_STAT_BonnetAjar "3h";
BA_ "GenSigTimeoutTime_ALL" SG_ 262 CHKSM_BCM_LIGHT 500;
BA_ "InvalidValue" SG_ 262 CHKSM_BCM_LIGHT "null";
BA_ "GenSigTimeoutTime_ALL" SG_ 262 ALIVE_BCM_LIGHT 500;
BA_ "InvalidValue" SG_ 262 ALIVE_BCM_LIGHT "Fh";
BA_ "GenSigTimeoutTime_ALL" SG_ 262 BCM_DayRunningLampSts 500;
BA_ "InvalidValue" SG_ 262 BCM_DayRunningLampSts "3h";
BA_ "GenSigTimeoutTime_ALL" SG_ 262 BCM_ReverseLightSts 500;
BA_ "InvalidValue" SG_ 262 BCM_ReverseLightSts "3h";
BA_ "GenSigTimeoutTime_ALL" SG_ 262 BCM_StopLightSts 500;
BA_ "InvalidValue" SG_ 262 BCM_StopLightSts "3h";
BA_ "GenSigTimeoutTime_ALL" SG_ 262 BCM_LicensePlateLightSts 500;
BA_ "InvalidValue" SG_ 262 BCM_LicensePlateLightSts "3h";
BA_ "GenSigTimeoutTime_ALL" SG_ 262 BCM_Fr_Dimming_dome_lampSts 500;
BA_ "InvalidValue" SG_ 262 BCM_Fr_Dimming_dome_lampSts "3h";
BA_ "GenSigTimeoutTime_ALL" SG_ 262 BCM_Rr_Dimming_dome_lampSts 500;
BA_ "InvalidValue" SG_ 262 BCM_Rr_Dimming_dome_lampSts "3h";
BA_ "GenSigStartValue" SG_ 262 BCM_STAT_InteriorLight 3;
BA_ "GenSigTimeoutTime_ALL" SG_ 262 BCM_STAT_InteriorLight 500;
BA_ "InvalidValue" SG_ 262 BCM_STAT_InteriorLight "3h";
BA_ "GenSigStartValue" SG_ 262 BCM_STAT_LightActivation 7;
BA_ "GenSigTimeoutTime_ALL" SG_ 262 BCM_STAT_LightActivation 500;
BA_ "InvalidValue" SG_ 262 BCM_STAT_LightActivation "7h";
BA_ "GenSigTimeoutTime_ALL" SG_ 262 BCM_HighBeamSts 500;
BA_ "InvalidValue" SG_ 262 BCM_HighBeamSts "3h";
BA_ "GenSigStartValue" SG_ 262 BCM_STAT_SwitchLightBrightness 80;
BA_ "GenSigTimeoutTime_ALL" SG_ 262 BCM_STAT_SwitchLightBrightness 500;
BA_ "InvalidValue" SG_ 262 BCM_STAT_SwitchLightBrightness "7Fh";
BA_ "GenSigTimeoutTime_ALL" SG_ 262 BCM_LowBeamSts 500;
BA_ "InvalidValue" SG_ 262 BCM_LowBeamSts "3h";
BA_ "GenSigTimeoutTime_ALL" SG_ 262 BCM_RearFogLmpSts 500;
BA_ "InvalidValue" SG_ 262 BCM_RearFogLmpSts "3h";
BA_ "GenSigTimeoutTime_ALL" SG_ 262 BCM_FrntFogLmpSts 500;
BA_ "InvalidValue" SG_ 262 BCM_FrntFogLmpSts "3h";
BA_ "GenSigTimeoutTime_ALL" SG_ 262 BCM_PosLmpSts 500;
BA_ "InvalidValue" SG_ 262 BCM_PosLmpSts "3h";
BA_ "GenSigTimeoutTime_ALL" SG_ 262 BCM_HornSts 500;
BA_ "InvalidValue" SG_ 262 BCM_HornSts "3h";
BA_ "GenSigSendType" SG_ 262 BCM_TurnIndicatorSts 3;
BA_ "GenSigTimeoutTime_ALL" SG_ 262 BCM_TurnIndicatorSts 500;
BA_ "InvalidValue" SG_ 262 BCM_TurnIndicatorSts "3h";
BA_ "GenSigTimeoutTime_ALL" SG_ 263 CHKSM_BCM_CENTRAL_LOCK 500;
BA_ "InvalidValue" SG_ 263 CHKSM_BCM_CENTRAL_LOCK "null";
BA_ "GenSigTimeoutTime_ALL" SG_ 263 ALV_BCM_CENTRAL_LOCK 500;
BA_ "InvalidValue" SG_ 263 ALV_BCM_CENTRAL_LOCK "Fh";
BA_ "GenSigTimeoutTime_ALL" SG_ 263 STAT_CDL_LED 500;
BA_ "InvalidValue" SG_ 263 STAT_CDL_LED "3h";
BA_ "GenSigTimeoutTime_ALL" SG_ 263 STAT_DoorUnlockFL 500;
BA_ "InvalidValue" SG_ 263 STAT_DoorUnlockFL "3h";
BA_ "GenSigTimeoutTime_ALL" SG_ 263 STAT_ATWS 500;
BA_ "InvalidValue" SG_ 263 STAT_ATWS "7h";
BA_ "GenSigTimeoutTime_ALL" SG_ 263 STAT_DoorLockFL 500;
BA_ "InvalidValue" SG_ 263 STAT_DoorLockFL "3h";
BA_ "GenSigTimeoutTime_ALL" SG_ 265 CHKSM_BCM_SWITCH_Sts 500;
BA_ "InvalidValue" SG_ 265 CHKSM_BCM_SWITCH_Sts "null";
BA_ "GenSigTimeoutTime_ALL" SG_ 265 ALV_BCM_SWITCH_Sts 500;
BA_ "InvalidValue" SG_ 265 ALV_BCM_SWITCH_Sts "Fh";
BA_ "GenSigSendType" SG_ 265 BCM_STAT_BrakeSwitch 4;
BA_ "GenSigTimeoutTime_ALL" SG_ 265 BCM_STAT_BrakeSwitch 500;
BA_ "InvalidValue" SG_ 265 BCM_STAT_BrakeSwitch "3h";
BA_ "GenSigSendType" SG_ 265 BCM_STAT_HazardWarn 4;
BA_ "GenSigTimeoutTime_ALL" SG_ 265 BCM_STAT_HazardWarn 500;
BA_ "InvalidValue" SG_ 265 BCM_STAT_HazardWarn "3h";
BA_ "GenSigSendType" SG_ 265 BCM_STAT_FuelPumpCutOFF 4;
BA_ "GenSigTimeoutTime_ALL" SG_ 265 BCM_STAT_FuelPumpCutOFF 500;
BA_ "InvalidValue" SG_ 265 BCM_STAT_FuelPumpCutOFF "3h";
BA_ "GenSigTimeoutTime_ALL" SG_ 265 BCM_FollowMeHomeActive 500;
BA_ "InvalidValue" SG_ 265 BCM_FollowMeHomeActive "3h";
BA_ "GenSigSendType" SG_ 265 BCM_STAT_Horn 4;
BA_ "GenSigTimeoutTime_ALL" SG_ 265 BCM_STAT_Horn 500;
BA_ "InvalidValue" SG_ 265 BCM_STAT_Horn "3h";
BA_ "GenSigSendType" SG_ 265 BCM_STAT_Autowiping 4;
BA_ "GenSigTimeoutTime_ALL" SG_ 265 BCM_STAT_Autowiping 500;
BA_ "InvalidValue" SG_ 265 BCM_STAT_Autowiping "3h";
BA_ "GenSigTimeoutTime_ALL" SG_ 265 BCM_TurnIndicator 500;
BA_ "InvalidValue" SG_ 265 BCM_TurnIndicator "3h";
BA_ "GenSigTimeoutTime_ALL" SG_ 265 BCM_WelcomeActive 500;
BA_ "InvalidValue" SG_ 265 BCM_WelcomeActive "3h";
BA_ "GenSigTimeoutTime_ALL" SG_ 265 BCM_HighBeam 500;
BA_ "InvalidValue" SG_ 265 BCM_HighBeam "3h";
BA_ "GenSigTimeoutTime_ALL" SG_ 265 ACM_Seat_Belt_Status_3rd_Row_Pas 500;
BA_ "InvalidValue" SG_ 265 ACM_Seat_Belt_Status_3rd_Row_Pas "null";
BA_ "GenSigTimeoutTime_ALL" SG_ 265 ACM_Seat_Belt_Status_3rd_Row_Dri 500;
BA_ "InvalidValue" SG_ 265 ACM_Seat_Belt_Status_3rd_Row_Dri "null";
BA_ "GenSigTimeoutTime_ALL" SG_ 266 CHKSM_BCM_VOLTAGE 2500;
BA_ "InvalidValue" SG_ 266 CHKSM_BCM_VOLTAGE "null";
BA_ "GenSigTimeoutTime_ALL" SG_ 266 ALIVE_BCM_VOLTAGE 2500;
BA_ "InvalidValue" SG_ 266 ALIVE_BCM_VOLTAGE "Fh";
BA_ "GenSigStartValue" SG_ 266 UBatt 9205;
BA_ "GenSigTimeoutTime_ALL" SG_ 266 UBatt 2500;
BA_ "GenSigTimeoutTime_ALL" SG_ 266 UBatt 2500;
BA_ "GenSigTimeoutTime_ALL" SG_ 266 UBatt 2500;
BA_ "GenSigTimeoutTime_ALL" SG_ 266 UBatt 2500;
BA_ "InvalidValue" SG_ 266 UBatt "3FFFh";
BA_ "GenSigStartValue" SG_ 266 LV_Batt_Temp 40;
BA_ "GenSigTimeoutTime_ALL" SG_ 266 LV_Batt_Temp 2500;
BA_ "InvalidValue" SG_ 266 LV_Batt_Temp "FFh";
BA_ "GenSigTimeoutTime_ALL" SG_ 266 LV_SOC 2500;
BA_ "InvalidValue" SG_ 266 LV_SOC "FFh";
BA_ "GenSigStartValue" SG_ 266 LV_Batt_Current 49152;
BA_ "GenSigTimeoutTime_ALL" SG_ 266 LV_Batt_Current 2500;
BA_ "InvalidValue" SG_ 266 LV_Batt_Current "FFFFh";
BA_ "GenSigTimeoutTime_ALL" SG_ 266 LV_BatteryType 2500;
BA_ "InvalidValue" SG_ 266 LV_BatteryType "-";
BA_ "GenSigTimeoutTime_ALL" SG_ 267 ALIVE_TRM_LIGHT 500;
BA_ "InvalidValue" SG_ 267 ALIVE_TRM_LIGHT "Fh";
BA_ "GenSigStartValue" SG_ 267 TrailerInput 3;
BA_ "GenSigTimeoutTime_ALL" SG_ 267 TrailerInput 500;
BA_ "InvalidValue" SG_ 267 TrailerInput "3h";
BA_ "GenSigStartValue" SG_ 267 TrailerSystemError 3;
BA_ "GenSigTimeoutTime_ALL" SG_ 267 TrailerSystemError 500;
BA_ "InvalidValue" SG_ 267 TrailerSystemError "3h";
BA_ "GenSigTimeoutTime_ALL" SG_ 267 TRM_VoltageStatus 500;
BA_ "InvalidValue" SG_ 267 TRM_VoltageStatus "3h";
BA_ "GenSigTimeoutTime_ALL" SG_ 267 TRM_STAT_BrakeLight 500;
BA_ "InvalidValue" SG_ 267 TRM_STAT_BrakeLight "3h";
BA_ "GenSigTimeoutTime_ALL" SG_ 267 TRM_STAT_FogLampRear 500;
BA_ "InvalidValue" SG_ 267 TRM_STAT_FogLampRear "3h";
BA_ "GenSigTimeoutTime_ALL" SG_ 267 TRM_STAT_PositionLight 500;
BA_ "InvalidValue" SG_ 267 TRM_STAT_PositionLight "3h";
BA_ "GenSigTimeoutTime_ALL" SG_ 267 TRM_STAT_TurnIndicators 500;
BA_ "InvalidValue" SG_ 267 TRM_STAT_TurnIndicators "Fh";
BA_ "GenSigTimeoutTime_ALL" SG_ 267 TRM_STAT_ReverseLight 500;
BA_ "InvalidValue" SG_ 267 TRM_STAT_ReverseLight "3h";
BA_ "GenSigTimeoutTime_ALL" SG_ 267 TRM_STAT_HWBrakeLightInput 500;
BA_ "InvalidValue" SG_ 267 TRM_STAT_HWBrakeLightInput "3h";
BA_ "GenSigTimeoutTime_ALL" SG_ 267 TRM_STAT_HWIndicatorInput 500;
BA_ "InvalidValue" SG_ 267 TRM_STAT_HWIndicatorInput "3h";
BA_ "GenSigTimeoutTime_ALL" SG_ 267 TRM_STAT_HWPosLightInput 500;
BA_ "InvalidValue" SG_ 267 TRM_STAT_HWPosLightInput "3h";
BA_ "GenSigTimeoutTime_ALL" SG_ 268 Checksum_0x10C 500;
BA_ "InvalidValue" SG_ 268 Checksum_0x10C "null";
BA_ "GenSigTimeoutTime_ALL" SG_ 268 Rolling_Counter_0x10C 500;
BA_ "InvalidValue" SG_ 268 Rolling_Counter_0x10C "Fh";
BA_ "GenSigTimeoutTime_ALL" SG_ 268 BCM_TboxAuthStatus 500;
BA_ "InvalidValue" SG_ 268 BCM_TboxAuthStatus "3h";
BA_ "GenSigTimeoutTime_ALL" SG_ 268 BCM_RandomNum32bit 500;
BA_ "InvalidValue" SG_ 268 BCM_RandomNum32bit "null";
BA_ "GenSigSendType" SG_ 269 MHU_APM_ReqWindow 2;
BA_ "InvalidValue" SG_ 269 MHU_APM_ReqWindow "3h";
BA_ "GenSigSendType" SG_ 269 MHU_BCM_RemoteDoorCtrl 2;
BA_ "GenSigStartValue" SG_ 269 MHU_BCM_RemoteDoorCtrl 2;
BA_ "InvalidValue" SG_ 269 MHU_BCM_RemoteDoorCtrl "3h";
BA_ "GenSigSendType" SG_ 269 MHU_BCM_reqTrunk 2;
BA_ "GenSigStartValue" SG_ 269 MHU_BCM_reqTrunk 2;
BA_ "InvalidValue" SG_ 269 MHU_BCM_reqTrunk "3h";
BA_ "GenSigSendType" SG_ 269 MHU_BCM_reqFrunk 2;
BA_ "InvalidValue" SG_ 269 MHU_BCM_reqFrunk "3h";
BA_ "GenSigSendType" SG_ 269 MHU_BCM_ReqSunroof 2;
BA_ "GenSigStartValue" SG_ 269 MHU_BCM_ReqSunroof 255;
BA_ "InvalidValue" SG_ 269 MHU_BCM_ReqSunroof "FFh";
BA_ "GenSigSendType" SG_ 269 TBOX_AuthCode_0x10D 2;
BA_ "GenSigSendType" SG_ 270 RemoteAccessKey 4;
BA_ "GenSigTimeoutTime_ALL" SG_ 270 RemoteAccessKey 500;
BA_ "InvalidValue" SG_ 270 RemoteAccessKey "Fh";
BA_ "GenSigSendType" SG_ 270 PassiveAccessTrunk 4;
BA_ "GenSigTimeoutTime_ALL" SG_ 270 PassiveAccessTrunk 500;
BA_ "InvalidValue" SG_ 270 PassiveAccessTrunk "3h";
BA_ "GenSigSendType" SG_ 270 ComfortOpen 4;
BA_ "GenSigStartValue" SG_ 270 ComfortOpen 3;
BA_ "GenSigTimeoutTime_ALL" SG_ 270 ComfortOpen 500;
BA_ "InvalidValue" SG_ 270 ComfortOpen "3h";
BA_ "GenSigSendType" SG_ 270 PassiveAccessDoor 4;
BA_ "GenSigTimeoutTime_ALL" SG_ 270 PassiveAccessDoor 500;
BA_ "InvalidValue" SG_ 270 PassiveAccessDoor "3h";
BA_ "GenSigSendType" SG_ 270 FksOpen 4;
BA_ "GenSigTimeoutTime_ALL" SG_ 270 FksOpen 500;
BA_ "InvalidValue" SG_ 270 FksOpen "3h";
BA_ "GenSigSendType" SG_ 271 MHU_SetHornOnOff 2;
BA_ "GenSigStartValue" SG_ 271 MHU_SetHornOnOff 2;
BA_ "InvalidValue" SG_ 271 MHU_SetHornOnOff "3h";
BA_ "GenSigSendType" SG_ 271 MHU_SetLowBeam 2;
BA_ "GenSigStartValue" SG_ 271 MHU_SetLowBeam 2;
BA_ "InvalidValue" SG_ 271 MHU_SetLowBeam "3h";
BA_ "GenSigSendType" SG_ 271 MHU_SetHighBeam 2;
BA_ "GenSigStartValue" SG_ 271 MHU_SetHighBeam 2;
BA_ "InvalidValue" SG_ 271 MHU_SetHighBeam "3h";
BA_ "GenSigSendType" SG_ 271 TBOX_AuthCode_0x10F 2;
BA_ "GenSigTimeoutTime_ALL" SG_ 274 CHKSM_BCM_CLAMP_STAT 500;
BA_ "InvalidValue" SG_ 274 CHKSM_BCM_CLAMP_STAT "null";
BA_ "GenSigTimeoutTime_ALL" SG_ 274 ALIVE_BCM_CLAMP_STAT 500;
BA_ "InvalidValue" SG_ 274 ALIVE_BCM_CLAMP_STAT "Fh";
BA_ "GenSigSendType" SG_ 274 RemoteFunctionState 4;
BA_ "GenSigTimeoutTime_ALL" SG_ 274 RemoteFunctionState 500;
BA_ "InvalidValue" SG_ 274 RemoteFunctionState "3h";
BA_ "GenSigTimeoutTime_ALL" SG_ 274 STAT_BLS 500;
BA_ "InvalidValue" SG_ 274 STAT_BLS "3h";
BA_ "GenSigTimeoutTime_ALL" SG_ 274 STAT_CL_50_L 500;
BA_ "InvalidValue" SG_ 274 STAT_CL_50_L "3h";
BA_ "GenSigSendType" SG_ 274 Clamp50AdviceRemoteStart 4;
BA_ "GenSigTimeoutTime_ALL" SG_ 274 Clamp50AdviceRemoteStart 500;
BA_ "InvalidValue" SG_ 274 Clamp50AdviceRemoteStart "3h";
BA_ "GenSigSendType" SG_ 274 Clamp50AdviceESS 4;
BA_ "GenSigTimeoutTime_ALL" SG_ 274 Clamp50AdviceESS 500;
BA_ "InvalidValue" SG_ 274 Clamp50AdviceESS "3h";
BA_ "GenSigTimeoutTime_ALL" SG_ 274 STAT_CL_R_L 500;
BA_ "InvalidValue" SG_ 274 STAT_CL_R_L "3h";
BA_ "GenSigTimeoutTime_ALL" SG_ 274 STAT_CL_15_1_L 500;
BA_ "InvalidValue" SG_ 274 STAT_CL_15_1_L "3h";
BA_ "GenSigTimeoutTime_ALL" SG_ 274 STAT_CL_15_1_DME_L 500;
BA_ "InvalidValue" SG_ 274 STAT_CL_15_1_DME_L "3h";
BA_ "GenSigTimeoutTime_ALL" SG_ 274 FobId 500;
BA_ "InvalidValue" SG_ 274 FobId "3h";
BA_ "GenSigTimeoutTime_ALL" SG_ 274 STAT_Terminal 500;
BA_ "InvalidValue" SG_ 274 STAT_Terminal "7h";
BA_ "GenSigTimeoutTime_ALL" SG_ 274 STAT_CL30_C_BEV 500;
BA_ "InvalidValue" SG_ 274 STAT_CL30_C_BEV "7h";
BA_ "GenSigTimeoutTime_ALL" SG_ 274 BCM_Clamp_Transport 500;
BA_ "InvalidValue" SG_ 274 BCM_Clamp_Transport "7h";
BA_ "GenSigTimeoutTime_ALL" SG_ 276 CHKSM_LVBAT_DATA 500;
BA_ "InvalidValue" SG_ 276 CHKSM_LVBAT_DATA "-";
BA_ "GenSigTimeoutTime_ALL" SG_ 276 ALIV_LVBAT_DATA 500;
BA_ "InvalidValue" SG_ 276 ALIV_LVBAT_DATA "Fh";
BA_ "GenSigTimeoutTime_ALL" SG_ 276 LV_ErrorSts 500;
BA_ "InvalidValue" SG_ 276 LV_ErrorSts "7h";
BA_ "GenSigTimeoutTime_ALL" SG_ 276 LV_MinCellVolt 500;
BA_ "InvalidValue" SG_ 276 LV_MinCellVolt "-";
BA_ "GenSigTimeoutTime_ALL" SG_ 276 LV_MaxCellVolt 500;
BA_ "InvalidValue" SG_ 276 LV_MaxCellVolt "-";
BA_ "GenSigStartValue" SG_ 276 LV_MinCellTemp 40;
BA_ "GenSigTimeoutTime_ALL" SG_ 276 LV_MinCellTemp 500;
BA_ "InvalidValue" SG_ 276 LV_MinCellTemp "-";
BA_ "GenSigStartValue" SG_ 276 LV_MaxCellTemp 40;
BA_ "GenSigTimeoutTime_ALL" SG_ 276 LV_MaxCellTemp 500;
BA_ "InvalidValue" SG_ 276 LV_MaxCellTemp "-";
BA_ "GenSigTimeoutTime_ALL" SG_ 276 LV_Discharger_Err 500;
BA_ "InvalidValue" SG_ 276 LV_Discharger_Err "-";
BA_ "GenSigTimeoutTime_ALL" SG_ 276 LV_Discharger_Sts 500;
BA_ "InvalidValue" SG_ 276 LV_Discharger_Sts "-";
BA_ "GenSigTimeoutTime_ALL" SG_ 276 LV_Charger_Err 500;
BA_ "InvalidValue" SG_ 276 LV_Charger_Err "-";
BA_ "GenSigTimeoutTime_ALL" SG_ 276 LV_Charger_Sts 500;
BA_ "InvalidValue" SG_ 276 LV_Charger_Sts "-";
BA_ "GenSigTimeoutTime_ALL" SG_ 276 LV_OverVoltage 500;
BA_ "InvalidValue" SG_ 276 LV_OverVoltage "-";
BA_ "GenSigTimeoutTime_ALL" SG_ 276 LV_UnderVoltage 500;
BA_ "InvalidValue" SG_ 276 LV_UnderVoltage "-";
BA_ "GenSigTimeoutTime_ALL" SG_ 276 LV_OverCurrent 500;
BA_ "InvalidValue" SG_ 276 LV_OverCurrent "-";
BA_ "GenSigTimeoutTime_ALL" SG_ 276 LV_UnderTemp 500;
BA_ "InvalidValue" SG_ 276 LV_UnderTemp "-";
BA_ "GenSigTimeoutTime_ALL" SG_ 276 LV_OverTemp 500;
BA_ "InvalidValue" SG_ 276 LV_OverTemp "-";
BA_ "GenSigTimeoutTime_ALL" SG_ 276 LV_OverCharge 500;
BA_ "InvalidValue" SG_ 276 LV_OverCharge "-";
BA_ "GenSigTimeoutTime_ALL" SG_ 276 LV_OverDischarge 500;
BA_ "InvalidValue" SG_ 276 LV_OverDischarge "-";
BA_ "GenSigTimeoutTime_ALL" SG_ 276 LV_CellBalance_Sts 500;
BA_ "InvalidValue" SG_ 276 LV_CellBalance_Sts "-";
BA_ "GenSigTimeoutTime_ALL" SG_ 276 LV_CellBalance_Error 500;
BA_ "InvalidValue" SG_ 276 LV_CellBalance_Error "-";
BA_ "GenSigTimeoutTime_ALL" SG_ 276 LV_ThermalRunaway 500;
BA_ "InvalidValue" SG_ 276 LV_ThermalRunaway "-";
BA_ "GenSigSendType" SG_ 277 BCM_ChildLock_Feedback 1;
BA_ "InvalidValue" SG_ 277 BCM_ChildLock_Feedback "null";
BA_ "GenSigSendType" SG_ 282 MHU_SET_WiperServicePositionMod 2;
BA_ "GenSigStartValue" SG_ 282 MHU_SET_WiperServicePositionMod 3;
BA_ "InvalidValue" SG_ 282 MHU_SET_WiperServicePositionMod "null";
BA_ "GenSigSendType" SG_ 282 MHU_Read_KeyFobOnCenterConsole 2;
BA_ "GenSigStartValue" SG_ 282 MHU_Read_KeyFobOnCenterConsole 2;
BA_ "InvalidValue" SG_ 282 MHU_Read_KeyFobOnCenterConsole "null";
BA_ "GenSigSendType" SG_ 283 TBOX_STAT_TerminalReq 2;
BA_ "GenSigStartValue" SG_ 283 TBOX_STAT_TerminalReq 6;
BA_ "InvalidValue" SG_ 283 TBOX_STAT_TerminalReq "7h";
BA_ "GenSigSendType" SG_ 283 TBOX_AuthCode_0x11B 2;
BA_ "InvalidValue" SG_ 283 TBOX_AuthCode_0x11B "null";
BA_ "GenSigSendType" SG_ 284 TBOX_FOTA_STAT_TerminalReq 2;
BA_ "InvalidValue" SG_ 284 TBOX_FOTA_STAT_TerminalReq "7h";
BA_ "GenSigTimeoutTime_ALL" SG_ 291 CHKSM_ACChargingInfo 2500;
BA_ "GenSigTimeoutTime_ALL" SG_ 291 CHKSM_ACChargingInfo 2500;
BA_ "GenSigTimeoutTime_ALL" SG_ 291 CHKSM_ACChargingInfo 2500;
BA_ "InvalidValue" SG_ 291 CHKSM_ACChargingInfo "FFh";
BA_ "GenSigTimeoutTime_ALL" SG_ 291 ALIVE_ACChargingInfo 2500;
BA_ "GenSigTimeoutTime_ALL" SG_ 291 ALIVE_ACChargingInfo 2500;
BA_ "GenSigTimeoutTime_ALL" SG_ 291 ALIVE_ACChargingInfo 2500;
BA_ "InvalidValue" SG_ 291 ALIVE_ACChargingInfo "Fh";
BA_ "GenSigTimeoutTime_ALL" SG_ 291 ACCharging_MaxChargingPower 2500;
BA_ "GenSigTimeoutTime_ALL" SG_ 291 ACCharging_MaxChargingPower 2500;
BA_ "GenSigTimeoutTime_ALL" SG_ 291 ACCharging_MaxChargingPower 2500;
BA_ "InvalidValue" SG_ 291 ACCharging_MaxChargingPower "3FFh";
BA_ "GenSigTimeoutTime_ALL" SG_ 291 CurrentACChargingPower 2500;
BA_ "GenSigTimeoutTime_ALL" SG_ 291 CurrentACChargingPower 2500;
BA_ "GenSigTimeoutTime_ALL" SG_ 291 CurrentACChargingPower 2500;
BA_ "InvalidValue" SG_ 291 CurrentACChargingPower "3FFh";
BA_ "GenSigTimeoutTime_ALL" SG_ 291 ACCharging_MaxCurrent 2500;
BA_ "GenSigTimeoutTime_ALL" SG_ 291 ACCharging_MaxCurrent 2500;
BA_ "GenSigTimeoutTime_ALL" SG_ 291 ACCharging_MaxCurrent 2500;
BA_ "InvalidValue" SG_ 291 ACCharging_MaxCurrent "FFFFh";
BA_ "GenSigTimeoutTime_ALL" SG_ 292 CHKSM_DCChargingInfo 2500;
BA_ "GenSigTimeoutTime_ALL" SG_ 292 CHKSM_DCChargingInfo 2500;
BA_ "GenSigTimeoutTime_ALL" SG_ 292 CHKSM_DCChargingInfo 2500;
BA_ "InvalidValue" SG_ 292 CHKSM_DCChargingInfo "FFh";
BA_ "GenSigTimeoutTime_ALL" SG_ 292 ALIVE_DCChargingInfo 2500;
BA_ "GenSigTimeoutTime_ALL" SG_ 292 ALIVE_DCChargingInfo 2500;
BA_ "InvalidValue" SG_ 292 ALIVE_DCChargingInfo "Fh";
BA_ "GenSigTimeoutTime_ALL" SG_ 292 DCCharging_MaxChargingPower 2500;
BA_ "GenSigTimeoutTime_ALL" SG_ 292 DCCharging_MaxChargingPower 2500;
BA_ "GenSigTimeoutTime_ALL" SG_ 292 DCCharging_MaxChargingPower 2500;
BA_ "InvalidValue" SG_ 292 DCCharging_MaxChargingPower "3FFh";
BA_ "GenSigTimeoutTime_ALL" SG_ 292 CurrentDCChargingPower 2500;
BA_ "GenSigTimeoutTime_ALL" SG_ 292 CurrentDCChargingPower 2500;
BA_ "GenSigTimeoutTime_ALL" SG_ 292 CurrentDCChargingPower 2500;
BA_ "InvalidValue" SG_ 292 CurrentDCChargingPower "3FFh";
BA_ "GenSigTimeoutTime_ALL" SG_ 292 DCCharging_MaxCurrent 2500;
BA_ "GenSigTimeoutTime_ALL" SG_ 292 DCCharging_MaxCurrent 2500;
BA_ "GenSigTimeoutTime_ALL" SG_ 292 DCCharging_MaxCurrent 2500;
BA_ "InvalidValue" SG_ 292 DCCharging_MaxCurrent "FFFFh";
BA_ "GenSigTimeoutTime_ALL" SG_ 294 MHU_ISA_SpeedLimitCon_Percent 500;
BA_ "InvalidValue" SG_ 294 MHU_ISA_SpeedLimitCon_Percent "7h";
BA_ "GenSigTimeoutTime_ALL" SG_ 294 MHU_ISA_Speed_Setting 500;
BA_ "InvalidValue" SG_ 294 MHU_ISA_Speed_Setting "Fh";
BA_ "GenSigTimeoutTime_ALL" SG_ 295 CHKSM_ADAS_LDW_LKA 800;
BA_ "GenSigTimeoutTime_ALL" SG_ 295 ALV_ADAS_LDW_LKA 800;
BA_ "InvalidValue" SG_ 295 ALV_ADAS_LDW_LKA "Fh";
BA_ "GenSigTimeoutTime_ALL" SG_ 295 ADAS_Mode1_status 800;
BA_ "InvalidValue" SG_ 295 ADAS_Mode1_status "3h";
BA_ "GenSigTimeoutTime_ALL" SG_ 295 ADAS_LKA_HOD_state 800;
BA_ "GenSigTimeoutTime_ALL" SG_ 295 ADAS_ECU_check 800;
BA_ "GenSigTimeoutTime_ALL" SG_ 295 ADAS_LA_sens_Feed 800;
BA_ "GenSigTimeoutTime_ALL" SG_ 295 ADAS_LKA_ICON_Feed 800;
BA_ "GenSigTimeoutTime_ALL" SG_ 295 ADAS_LDW_check 800;
BA_ "InvalidValue" SG_ 295 ADAS_LDW_check "3h";
BA_ "GenSigTimeoutTime_ALL" SG_ 295 ADAS_LKA_check 800;
BA_ "InvalidValue" SG_ 295 ADAS_LKA_check "3h";
BA_ "GenSigTimeoutTime_ALL" SG_ 295 ADAS_ALC_ICON_Feed 800;
BA_ "InvalidValue" SG_ 295 ADAS_ALC_ICON_Feed "7h";
BA_ "GenSigTimeoutTime_ALL" SG_ 295 ADAS_LA_popup 800;
BA_ "GenSigTimeoutTime_ALL" SG_ 295 ADAS_LA_AudWarning_Feed 800;
BA_ "InvalidValue" SG_ 295 ADAS_LA_AudWarning_Feed "3h";
BA_ "GenSigStartValue" SG_ 295 ADAS_LA_Mode_Feed 3;
BA_ "GenSigTimeoutTime_ALL" SG_ 295 ADAS_LA_Mode_Feed 800;
BA_ "GenSigTimeoutTime_ALL" SG_ 295 ADAS_HWA_ICON_Feed 800;
BA_ "InvalidValue" SG_ 295 ADAS_HWA_ICON_Feed "7h";
BA_ "GenSigTimeoutTime_ALL" SG_ 295 ADAS_LA_veh_pos_right 800;
BA_ "GenSigTimeoutTime_ALL" SG_ 295 ADAS_LA_veh_pos_left 800;
BA_ "GenSigTimeoutTime_ALL" SG_ 296 CHKSM_ADAS_FCW_RCTA 500;
BA_ "GenSigTimeoutTime_ALL" SG_ 296 ALV_ADAS_FCW_RCTA 500;
BA_ "InvalidValue" SG_ 296 ALV_ADAS_FCW_RCTA "Fh";
BA_ "GenSigTimeoutTime_ALL" SG_ 296 ADAS_RCTA_IndLeft 500;
BA_ "GenSigTimeoutTime_ALL" SG_ 296 ADAS_RCTA_IndRight 500;
BA_ "GenSigTimeoutTime_ALL" SG_ 296 ADAS_RCTA_SndWarn 500;
BA_ "GenSigTimeoutTime_ALL" SG_ 296 ADAS_IA_check 500;
BA_ "GenSigTimeoutTime_ALL" SG_ 296 ADAS_RCTA_state 500;
BA_ "GenSigTimeoutTime_ALL" SG_ 296 ADAS_RCTA_sens_Feed 500;
BA_ "GenSigTimeoutTime_ALL" SG_ 296 ADAS_IA_Left_warning 500;
BA_ "InvalidValue" SG_ 296 ADAS_IA_Left_warning "3h";
BA_ "GenSigStartValue" SG_ 296 ADAS_FCW_Mode_Feed 1;
BA_ "GenSigTimeoutTime_ALL" SG_ 296 ADAS_FCW_Mode_Feed 500;
BA_ "GenSigStartValue" SG_ 296 ADAS_FCW_Sens_Feed 1;
BA_ "GenSigTimeoutTime_ALL" SG_ 296 ADAS_FCW_Sens_Feed 500;
BA_ "GenSigStartValue" SG_ 296 ADAS_FCW_state 1;
BA_ "GenSigTimeoutTime_ALL" SG_ 296 ADAS_FCW_state 500;
BA_ "GenSigTimeoutTime_ALL" SG_ 296 ADAS_IA_state 500;
BA_ "InvalidValue" SG_ 296 ADAS_IA_state "7h";
BA_ "GenSigTimeoutTime_ALL" SG_ 296 ADAS_FCW_check 500;
BA_ "InvalidValue" SG_ 296 ADAS_FCW_check "3h";
BA_ "GenSigTimeoutTime_ALL" SG_ 296 ADAS_IA_Right_warning 500;
BA_ "InvalidValue" SG_ 296 ADAS_IA_Right_warning "3h";
BA_ "GenSigTimeoutTime_ALL" SG_ 296 ADAS_IA_Mode_Feed 500;
BA_ "GenSigTimeoutTime_ALL" SG_ 296 ADAS_RCTA_check 500;
BA_ "InvalidValue" SG_ 296 ADAS_RCTA_check "3h";
BA_ "GenSigStartValue" SG_ 296 ADAS_RCTA_Mode_Feed 1;
BA_ "GenSigTimeoutTime_ALL" SG_ 296 ADAS_RCTA_Mode_Feed 500;
BA_ "GenSigTimeoutTime_ALL" SG_ 296 ADAS_FCW_warning 500;
BA_ "InvalidValue" SG_ 296 ADAS_FCW_warning "3h";
BA_ "GenSigTimeoutTime_ALL" SG_ 296 ADAS_LA_LeftLaneColor_Feed 500;
BA_ "GenSigTimeoutTime_ALL" SG_ 296 ADAS_LA_RightLaneColor_Feed 500;
BA_ "GenSigTimeoutTime_ALL" SG_ 297 CHKSM_MHU_LocalSetting 5000;
BA_ "GenSigTimeoutTime_ALL" SG_ 297 ALIVE_MHU_LocalSetting 5000;
BA_ "InvalidValue" SG_ 297 ALIVE_MHU_LocalSetting "Fh";
BA_ "GenSigTimeoutTime_ALL" SG_ 297 MHU_SETTING_DMSWarning 5000;
BA_ "InvalidValue" SG_ 297 MHU_SETTING_DMSWarning "3h";
BA_ "GenSigTimeoutTime_ALL" SG_ 297 MHU_STAT_SelectedCountry 5000;
BA_ "InvalidValue" SG_ 297 MHU_STAT_SelectedCountry "3FFh";
BA_ "GenSigSendType" SG_ 303 CHKSM_BCM_TERMINAL 3;
BA_ "GenSigTimeoutTime_ALL" SG_ 303 CHKSM_BCM_TERMINAL 500;
BA_ "InvalidValue" SG_ 303 CHKSM_BCM_TERMINAL "null";
BA_ "GenSigSendType" SG_ 303 ALV_BCM_TERMINAL 3;
BA_ "GenSigTimeoutTime_ALL" SG_ 303 ALV_BCM_TERMINAL 500;
BA_ "InvalidValue" SG_ 303 ALV_BCM_TERMINAL "Fh";
BA_ "GenSigSendType" SG_ 303 ST_KL 3;
BA_ "GenSigTimeoutTime_ALL" SG_ 303 ST_KL 500;
BA_ "InvalidValue" SG_ 303 ST_KL "Fh";
BA_ "GenSigSendType" SG_ 303 ST_KL_KEY_VLD 3;
BA_ "GenSigTimeoutTime_ALL" SG_ 303 ST_KL_KEY_VLD 500;
BA_ "InvalidValue" SG_ 303 ST_KL_KEY_VLD "Fh";
BA_ "GenSigSendType" SG_ 303 ST_STCD_PENG 3;
BA_ "GenSigTimeoutTime_ALL" SG_ 303 ST_STCD_PENG 500;
BA_ "InvalidValue" SG_ 303 ST_STCD_PENG "3h";
BA_ "GenSigSendType" SG_ 303 ST_SSB 3;
BA_ "GenSigTimeoutTime_ALL" SG_ 303 ST_SSB 500;
BA_ "InvalidValue" SG_ 303 ST_SSB "3h";
BA_ "GenSigSendType" SG_ 303 RWDT_BLS 3;
BA_ "GenSigTimeoutTime_ALL" SG_ 303 RWDT_BLS 500;
BA_ "InvalidValue" SG_ 303 RWDT_BLS "Fh";
BA_ "GenSigSendType" SG_ 303 RQ_DRVG_RDI 3;
BA_ "GenSigTimeoutTime_ALL" SG_ 303 RQ_DRVG_RDI 500;
BA_ "InvalidValue" SG_ 303 RQ_DRVG_RDI "3h";
BA_ "GenSigSendType" SG_ 303 CTR_ENG_STOP 3;
BA_ "GenSigTimeoutTime_ALL" SG_ 303 CTR_ENG_STOP 500;
BA_ "InvalidValue" SG_ 303 CTR_ENG_STOP "3h";
BA_ "GenSigSendType" SG_ 303 ST_VEH_CON 3;
BA_ "GenSigTimeoutTime_ALL" SG_ 303 ST_VEH_CON 500;
BA_ "InvalidValue" SG_ 303 ST_VEH_CON "Fh";
BA_ "GenSigTimeoutTime_ALL" SG_ 304 CHKSM_ADAS_AEB 500;
BA_ "GenSigTimeoutTime_ALL" SG_ 304 ALV_ADAS_AEB 500;
BA_ "InvalidValue" SG_ 304 ALV_ADAS_AEB "Fh";
BA_ "GenSigStartValue" SG_ 304 ADAS_AEB_State 1;
BA_ "GenSigTimeoutTime_ALL" SG_ 304 ADAS_AEB_State 500;
BA_ "InvalidValue" SG_ 304 ADAS_AEB_State "3h";
BA_ "GenSigTimeoutTime_ALL" SG_ 304 ADAS_RAEB_check 500;
BA_ "InvalidValue" SG_ 304 ADAS_RAEB_check "3h";
BA_ "GenSigTimeoutTime_ALL" SG_ 304 ADAS_AEB_check 500;
BA_ "InvalidValue" SG_ 304 ADAS_AEB_check "3h";
BA_ "GenSigStartValue" SG_ 304 ADAS_AEB_Mode_Feed 1;
BA_ "GenSigTimeoutTime_ALL" SG_ 304 ADAS_AEB_Mode_Feed 500;
BA_ "InvalidValue" SG_ 304 ADAS_AEB_Mode_Feed "3h";
BA_ "GenSigStartValue" SG_ 304 ADAS_RAEB_Mode_Feed 1;
BA_ "GenSigTimeoutTime_ALL" SG_ 304 ADAS_RAEB_Mode_Feed 500;
BA_ "InvalidValue" SG_ 304 ADAS_RAEB_Mode_Feed "3h";
BA_ "GenSigTimeoutTime_ALL" SG_ 304 ADAS_AEB_Warning 500;
BA_ "InvalidValue" SG_ 304 ADAS_AEB_Warning "3h";
BA_ "GenSigTimeoutTime_ALL" SG_ 304 ADAS_RAEB_Warning 500;
BA_ "InvalidValue" SG_ 304 ADAS_RAEB_Warning "3h";
BA_ "GenSigSendType" SG_ 304 ADAS_RAEB_State 1;
BA_ "GenSigStartValue" SG_ 304 ADAS_RAEB_State 1;
BA_ "GenSigTimeoutTime_ALL" SG_ 304 ADAS_RAEB_State 500;
BA_ "InvalidValue" SG_ 304 ADAS_RAEB_State "3h";
BA_ "GenSigTimeoutTime_ALL" SG_ 307 CHKSM_ADAS_BSD 500;
BA_ "GenSigTimeoutTime_ALL" SG_ 307 ALV_ADAS_BSD 500;
BA_ "InvalidValue" SG_ 307 ALV_ADAS_BSD "Fh";
BA_ "GenSigTimeoutTime_ALL" SG_ 307 ADAS_BSD_check 500;
BA_ "InvalidValue" SG_ 307 ADAS_BSD_check "3h";
BA_ "GenSigTimeoutTime_ALL" SG_ 307 ADAS_BSD_state 500;
BA_ "GenSigTimeoutTime_ALL" SG_ 307 ADAS_BSD_AudChime_Feed 500;
BA_ "GenSigTimeoutTime_ALL" SG_ 307 ADAS_BSD_IndLeft 500;
BA_ "InvalidValue" SG_ 307 ADAS_BSD_IndLeft "3h";
BA_ "GenSigTimeoutTime_ALL" SG_ 307 ADAS_BSD_IndRight 500;
BA_ "InvalidValue" SG_ 307 ADAS_BSD_IndRight "3h";
BA_ "GenSigTimeoutTime_ALL" SG_ 307 ADAS_BSD_SndWarn 500;
BA_ "GenSigStartValue" SG_ 307 ADAS_BSD_Mode_Feed 1;
BA_ "GenSigTimeoutTime_ALL" SG_ 307 ADAS_BSD_Mode_Feed 500;
BA_ "GenSigTimeoutTime_ALL" SG_ 307 ADAS_BSD_sens_Feed 500;
BA_ "GenSigTimeoutTime_ALL" SG_ 308 CHKSM_ADAS_Speed_Display 500;
BA_ "GenSigTimeoutTime_ALL" SG_ 308 ALV_ADAS_Speed_Display 500;
BA_ "InvalidValue" SG_ 308 ALV_ADAS_Speed_Display "Fh";
BA_ "GenSigTimeoutTime_ALL" SG_ 308 ADAS_ISA_SpeedLimitCnt_Spd_Feed 500;
BA_ "InvalidValue" SG_ 308 ADAS_ISA_SpeedLimitCnt_Spd_Feed "Fh";
BA_ "GenSigTimeoutTime_ALL" SG_ 308 ADAS_ISA_SpeedLimitCnt_Per_Feed 500;
BA_ "InvalidValue" SG_ 308 ADAS_ISA_SpeedLimitCnt_Per_Feed "7h";
BA_ "GenSigTimeoutTime_ALL" SG_ 308 ADAS_far_lane_info 500;
BA_ "GenSigSendType" SG_ 310 PnC_activation 7;
BA_ "InvalidValue" SG_ 310 PnC_activation "null";
BA_ "GenSigSendType" SG_ 310 PnCandEIM_Switch 7;
BA_ "InvalidValue" SG_ 310 PnCandEIM_Switch "null";
BA_ "GenSigSendType" SG_ 310 PnC_trigger1 7;
BA_ "InvalidValue" SG_ 310 PnC_trigger1 "null";
BA_ "GenSigSendType" SG_ 310 PnC_trigger2 7;
BA_ "InvalidValue" SG_ 310 PnC_trigger2 "null";
BA_ "GenSigSendType" SG_ 310 PnC_feature_enable 7;
BA_ "InvalidValue" SG_ 310 PnC_feature_enable "null";
BA_ "GenSigSendType" SG_ 311 OK_OldSessionJoined 7;
BA_ "InvalidValue" SG_ 311 OK_OldSessionJoined "null";
BA_ "GenSigSendType" SG_ 311 OK_NewSessionEstablished 7;
BA_ "InvalidValue" SG_ 311 OK_NewSessionEstablished "null";
BA_ "GenSigSendType" SG_ 311 OK_CertificateExpireSoon 7;
BA_ "InvalidValue" SG_ 311 OK_CertificateExpireSoon "null";
BA_ "GenSigSendType" SG_ 311 PnC_OK 7;
BA_ "GenSigStartValue" SG_ 311 PnC_OK 2;
BA_ "InvalidValue" SG_ 311 PnC_OK "null";
BA_ "GenSigSendType" SG_ 311 Failed_CertificateNoAllowAtEVSE 7;
BA_ "InvalidValue" SG_ 311 Failed_CertificateNoAllowAtEVSE "null";
BA_ "GenSigSendType" SG_ 311 Failed_ContactorError 7;
BA_ "InvalidValue" SG_ 311 Failed_ContactorError "null";
BA_ "GenSigSendType" SG_ 311 Failed_NoChargeServiceSelectd 7;
BA_ "InvalidValue" SG_ 311 Failed_NoChargeServiceSelectd "null";
BA_ "GenSigSendType" SG_ 311 PnC_Failed 7;
BA_ "InvalidValue" SG_ 311 PnC_Failed "null";
BA_ "GenSigSendType" SG_ 311 Failed_ServiceIDInvalid 7;
BA_ "InvalidValue" SG_ 311 Failed_ServiceIDInvalid "null";
BA_ "GenSigSendType" SG_ 311 Falied_UnknownSession 7;
BA_ "InvalidValue" SG_ 311 Falied_UnknownSession "null";
BA_ "GenSigSendType" SG_ 311 Failed_SignatureError 7;
BA_ "InvalidValue" SG_ 311 Failed_SignatureError "null";
BA_ "GenSigSendType" SG_ 311 Failed_SequenceError 7;
BA_ "InvalidValue" SG_ 311 Failed_SequenceError "null";
BA_ "GenSigSendType" SG_ 311 Failed_CertChainError 7;
BA_ "InvalidValue" SG_ 311 Failed_CertChainError "null";
BA_ "GenSigSendType" SG_ 311 Failed_NoCertificateAvailable 7;
BA_ "InvalidValue" SG_ 311 Failed_NoCertificateAvailable "null";
BA_ "GenSigSendType" SG_ 311 Failed_CertificateRevoked 7;
BA_ "InvalidValue" SG_ 311 Failed_CertificateRevoked "null";
BA_ "GenSigSendType" SG_ 311 Failed_PaymentSelectionInvalid 7;
BA_ "InvalidValue" SG_ 311 Failed_PaymentSelectionInvalid "null";
BA_ "GenSigSendType" SG_ 311 Failed_WrongChargeParameter 7;
BA_ "InvalidValue" SG_ 311 Failed_WrongChargeParameter "null";
BA_ "GenSigSendType" SG_ 311 Failed_WrongEnergyTranferMode 7;
BA_ "InvalidValue" SG_ 311 Failed_WrongEnergyTranferMode "null";
BA_ "GenSigSendType" SG_ 311 Failed_ChallengeInvalid 7;
BA_ "InvalidValue" SG_ 311 Failed_ChallengeInvalid "null";
BA_ "GenSigSendType" SG_ 311 Failed_ContractCancelled 7;
BA_ "InvalidValue" SG_ 311 Failed_ContractCancelled "null";
BA_ "GenSigSendType" SG_ 311 Failed_MeteringSignatureNotValid 7;
BA_ "InvalidValue" SG_ 311 Failed_MeteringSignatureNotValid "null";
BA_ "GenSigSendType" SG_ 311 Failed_PowerDeliverNotApplied 7;
BA_ "InvalidValue" SG_ 311 Failed_PowerDeliverNotApplied "null";
BA_ "GenSigSendType" SG_ 311 Failed_TarrifSelectionInvalid 7;
BA_ "InvalidValue" SG_ 311 Failed_TarrifSelectionInvalid "null";
BA_ "GenSigSendType" SG_ 311 Failed_ChargingProfileInvalid 7;
BA_ "InvalidValue" SG_ 311 Failed_ChargingProfileInvalid "null";
BA_ "GenSigSendType" SG_ 311 Error_message_4 7;
BA_ "InvalidValue" SG_ 311 Error_message_4 "null";
BA_ "GenSigSendType" SG_ 311 Error_message_3 7;
BA_ "InvalidValue" SG_ 311 Error_message_3 "null";
BA_ "GenSigSendType" SG_ 311 Error_message_1 7;
BA_ "InvalidValue" SG_ 311 Error_message_1 "null";
BA_ "GenSigSendType" SG_ 311 Error_message_2 7;
BA_ "InvalidValue" SG_ 311 Error_message_2 "null";
BA_ "GenSigSendType" SG_ 311 PnC_ChargeSessionEnded 7;
BA_ "InvalidValue" SG_ 311 PnC_ChargeSessionEnded "null";
BA_ "GenSigSendType" SG_ 311 PnC_Status 7;
BA_ "InvalidValue" SG_ 311 PnC_Status "null";
BA_ "GenSigSendType" SG_ 311 PnC_Contract_Status 7;
BA_ "GenSigStartValue" SG_ 311 PnC_Contract_Status 1;
BA_ "InvalidValue" SG_ 311 PnC_Contract_Status "null";
BA_ "GenSigSendType" SG_ 311 Error_message_5 7;
BA_ "InvalidValue" SG_ 311 Error_message_5 "null";
BA_ "GenSigTimeoutTime_ALL" SG_ 312 CHKSM_ADAS_AVM_Sts 500;
BA_ "GenSigTimeoutTime_ALL" SG_ 312 ALV_ADAS_AVM_Sts 500;
BA_ "InvalidValue" SG_ 312 ALV_ADAS_AVM_Sts "Fh";
BA_ "GenSigTimeoutTime_ALL" SG_ 312 AVM_AutoDsplSts 500;
BA_ "InvalidValue" SG_ 312 AVM_AutoDsplSts "1";
BA_ "GenSigTimeoutTime_ALL" SG_ 312 AVM_auxiliarylineSts 500;
BA_ "GenSigTimeoutTime_ALL" SG_ 312 AVM_ShowAVMFdbck 500;
BA_ "InvalidValue" SG_ 312 AVM_ShowAVMFdbck "3h";
BA_ "GenSigTimeoutTime_ALL" SG_ 312 AVM_Sts 500;
BA_ "InvalidValue" SG_ 312 AVM_Sts "7h";
BA_ "GenSigTimeoutTime_ALL" SG_ 313 APA_SensorFaultStsSRR 500;
BA_ "GenSigTimeoutTime_ALL" SG_ 313 APA_SensorFaultStsSRL 500;
BA_ "GenSigTimeoutTime_ALL" SG_ 313 APA_SensorFaultStsSFR 500;
BA_ "GenSigTimeoutTime_ALL" SG_ 313 APA_SensorFaultStsSFL 500;
BA_ "GenSigTimeoutTime_ALL" SG_ 313 SECCAN_APA_Snsr 500;
BA_ "GenSigSendType" SG_ 317 SessionPaymentType 7;
BA_ "InvalidValue" SG_ 317 SessionPaymentType "null";
BA_ "GenSigStartValue" SG_ 318 APA_slot_ID_1_P0_X 8000;
BA_ "GenSigTimeoutTime_ALL" SG_ 318 APA_slot_ID_1_P0_X 500;
BA_ "InvalidValue" SG_ 318 APA_slot_ID_1_P0_X "3FFFh";
BA_ "GenSigStartValue" SG_ 318 APA_slot_ID_1_P0_Y 8000;
BA_ "GenSigTimeoutTime_ALL" SG_ 318 APA_slot_ID_1_P0_Y 500;
BA_ "InvalidValue" SG_ 318 APA_slot_ID_1_P0_Y "3FFFh";
BA_ "GenSigStartValue" SG_ 318 APA_slot_ID_1_P1_X 8000;
BA_ "GenSigTimeoutTime_ALL" SG_ 318 APA_slot_ID_1_P1_X 500;
BA_ "InvalidValue" SG_ 318 APA_slot_ID_1_P1_X "3FFFh";
BA_ "GenSigStartValue" SG_ 318 APA_slot_ID_1_P1_Y 8000;
BA_ "GenSigTimeoutTime_ALL" SG_ 318 APA_slot_ID_1_P1_Y 500;
BA_ "InvalidValue" SG_ 318 APA_slot_ID_1_P1_Y "3FFFh";
BA_ "GenSigStartValue" SG_ 319 APA_slot_ID_1_P2_X 8000;
BA_ "GenSigTimeoutTime_ALL" SG_ 319 APA_slot_ID_1_P2_X 500;
BA_ "InvalidValue" SG_ 319 APA_slot_ID_1_P2_X "3FFFh";
BA_ "GenSigStartValue" SG_ 319 APA_slot_ID_1_P2_Y 8000;
BA_ "GenSigTimeoutTime_ALL" SG_ 319 APA_slot_ID_1_P2_Y 500;
BA_ "InvalidValue" SG_ 319 APA_slot_ID_1_P2_Y "3FFFh";
BA_ "GenSigStartValue" SG_ 319 APA_slot_ID_1_P3_X 8000;
BA_ "GenSigTimeoutTime_ALL" SG_ 319 APA_slot_ID_1_P3_X 500;
BA_ "InvalidValue" SG_ 319 APA_slot_ID_1_P3_X "3FFFh";
BA_ "GenSigStartValue" SG_ 319 APA_slot_ID_1_P3_Y 8000;
BA_ "GenSigTimeoutTime_ALL" SG_ 319 APA_slot_ID_1_P3_Y 500;
BA_ "InvalidValue" SG_ 319 APA_slot_ID_1_P3_Y "3FFFh";
BA_ "GenSigTimeoutTime_ALL" SG_ 320 APA_ParkingSlotType1 500;
BA_ "GenSigTimeoutTime_ALL" SG_ 320 APA_slot_1 500;
BA_ "InvalidValue" SG_ 320 APA_slot_1 "fh";
BA_ "GenSigTimeoutTime_ALL" SG_ 320 SECCAN_APA_Slot1Info 500;
BA_ "GenSigStartValue" SG_ 321 APA_slot_ID_2_P0_X 8000;
BA_ "GenSigTimeoutTime_ALL" SG_ 321 APA_slot_ID_2_P0_X 500;
BA_ "InvalidValue" SG_ 321 APA_slot_ID_2_P0_X "3FFFh";
BA_ "GenSigStartValue" SG_ 321 APA_slot_ID_2_P0_Y 8000;
BA_ "GenSigTimeoutTime_ALL" SG_ 321 APA_slot_ID_2_P0_Y 500;
BA_ "InvalidValue" SG_ 321 APA_slot_ID_2_P0_Y "3FFFh";
BA_ "GenSigStartValue" SG_ 321 APA_slot_ID_2_P1_X 8000;
BA_ "GenSigTimeoutTime_ALL" SG_ 321 APA_slot_ID_2_P1_X 500;
BA_ "InvalidValue" SG_ 321 APA_slot_ID_2_P1_X "3FFFh";
BA_ "GenSigStartValue" SG_ 321 APA_slot_ID_2_P1_Y 8000;
BA_ "GenSigTimeoutTime_ALL" SG_ 321 APA_slot_ID_2_P1_Y 500;
BA_ "InvalidValue" SG_ 321 APA_slot_ID_2_P1_Y "3FFFh";
BA_ "GenSigStartValue" SG_ 322 APA_slot_ID_2_P2_X 8000;
BA_ "GenSigTimeoutTime_ALL" SG_ 322 APA_slot_ID_2_P2_X 500;
BA_ "InvalidValue" SG_ 322 APA_slot_ID_2_P2_X "3FFFh";
BA_ "GenSigStartValue" SG_ 322 APA_slot_ID_2_P2_Y 8000;
BA_ "GenSigTimeoutTime_ALL" SG_ 322 APA_slot_ID_2_P2_Y 500;
BA_ "InvalidValue" SG_ 322 APA_slot_ID_2_P2_Y "3FFFh";
BA_ "GenSigStartValue" SG_ 322 APA_slot_ID_2_P3_X 8000;
BA_ "GenSigTimeoutTime_ALL" SG_ 322 APA_slot_ID_2_P3_X 500;
BA_ "InvalidValue" SG_ 322 APA_slot_ID_2_P3_X "3FFFh";
BA_ "GenSigStartValue" SG_ 322 APA_slot_ID_2_P3_Y 8000;
BA_ "GenSigTimeoutTime_ALL" SG_ 322 APA_slot_ID_2_P3_Y 500;
BA_ "InvalidValue" SG_ 322 APA_slot_ID_2_P3_Y "3FFFh";
BA_ "GenSigTimeoutTime_ALL" SG_ 323 APA_ParkingSlotType2 500;
BA_ "GenSigTimeoutTime_ALL" SG_ 323 APA_slot_2 500;
BA_ "InvalidValue" SG_ 323 APA_slot_2 "fh";
BA_ "GenSigTimeoutTime_ALL" SG_ 323 SECCAN_APA_Slot2Info 500;
BA_ "GenSigStartValue" SG_ 324 APA_slot_ID_3_P0_X 8000;
BA_ "GenSigTimeoutTime_ALL" SG_ 324 APA_slot_ID_3_P0_X 500;
BA_ "InvalidValue" SG_ 324 APA_slot_ID_3_P0_X "3FFFh";
BA_ "GenSigStartValue" SG_ 324 APA_slot_ID_3_P0_Y 8000;
BA_ "GenSigTimeoutTime_ALL" SG_ 324 APA_slot_ID_3_P0_Y 500;
BA_ "InvalidValue" SG_ 324 APA_slot_ID_3_P0_Y "3FFFh";
BA_ "GenSigStartValue" SG_ 324 APA_slot_ID_3_P1_X 8000;
BA_ "GenSigTimeoutTime_ALL" SG_ 324 APA_slot_ID_3_P1_X 500;
BA_ "InvalidValue" SG_ 324 APA_slot_ID_3_P1_X "3FFFh";
BA_ "GenSigStartValue" SG_ 324 APA_slot_ID_3_P1_Y 8000;
BA_ "GenSigTimeoutTime_ALL" SG_ 324 APA_slot_ID_3_P1_Y 500;
BA_ "InvalidValue" SG_ 324 APA_slot_ID_3_P1_Y "3FFFh";
BA_ "GenSigStartValue" SG_ 325 APA_slot_ID_3_P2_X 8000;
BA_ "GenSigTimeoutTime_ALL" SG_ 325 APA_slot_ID_3_P2_X 500;
BA_ "InvalidValue" SG_ 325 APA_slot_ID_3_P2_X "3FFFh";
BA_ "GenSigStartValue" SG_ 325 APA_slot_ID_3_P2_Y 8000;
BA_ "GenSigTimeoutTime_ALL" SG_ 325 APA_slot_ID_3_P2_Y 500;
BA_ "InvalidValue" SG_ 325 APA_slot_ID_3_P2_Y "3FFFh";
BA_ "GenSigStartValue" SG_ 325 APA_slot_ID_3_P3_X 8000;
BA_ "GenSigTimeoutTime_ALL" SG_ 325 APA_slot_ID_3_P3_X 500;
BA_ "InvalidValue" SG_ 325 APA_slot_ID_3_P3_X "3FFFh";
BA_ "GenSigStartValue" SG_ 325 APA_slot_ID_3_P3_Y 8000;
BA_ "GenSigTimeoutTime_ALL" SG_ 325 APA_slot_ID_3_P3_Y 500;
BA_ "InvalidValue" SG_ 325 APA_slot_ID_3_P3_Y "3FFFh";
BA_ "GenSigTimeoutTime_ALL" SG_ 326 APA_slot_3 500;
BA_ "InvalidValue" SG_ 326 APA_slot_3 "fh";
BA_ "GenSigTimeoutTime_ALL" SG_ 326 APA_ParkingSlotType3 500;
BA_ "GenSigTimeoutTime_ALL" SG_ 326 SECCAN_APA_Slot3Info 500;
BA_ "GenSigStartValue" SG_ 327 APA_slot_ID_4_P0_X 8000;
BA_ "GenSigTimeoutTime_ALL" SG_ 327 APA_slot_ID_4_P0_X 500;
BA_ "InvalidValue" SG_ 327 APA_slot_ID_4_P0_X "3FFFh";
BA_ "GenSigStartValue" SG_ 327 APA_slot_ID_4_P0_Y 8000;
BA_ "GenSigTimeoutTime_ALL" SG_ 327 APA_slot_ID_4_P0_Y 500;
BA_ "InvalidValue" SG_ 327 APA_slot_ID_4_P0_Y "3FFFh";
BA_ "GenSigStartValue" SG_ 327 APA_slot_ID_4_P1_X 8000;
BA_ "GenSigTimeoutTime_ALL" SG_ 327 APA_slot_ID_4_P1_X 500;
BA_ "InvalidValue" SG_ 327 APA_slot_ID_4_P1_X "3FFFh";
BA_ "GenSigStartValue" SG_ 327 APA_slot_ID_4_P1_Y 8000;
BA_ "GenSigTimeoutTime_ALL" SG_ 327 APA_slot_ID_4_P1_Y 500;
BA_ "InvalidValue" SG_ 327 APA_slot_ID_4_P1_Y "3FFFh";
BA_ "GenSigStartValue" SG_ 328 APA_slot_ID_4_P2_X 8000;
BA_ "GenSigTimeoutTime_ALL" SG_ 328 APA_slot_ID_4_P2_X 500;
BA_ "InvalidValue" SG_ 328 APA_slot_ID_4_P2_X "3FFFh";
BA_ "GenSigStartValue" SG_ 328 APA_slot_ID_4_P2_Y 8000;
BA_ "GenSigTimeoutTime_ALL" SG_ 328 APA_slot_ID_4_P2_Y 500;
BA_ "InvalidValue" SG_ 328 APA_slot_ID_4_P2_Y "3FFFh";
BA_ "GenSigStartValue" SG_ 328 APA_slot_ID_4_P3_X 8000;
BA_ "GenSigTimeoutTime_ALL" SG_ 328 APA_slot_ID_4_P3_X 500;
BA_ "InvalidValue" SG_ 328 APA_slot_ID_4_P3_X "3FFFh";
BA_ "GenSigStartValue" SG_ 328 APA_slot_ID_4_P3_Y 8000;
BA_ "GenSigTimeoutTime_ALL" SG_ 328 APA_slot_ID_4_P3_Y 500;
BA_ "InvalidValue" SG_ 328 APA_slot_ID_4_P3_Y "3FFFh";
BA_ "GenSigTimeoutTime_ALL" SG_ 329 APA_ParkingSlotType4 500;
BA_ "GenSigTimeoutTime_ALL" SG_ 329 APA_slot_4 500;
BA_ "InvalidValue" SG_ 329 APA_slot_4 "fh";
BA_ "GenSigTimeoutTime_ALL" SG_ 329 SECCAN_APA_Slot4Info 500;
BA_ "GenSigStartValue" SG_ 330 APA_slot_ID_5_P0_X 8000;
BA_ "GenSigTimeoutTime_ALL" SG_ 330 APA_slot_ID_5_P0_X 500;
BA_ "InvalidValue" SG_ 330 APA_slot_ID_5_P0_X "3FFFh";
BA_ "GenSigStartValue" SG_ 330 APA_slot_ID_5_P0_Y 8000;
BA_ "GenSigTimeoutTime_ALL" SG_ 330 APA_slot_ID_5_P0_Y 500;
BA_ "InvalidValue" SG_ 330 APA_slot_ID_5_P0_Y "3FFFh";
BA_ "GenSigStartValue" SG_ 330 APA_slot_ID_5_P1_X 8000;
BA_ "GenSigTimeoutTime_ALL" SG_ 330 APA_slot_ID_5_P1_X 500;
BA_ "InvalidValue" SG_ 330 APA_slot_ID_5_P1_X "3FFFh";
BA_ "GenSigStartValue" SG_ 330 APA_slot_ID_5_P1_Y 8000;
BA_ "GenSigTimeoutTime_ALL" SG_ 330 APA_slot_ID_5_P1_Y 500;
BA_ "InvalidValue" SG_ 330 APA_slot_ID_5_P1_Y "3FFFh";
BA_ "GenSigStartValue" SG_ 331 APA_slot_ID_5_P2_X 8000;
BA_ "GenSigTimeoutTime_ALL" SG_ 331 APA_slot_ID_5_P2_X 500;
BA_ "InvalidValue" SG_ 331 APA_slot_ID_5_P2_X "3FFFh";
BA_ "GenSigStartValue" SG_ 331 APA_slot_ID_5_P2_Y 8000;
BA_ "GenSigTimeoutTime_ALL" SG_ 331 APA_slot_ID_5_P2_Y 500;
BA_ "InvalidValue" SG_ 331 APA_slot_ID_5_P2_Y "3FFFh";
BA_ "GenSigStartValue" SG_ 331 APA_slot_ID_5_P3_X 8000;
BA_ "GenSigTimeoutTime_ALL" SG_ 331 APA_slot_ID_5_P3_X 500;
BA_ "InvalidValue" SG_ 331 APA_slot_ID_5_P3_X "3FFFh";
BA_ "GenSigStartValue" SG_ 331 APA_slot_ID_5_P3_Y 8000;
BA_ "GenSigTimeoutTime_ALL" SG_ 331 APA_slot_ID_5_P3_Y 500;
BA_ "InvalidValue" SG_ 331 APA_slot_ID_5_P3_Y "3FFFh";
BA_ "GenSigTimeoutTime_ALL" SG_ 332 APA_ParkingSlotType5 500;
BA_ "GenSigTimeoutTime_ALL" SG_ 332 APA_slot_5 500;
BA_ "InvalidValue" SG_ 332 APA_slot_5 "fh";
BA_ "GenSigTimeoutTime_ALL" SG_ 332 SECCAN_APA_Slot5Info 500;
BA_ "GenSigStartValue" SG_ 333 APA_slot_ID_6_P0_X 8000;
BA_ "GenSigTimeoutTime_ALL" SG_ 333 APA_slot_ID_6_P0_X 500;
BA_ "InvalidValue" SG_ 333 APA_slot_ID_6_P0_X "3FFFh";
BA_ "GenSigStartValue" SG_ 333 APA_slot_ID_6_P0_Y 8000;
BA_ "GenSigTimeoutTime_ALL" SG_ 333 APA_slot_ID_6_P0_Y 500;
BA_ "InvalidValue" SG_ 333 APA_slot_ID_6_P0_Y "3FFFh";
BA_ "GenSigStartValue" SG_ 333 APA_slot_ID_6_P1_X 8000;
BA_ "GenSigTimeoutTime_ALL" SG_ 333 APA_slot_ID_6_P1_X 500;
BA_ "InvalidValue" SG_ 333 APA_slot_ID_6_P1_X "3FFFh";
BA_ "GenSigStartValue" SG_ 333 APA_slot_ID_6_P1_Y 8000;
BA_ "GenSigTimeoutTime_ALL" SG_ 333 APA_slot_ID_6_P1_Y 500;
BA_ "InvalidValue" SG_ 333 APA_slot_ID_6_P1_Y "3FFFh";
BA_ "GenSigStartValue" SG_ 334 APA_slot_ID_6_P2_X 8000;
BA_ "GenSigTimeoutTime_ALL" SG_ 334 APA_slot_ID_6_P2_X 500;
BA_ "InvalidValue" SG_ 334 APA_slot_ID_6_P2_X "3FFFh";
BA_ "GenSigStartValue" SG_ 334 APA_slot_ID_6_P2_Y 8000;
BA_ "GenSigTimeoutTime_ALL" SG_ 334 APA_slot_ID_6_P2_Y 500;
BA_ "InvalidValue" SG_ 334 APA_slot_ID_6_P2_Y "3FFFh";
BA_ "GenSigStartValue" SG_ 334 APA_slot_ID_6_P3_X 8000;
BA_ "GenSigTimeoutTime_ALL" SG_ 334 APA_slot_ID_6_P3_X 500;
BA_ "InvalidValue" SG_ 334 APA_slot_ID_6_P3_X "3FFFh";
BA_ "GenSigStartValue" SG_ 334 APA_slot_ID_6_P3_Y 8000;
BA_ "GenSigTimeoutTime_ALL" SG_ 334 APA_slot_ID_6_P3_Y 500;
BA_ "InvalidValue" SG_ 334 APA_slot_ID_6_P3_Y "3FFFh";
BA_ "GenSigTimeoutTime_ALL" SG_ 335 APA_ParkingSlotType6 500;
BA_ "GenSigTimeoutTime_ALL" SG_ 335 APA_slot_6 500;
BA_ "InvalidValue" SG_ 335 APA_slot_6 "fh";
BA_ "GenSigTimeoutTime_ALL" SG_ 335 SECCAN_APA_Slot6Info 500;
BA_ "GenSigTimeoutTime_ALL" SG_ 357 CHSKM_VCU_ChargingConnection 500;
BA_ "GenSigTimeoutTime_ALL" SG_ 357 CHSKM_VCU_ChargingConnection 200;
BA_ "GenSigTimeoutTime_ALL" SG_ 357 CHSKM_VCU_ChargingConnection 200;
BA_ "InvalidValue" SG_ 357 CHSKM_VCU_ChargingConnection "null";
BA_ "GenSigTimeoutTime_ALL" SG_ 357 ALV_VCU_ChargingConnection 200;
BA_ "GenSigTimeoutTime_ALL" SG_ 357 ALV_VCU_ChargingConnection 500;
BA_ "GenSigTimeoutTime_ALL" SG_ 357 ALV_VCU_ChargingConnection 200;
BA_ "InvalidValue" SG_ 357 ALV_VCU_ChargingConnection "Fh";
BA_ "GenSigTimeoutTime_ALL" SG_ 357 VCU_AcChgGunIn 200;
BA_ "GenSigTimeoutTime_ALL" SG_ 357 VCU_AcChgGunIn 500;
BA_ "InvalidValue" SG_ 357 VCU_AcChgGunIn "null";
BA_ "GenSigTimeoutTime_ALL" SG_ 357 VCU_DCChgGunIn 200;
BA_ "GenSigTimeoutTime_ALL" SG_ 357 VCU_DCChgGunIn 500;
BA_ "InvalidValue" SG_ 357 VCU_DCChgGunIn "null";
BA_ "GenSigTimeoutTime_ALL" SG_ 357 VCU_CPValue 200;
BA_ "GenSigTimeoutTime_ALL" SG_ 357 VCU_CPValue 500;
BA_ "GenSigStartValue" SG_ 357 VCU_ACChargingVoltage 1;
BA_ "GenSigTimeoutTime_ALL" SG_ 357 VCU_ACChargingVoltage 200;
BA_ "GenSigTimeoutTime_ALL" SG_ 357 VCU_ACChargingVoltage 500;
BA_ "InvalidValue" SG_ 357 VCU_ACChargingVoltage "Fh";
BA_ "GenSigStartValue" SG_ 357 VCU_MinCurrentOfACCharging 1;
BA_ "GenSigTimeoutTime_ALL" SG_ 357 VCU_MinCurrentOfACCharging 200;
BA_ "GenSigTimeoutTime_ALL" SG_ 357 VCU_MinCurrentOfACCharging 500;
BA_ "InvalidValue" SG_ 357 VCU_MinCurrentOfACCharging "7h";
BA_ "GenSigTimeoutTime_ALL" SG_ 357 VCU_MaxCurrentOfACCharging 200;
BA_ "GenSigTimeoutTime_ALL" SG_ 357 VCU_MaxCurrentOfACCharging 500;
BA_ "InvalidValue" SG_ 357 VCU_MaxCurrentOfACCharging "3Fh";
BA_ "GenSigTimeoutTime_ALL" SG_ 360 Checksum_MHU_FEEDBACK_APA 1000;
BA_ "InvalidValue" SG_ 360 Checksum_MHU_FEEDBACK_APA "null";
BA_ "GenSigTimeoutTime_ALL" SG_ 360 Rolling_Counter_MHU_FEEDBACK_APA 1000;
BA_ "InvalidValue" SG_ 360 Rolling_Counter_MHU_FEEDBACK_APA "Fh";
BA_ "GenSigTimeoutTime_ALL" SG_ 360 MHU_AVM_AutoDsplReq 1000;
BA_ "InvalidValue" SG_ 360 MHU_AVM_AutoDsplReq "1h";
BA_ "GenSigTimeoutTime_ALL" SG_ 360 MHU_AVM_auxiliarylineReq 1000;
BA_ "InvalidValue" SG_ 360 MHU_AVM_auxiliarylineReq "1h";
BA_ "GenSigTimeoutTime_ALL" SG_ 360 MHU_AVM_ShowAVMReq 1000;
BA_ "InvalidValue" SG_ 360 MHU_AVM_ShowAVMReq "3h";
BA_ "GenSigTimeoutTime_ALL" SG_ 360 MHU_PA_Button 1000;
BA_ "GenSigTimeoutTime_ALL" SG_ 360 MHU_APA_RecoverParking 1000;
BA_ "InvalidValue" SG_ 360 MHU_APA_RecoverParking "1h";
BA_ "GenSigTimeoutTime_ALL" SG_ 360 MHU_APA_FuncMode 1000;
BA_ "InvalidValue" SG_ 360 MHU_APA_FuncMode "3h";
BA_ "GenSigTimeoutTime_ALL" SG_ 360 MHU_APA_ParkOutTypeConfirm 1000;
BA_ "InvalidValue" SG_ 360 MHU_APA_ParkOutTypeConfirm "3h";
BA_ "GenSigTimeoutTime_ALL" SG_ 360 MHU_APA_ParkOutModeConfirm 1000;
BA_ "InvalidValue" SG_ 360 MHU_APA_ParkOutModeConfirm "3h";
BA_ "GenSigTimeoutTime_ALL" SG_ 360 MHU_APA_ShowAPAReq 1000;
BA_ "InvalidValue" SG_ 360 MHU_APA_ShowAPAReq "3h";
BA_ "GenSigTimeoutTime_ALL" SG_ 360 MHU_APA_ParkingStartReq 1000;
BA_ "InvalidValue" SG_ 360 MHU_APA_ParkingStartReq "3h";
BA_ "GenSigTimeoutTime_ALL" SG_ 360 MHU_APAParkOutDircnConfirm 1000;
BA_ "InvalidValue" SG_ 360 MHU_APAParkOutDircnConfirm "3h";
BA_ "GenSigTimeoutTime_ALL" SG_ 360 MHU_APA_Slotselect 1000;
BA_ "InvalidValue" SG_ 360 MHU_APA_Slotselect "Fh";
BA_ "GenSigTimeoutTime_ALL" SG_ 372 CHSKM_BMS_CurMeas 100;
BA_ "GenSigTimeoutTime_ALL" SG_ 372 CHSKM_BMS_CurMeas 100;
BA_ "GenSigTimeoutTime_ALL" SG_ 372 CHSKM_BMS_CurMeas 200;
BA_ "InvalidValue" SG_ 372 CHSKM_BMS_CurMeas "null";
BA_ "GenSigTimeoutTime_ALL" SG_ 372 ALV_BMS_CurMeas 100;
BA_ "GenSigTimeoutTime_ALL" SG_ 372 ALV_BMS_CurMeas 100;
BA_ "GenSigTimeoutTime_ALL" SG_ 372 ALV_BMS_CurMeas 100;
BA_ "InvalidValue" SG_ 372 ALV_BMS_CurMeas "Fh";
BA_ "GenSigStartValue" SG_ 372 BMS_PackCur_MEAS 32768;
BA_ "GenSigTimeoutTime_ALL" SG_ 372 BMS_PackCur_MEAS 200;
BA_ "GenSigTimeoutTime_ALL" SG_ 372 BMS_PackCur_MEAS 100;
BA_ "GenSigTimeoutTime_ALL" SG_ 372 BMS_PackCur_MEAS 100;
BA_ "InvalidValue" SG_ 372 BMS_PackCur_MEAS "FFFFh";
BA_ "GenSigTimeoutTime_ALL" SG_ 374 Checksum_0x176 200;
BA_ "GenSigTimeoutTime_ALL" SG_ 374 Checksum_0x176 500;
BA_ "GenSigTimeoutTime_ALL" SG_ 374 Checksum_0x176 200;
BA_ "InvalidValue" SG_ 374 Checksum_0x176 "null";
BA_ "GenSigTimeoutTime_ALL" SG_ 374 Rolling_Counter_0x176 200;
BA_ "GenSigTimeoutTime_ALL" SG_ 374 Rolling_Counter_0x176 200;
BA_ "GenSigTimeoutTime_ALL" SG_ 374 Rolling_Counter_0x176 500;
BA_ "InvalidValue" SG_ 374 Rolling_Counter_0x176 "Fh";
BA_ "GenSigTimeoutTime_ALL" SG_ 374 BMS_HVPackVol_MEAS 500;
BA_ "GenSigTimeoutTime_ALL" SG_ 374 BMS_HVPackVol_MEAS 200;
BA_ "GenSigTimeoutTime_ALL" SG_ 374 BMS_HVPackVol_MEAS 200;
BA_ "InvalidValue" SG_ 374 BMS_HVPackVol_MEAS "FFFFh";
BA_ "GenSigTimeoutTime_ALL" SG_ 374 BMS_HVLinkVol_MEAS 200;
BA_ "GenSigTimeoutTime_ALL" SG_ 374 BMS_HVLinkVol_MEAS 200;
BA_ "GenSigTimeoutTime_ALL" SG_ 374 BMS_HVLinkVol_MEAS 500;
BA_ "InvalidValue" SG_ 374 BMS_HVLinkVol_MEAS "FFFFh";
BA_ "GenSigTimeoutTime_ALL" SG_ 376 CHKSM_YSS_LongAcc 100;
BA_ "GenSigTimeoutTime_ALL" SG_ 376 CHKSM_YSS_LongAcc 100;
BA_ "InvalidValue" SG_ 376 CHKSM_YSS_LongAcc "null";
BA_ "GenSigTimeoutTime_ALL" SG_ 376 ALV_YSS_LongAcc 100;
BA_ "GenSigTimeoutTime_ALL" SG_ 376 ALV_YSS_LongAcc 100;
BA_ "InvalidValue" SG_ 376 ALV_YSS_LongAcc "Fh";
BA_ "GenSigTimeoutTime_ALL" SG_ 376 YSS_LONG_ACCUNFILTERED_QUAL 100;
BA_ "GenSigTimeoutTime_ALL" SG_ 376 YSS_LONG_ACCUNFILTERED_QUAL 100;
BA_ "GenSigTimeoutTime_ALL" SG_ 376 YSS_LONG_ACC_UNFILTERED 100;
BA_ "GenSigTimeoutTime_ALL" SG_ 376 YSS_LONG_ACC_UNFILTERED 100;
BA_ "InvalidValue" SG_ 376 YSS_LONG_ACC_UNFILTERED "FFFh";
BA_ "GenSigTimeoutTime_ALL" SG_ 376 YSS_LONG_ACC_QUAL 100;
BA_ "GenSigTimeoutTime_ALL" SG_ 376 YSS_LONG_ACC_QUAL 100;
BA_ "GenSigTimeoutTime_ALL" SG_ 376 YSS_LONG_ACC 100;
BA_ "GenSigTimeoutTime_ALL" SG_ 376 YSS_LONG_ACC 100;
BA_ "InvalidValue" SG_ 376 YSS_LONG_ACC "FFFFh";
BA_ "GenSigTimeoutTime_ALL" SG_ 377 CHKSM_YSS_LateralAcc 100;
BA_ "GenSigTimeoutTime_ALL" SG_ 377 CHKSM_YSS_LateralAcc 100;
BA_ "InvalidValue" SG_ 377 CHKSM_YSS_LateralAcc "null";
BA_ "GenSigTimeoutTime_ALL" SG_ 377 ALV_YSS_LateralAcc 100;
BA_ "GenSigTimeoutTime_ALL" SG_ 377 ALV_YSS_LateralAcc 100;
BA_ "InvalidValue" SG_ 377 ALV_YSS_LateralAcc "Fh";
BA_ "GenSigTimeoutTime_ALL" SG_ 377 YSS_LAT_ACCUNFILTERED_QUAL 100;
BA_ "GenSigTimeoutTime_ALL" SG_ 377 YSS_LAT_ACCUNFILTERED_QUAL 100;
BA_ "GenSigTimeoutTime_ALL" SG_ 377 YSS_LAT_ACC_UNFILTERED 100;
BA_ "GenSigTimeoutTime_ALL" SG_ 377 YSS_LAT_ACC_UNFILTERED 100;
BA_ "InvalidValue" SG_ 377 YSS_LAT_ACC_UNFILTERED "FFFh";
BA_ "GenSigTimeoutTime_ALL" SG_ 377 YSS_LAT_ACC_QUAL 100;
BA_ "GenSigTimeoutTime_ALL" SG_ 377 YSS_LAT_ACC_QUAL 100;
BA_ "GenSigTimeoutTime_ALL" SG_ 377 YSS_LAT_ACC 100;
BA_ "GenSigTimeoutTime_ALL" SG_ 377 YSS_LAT_ACC 100;
BA_ "InvalidValue" SG_ 377 YSS_LAT_ACC "FFFFh";
BA_ "GenSigTimeoutTime_ALL" SG_ 382 CHKSM_SAS_Sensor 200;
BA_ "GenSigTimeoutTime_ALL" SG_ 382 CHKSM_SAS_Sensor 100;
BA_ "InvalidValue" SG_ 382 CHKSM_SAS_Sensor "null";
BA_ "GenSigTimeoutTime_ALL" SG_ 382 ALV_SAS_Sensor 100;
BA_ "GenSigTimeoutTime_ALL" SG_ 382 ALV_SAS_Sensor 200;
BA_ "InvalidValue" SG_ 382 ALV_SAS_Sensor "Fh";
BA_ "GenSigTimeoutTime_ALL" SG_ 382 SAS_SASStsSnsr 100;
BA_ "GenSigTimeoutTime_ALL" SG_ 382 SAS_SASStsSnsr 200;
BA_ "InvalidValue" SG_ 382 SAS_SASStsSnsr "null";
BA_ "GenSigStartValue" SG_ 382 SAS_SteerWhlRotSpd 8192;
BA_ "GenSigTimeoutTime_ALL" SG_ 382 SAS_SteerWhlRotSpd 200;
BA_ "GenSigTimeoutTime_ALL" SG_ 382 SAS_SteerWhlRotSpd 100;
BA_ "InvalidValue" SG_ 382 SAS_SteerWhlRotSpd "3FFFh";
BA_ "GenSigTimeoutTime_ALL" SG_ 382 SAS_SteerWhlRotSpdStatus 100;
BA_ "GenSigTimeoutTime_ALL" SG_ 382 SAS_SteerWhlRotSpdStatus 200;
BA_ "InvalidValue" SG_ 382 SAS_SteerWhlRotSpdStatus "null";
BA_ "GenSigTimeoutTime_ALL" SG_ 382 SAS_SASFailure 100;
BA_ "GenSigTimeoutTime_ALL" SG_ 382 SAS_SASFailure 200;
BA_ "InvalidValue" SG_ 382 SAS_SASFailure "null";
BA_ "GenSigTimeoutTime_ALL" SG_ 382 SAS_Calibrated 100;
BA_ "GenSigTimeoutTime_ALL" SG_ 382 SAS_Calibrated 200;
BA_ "InvalidValue" SG_ 382 SAS_Calibrated "null";
BA_ "GenSigTimeoutTime_ALL" SG_ 382 SAS_SteerWheelAngleValid 100;
BA_ "GenSigTimeoutTime_ALL" SG_ 382 SAS_SteerWheelAngleValid 200;
BA_ "InvalidValue" SG_ 382 SAS_SteerWheelAngleValid "3h";
BA_ "GenSigTimeoutTime_ALL" SG_ 382 SAS_SteerWheelAngle 200;
BA_ "GenSigTimeoutTime_ALL" SG_ 382 SAS_SteerWheelAngle 100;
BA_ "InvalidValue" SG_ 382 SAS_SteerWheelAngle "FFFFh";
BA_ "GenSigTimeoutTime_ALL" SG_ 385 VCU_Debug1 500;
BA_ "InvalidValue" SG_ 385 VCU_Debug1 "null";
BA_ "GenSigTimeoutTime_ALL" SG_ 385 VCU_Debug2 500;
BA_ "InvalidValue" SG_ 385 VCU_Debug2 "null";
BA_ "GenSigTimeoutTime_ALL" SG_ 385 VCU_Debug3 500;
BA_ "InvalidValue" SG_ 385 VCU_Debug3 "null";
BA_ "GenSigTimeoutTime_ALL" SG_ 385 VCU_Debug4 500;
BA_ "InvalidValue" SG_ 385 VCU_Debug4 "null";

VAL_ 18 CPD_MHU_Climate_control 0 "init" 1 "Open Climate" 2 "Reserved" 3 "Reserved";
VAL_ 128 ADAS_TSR_PopUp_Feed 0 "Off" 1 "Pop Up 1" 2 "Pop Up 2" 3 "Pop Up 3" 4 "Pop Up 4" 5 "Pop Up 5" 6 "Pop Up 6" 7 "Pop Up 7" 8 "Pop Up 8" 9 "Pop Up 9" 10 "Pop Up 10" 11 "Reserved" 12 "Reserved" 13 "Reserved" 14 "Reserved" 15 "Invalid";
VAL_ 128 ADAS_TSR_SLAert_Feed 0 "OFF" 1 "Speed Limit" 2 "Speed Limit + 5" 3 "Speed Limit + 10";
VAL_ 128 ADAS_TSR_Typ2_value 0 "No value" 1 "5" 2 "10" 3 "15" 4 "20" 5 "25" 6 "30" 7 "35" 8 "40" 9 "45" 10 "50" 11 "55" 12 "60" 13 "65" 14 "70" 15 "75" 16 "80" 17 "85" 18 "90" 19 "95" 20 "100" 21 "105" 22 "110" 23 "115" 24 "120" 25 "125" 26 "130" 27 "135" 28 "140" 29 "145" 30 "150" 31 "155";
VAL_ 128 ADAS_TSR_Typ1 0 "No detected" 1 "Maximum Speed Limit" 2 "End of speed limit sign" 3 "Invalid value" 4 "Reserve" 5 "Resever";
VAL_ 128 ADAS_TSR_Typ1_value 0 "No value" 1 "5" 2 "10" 3 "15" 4 "20" 5 "25" 6 "30" 7 "35" 8 "40" 9 "45" 10 "50" 11 "55" 12 "60" 13 "65" 14 "70" 15 "75" 16 "80" 17 "85" 18 "90" 19 "95" 20 "100" 21 "105" 22 "110" 23 "115" 24 "120" 25 "125" 26 "130" 27 "135" 28 "140" 29 "145" 30 "150" 31 "155";
VAL_ 128 ADAS_TSR_Warning_audible 0 "Off" 1 "On";
VAL_ 128 ADAS_TSR_Typ2_Flashing_Warning 0 "Off" 1 "On";
VAL_ 128 ADAS_TSR_Mode_Feed 0 "Off" 1 "On" 2 "reserved" 3 "Reserved";
VAL_ 128 ADAS_TSR_AudWarning_Feed 0 "Off" 1 "On";
VAL_ 128 ADAS_TSR_Typ1_Flashing_Warning 0 "Off" 1 "On";
VAL_ 128 ADAS_TSR_Typ3 0 "No detected" 1 "End of signed prohibitions" 2 "End of tunnel" 3 "Tunnel" 4 "Snow" 5 "Slippery road" 6 "Pedestrian crossing" 7 "Children" 8 "No passing" 9 "No turn left" 10 "No turn right" 11 "No U turn" 12 "Stop" 13 "Car prohibited" 14 "No entry" 15 "No throughfare";
VAL_ 128 ADAS_TSR_Typ2 0 "No detected" 1 "Camping zone" 2 "Highway" 3 "Town zone" 4 "End of town zone" 5 "Express way" 6 "Bicycle way" 7 "Night" 8 "Minimun speed limit" 9 "Ramp" 10 "Exit" 11 "Curve" 12 "School zone" 13 "Reserved" 14 "Reserved" 15 "Reserved";
VAL_ 128 ADAS_TSR_State 0 "Off" 1 "On" 2 "Scam error" 3 "reserved";
VAL_ 130 ADAS_TakeOver_Request 0 "Off" 1 "Take Over 1" 2 "Take Over 2" 3 "Take Over 3" 4 "Take Over 4" 5 "Take Over 5" 6 "Take Over 6" 7 "Take Over 7" 8 "Take Over 8" 9 "Take Over 9" 10 "Take Over 10" 11 "Take Over 11" 12 "Take Over 12" 13 "Take Over 13" 14 "Take Over 14" 15 "Take Over 15" 16 "Take Over 6" 17 "Take Over 17" 18 "Take Over 18" 19 "Take Over 19" 20 "Take Over 20" 21 "Reserve 1" 22 "Reserved 2" 23 "Reserved 3" 24 "Reserved 4" 25 "Reserved 5" 26 "Reserved 6" 27 "Reserved 7" 28 "Reserved 8" 29 "Reserved 9" 30 "Reserved 10" 31 "Invalid";
VAL_ 130 ADAS_Sounds_Feed 0 "Off" 1 "Chime 1" 2 "Chime 2" 3 "Chime 3" 4 "Chime 4" 5 "Chime 5" 6 "Chime 6" 7 "Chime 7" 8 "Chime 8" 9 "Chime 9" 10 "Chime 10" 11 "Chime 11" 12 "Chime 12" 13 "Chime 13" 14 "Chime 14" 15 "Chime 15" 16 "Chime 16" 17 "Chime 17" 18 "Chime 18" 19 "Chime 19" 20 "Chime 20" 21 "Reserve 1" 22 "Reserved 2" 23 "Reserved 3" 24 "Reserved 4" 25 "Reserved 5" 26 "Reserved 6" 27 "Reserved 7" 28 "Reserved 8" 29 "Reserved 9" 30 "Reserved 10" 31 "Invalid";
VAL_ 133 ACM_Crash_Sts 0 "No_Event" 1 "Crash_Detected";
VAL_ 133 ACM_Airbag_Deployment_Status 0 "No_Airbag_Deployment" 1 "Airbag_Deployment";
VAL_ 133 ACM_Crash_Intensity 0 "No_Crash" 1 "Crash_Intensity_1" 2 "Crash_Intensity_2" 3 "Crash_Intensity_3";
VAL_ 133 ACM_Front_Crash 0 "No_Event" 1 "Front_Crash_Detected";
VAL_ 133 ACM_DriverSide_Crash 0 "No_Event" 1 "Driverside_Crash_Detected";
VAL_ 133 ACM_PassSide_Crash 0 "No_Event" 1 "PasSide_Crash_Detected";
VAL_ 133 ACM_Rear_Crash 0 "No_Event" 1 "Rear_Crash_Detected";
VAL_ 133 ACM_Rollover_Crash 0 "No_Event" 1 "Rollover_Crash_Detected";
VAL_ 149 STAT_ABS 0 "No error" 1 "Error Full functionality of ABS is not available" 2 "Reserved" 3 "Signal invalid";
VAL_ 149 AYC_Active 0 "Inactive" 1 "Active" 2 "Reserved" 3 "Signal invalid";
VAL_ 149 ASR_Active 0 "Inactive" 1 "Active" 2 "Reserved" 3 "Signal invalid";
VAL_ 149 STAT_DSC 0 "IDB normal" 1 "Traction Mode" 2 "IDB-OFF" 3 "Signal invalid";
VAL_ 149 DSC_Active 0 "Inactive" 1 "Active" 2 "Reserved" 3 "Signal invalid";
VAL_ 149 HBA_ActiveSignal 0 "Inactive" 1 "Active" 2 "Reserved" 3 "Signal invalid";
VAL_ 149 ARM_ActiveSignal 0 "Inactive" 1 "Active" 2 "Reserved" 3 "Signal invalid";
VAL_ 149 STAT_AutoHazardBlinking 0 "AutoHazardBlinking OFF" 1 "AutoHazardBlinking ON" 2 "Reserved" 3 "Signal invalid";
VAL_ 149 MSR_Active 0 "Inactive" 1 "Active" 2 "Reserved" 3 "Signal invalid";
VAL_ 149 HSA_ActiveSignal 0 "Inactive" 1 "Active" 2 "Reserved" 3 "Signal invalid";
VAL_ 149 EPBi_ECD_ActiveSignal 0 "Function supported by EPBi active signal" 1 "Function supported by EPBi no active" 2 "Reserved" 3 "Signal invalid";
VAL_ 149 TSM_Active 0 "Not active" 1 "Active" 2 "No trailer" 3 "Invalid";
VAL_ 149 HAS_Available 0 "No error" 1 "Error. Functionality of Hiil Hold is not available" 2 "Reserved" 3 "Signal invalid";
VAL_ 149 STAT_EBD 0 "No error" 1 "Error . Functionality of EBD is not available" 2 "Reserved" 3 "Signal invalid";
VAL_ 149 EBD_Active 0 "Inactive" 1 "Active" 2 "Reserved" 3 "Signal invalid";
VAL_ 149 ST_BRG_MSA 0 "vehicle is not held at speed 0 by the brake" 1 "vehicle is held at speed 0 by the brake" 14 "functions reports error" 15 "signal invalid";
VAL_ 150 MHU_IDB_Mode_Select_Signal 0 "IDB nomal" 1 "Traction Mode" 2 "IDB-OFF" 3 "Signal Invalid";
VAL_ 217 VCU_HVsystem_status 0 "Not ready" 1 "HV On" 2 "ReadyToDrive" 3 "Charging" 4 "Error" 5 "Reserved" 6 "Reserved" 7 "Reserved";
VAL_ 217 VCU_ACPD_Percent_Valid 0 "Valid" 1 "Invalid";
VAL_ 217 VCU_ACTGear 0 "P" 1 "R" 2 "N" 3 "D" 4 "Reserved" 5 "Reserved" 6 "Reserved" 7 "Fault";
VAL_ 217 VCU_ACTGearValid 0 "Valid" 1 "Invalid";
VAL_ 217 VCU_ACT_DriveMode 0 "Normal mode" 1 "ECO mode" 2 "Sport mode" 3 "Reserved" 4 "Reserved" 5 "Reserved" 6 "Reserved" 7 "Invalid";
VAL_ 217 VCU_ACT_DriveMode_Valid 0 "Valid" 1 "Invalid";
VAL_ 217 VCU_HV_DRVsystem_status 0 "Not available" 1 "Normal" 2 "Degration" 3 "Limphome" 4 "Error" 5 "Reserved" 6 "Reserved" 7 "Reserved";
VAL_ 217 VCU_Recu_BrakeLight_ON_Req 0 "Brake light OFF" 1 "Brake light ON" 2 "Reserved" 3 "Signal not available";
VAL_ 241 IDB_RecuBrakeControl_Sts 0 "Enable" 1 "Disable";
VAL_ 241 IDB_RecuBrkTorqueReq_Sts 0 "Not Active" 1 "Active";
VAL_ 241 IDB_Brake_Pedal_position_sts 0 "Valid" 1 "Invalid";
VAL_ 256 MHU_UserProfileId 0 "User 1 - Guess mode" 1 "User 2 - Valet mode" 2 "User 3" 3 "User 4" 4 "User 5" 5 "User 6" 6 "User 7" 7 "User 8" 8 "User 9" 9 "User 10" 15 "Invalid Value";
VAL_ 256 MHU_Connectivity_Status 0 "Init" 1 "No Connection" 2 "LTE Internet Connection" 3 "WIFI Internet Establish" 4 "WIFI + LTE Connection" 5 "Reserved" 6 "Reserved" 7 "Reserved";
VAL_ 257 DMS_Setting 0 "Init" 1 "late" 2 "normal" 3 "early";
VAL_ 257 DMS_Driver_registration_request 0 "Init" 1 "Identification" 2 "Delete";
VAL_ 257 DMS_Driver_ID_request 0 "Init" 1 "ID 1" 2 "ID 2" 3 "ID 3" 4 "ID 4" 5 "ID 5" 6 "ID 6" 7 "ID 7" 8 "ID 8" 9 "ID 9" 10 "ID 10" 11 "ID 11" 12 "ID 12" 13 "ID 13" 14 "ID 14" 15 "ID 15";
VAL_ 257 DMS_Status 0 "Init" 1 "DMS on" 2 "DMS off";
VAL_ 257 DMS_Image_processing 0 "Init" 1 "Ready to Receive" 2 "Receive processing" 3 "Receive successful" 4 "Not ready to receive" 5 "Cloud upload successful" 6 "Cloud upload unsuccessful" 7 "Reserved";
VAL_ 257 DMS_DriverConfirmDMSWarning 0 "Okay not pressed" 1 "Okay Pressed";
VAL_ 258 STAT_CL30s_Light_L 0 "OFF" 1 "ON" 2 "Failure" 3 "Signal invalid";
VAL_ 258 STAT_CL30s_L 0 "OFF" 1 "ON" 2 "Failure" 3 "Signal invalid";
VAL_ 258 STAT_CL15Wup_L 0 "OFF" 1 "ON" 2 "Failure" 3 "Signal invalid";
VAL_ 258 STAT_CrankRelayHW_BCM 0 "OFF" 1 "ON" 2 "Reserved" 3 "Signal invalid";
VAL_ 259 REQ_ConsumerControlWirelessCharg 0 "Reduction not activ" 1 "Reduction activ" 2 "Reserved" 3 "Signal invalid";
VAL_ 259 REQ_ConsumerControlAudioVolumeCo 0 "No reduction" 1 "Level 1" 2 "Level 2" 3 "Reserved" 4 "Reserved" 5 "Reserved" 6 "Reserved" 7 "Signal invalid";
VAL_ 259 REQ_ConsumerControlRearDefrost 0 "Reduction not activ" 1 "Reduction activ" 2 "Reserved" 3 "Signal invalid";
VAL_ 260 SOH_SUL 255 "Signal invalid";
VAL_ 260 SOH_SUL_STATE 0 "Not learned" 1 "Learned" 2 "Reserved" 3 "Signal invalid";
VAL_ 260 SOC_STATE 0 "deviation > 15% " 1 "deviation < 15%" 2 "deviation < 10%" 3 "invalid";
VAL_ 260 Resp_Error 0 "No Error" 1 "Error";
VAL_ 260 FLAG_INCONSTENCY 0 "No battery inconsistency" 1 "Battery inconsistency";
VAL_ 260 EBS_error 0 "No Error" 1 "Error";
VAL_ 260 FLAG_DISCONNECT 0 "No battery disconnection" 1 "Battery disconnection";
VAL_ 260 BCM_LV_Batt_Charging_Req 0 "Disable " 1 "Enable";
VAL_ 260 IBATT_QUIESCENT 253 "Outside quiescent current range" 254 "Reserved" 255 "Invalid";
VAL_ 261 BCM_STAT_TrunkAjar 0 "Closed" 1 "Opened" 2 "Reserved" 3 "Signal invalid";
VAL_ 261 BCM_STAT_DoorAjarFL 0 "Closed" 1 "Opened" 2 "Reserved" 3 "Signal invalid";
VAL_ 261 BCM_STAT_DoorAjarFR 0 "Closed" 1 "Opened" 2 "Reserved" 3 "Signal invalid";
VAL_ 261 BCM_STAT_DoorAjarRL 0 "Closed" 1 "Opened" 2 "Reserved" 3 "Signal invalid";
VAL_ 261 BCM_STAT_DoorAjarRR 0 "Closed" 1 "Opened" 2 "Reserved" 3 "Signal invalid";
VAL_ 261 BCM_STAT_BonnetAjar 0 "Closed" 1 "Opened" 2 "Reserved" 3 "Signal invalid";
VAL_ 262 BCM_DayRunningLampSts 0 "OFF" 1 "ON" 2 "Fault (Reserved)" 3 "Signal Invalid";
VAL_ 262 BCM_ReverseLightSts 0 "OFF" 1 "ON" 2 "Fault (Reserved)" 3 "Signal Invalid";
VAL_ 262 BCM_StopLightSts 0 "OFF" 1 "ON" 2 "Fault (Reserved)" 3 "Signal Invalid";
VAL_ 262 BCM_LicensePlateLightSts 0 "OFF" 1 "ON" 2 "Fault (Reserved)" 3 "Signal Invalid";
VAL_ 262 BCM_Fr_Dimming_dome_lampSts 0 "OFF" 1 "ON" 2 "Fault (Reserved)" 3 "Signal Invalid";
VAL_ 262 BCM_Rr_Dimming_dome_lampSts 0 "OFF" 1 "ON" 2 "Fault (Reserved)" 3 "Signal Invalid";
VAL_ 262 BCM_STAT_InteriorLight 0 "OFF" 1 "ON" 2 "Reserved" 3 "Signal invalid";
VAL_ 262 BCM_STAT_LightActivation 0 "OFF" 1 "PositionLight" 2 "LowBeam" 3 "AutoLight" 4 "Reserved" 5 "Reserved" 6 "Reserved" 7 "Signal invalid";
VAL_ 262 BCM_HighBeamSts 0 "OFF" 1 "ON" 2 "Fault (Reserved)" 3 "Signal Invalid";
VAL_ 262 BCM_LowBeamSts 0 "OFF" 1 "ON" 2 "Fault (Reserved)" 3 "Signal Invalid";
VAL_ 262 BCM_RearFogLmpSts 0 "OFF" 1 "ON" 2 "Fault (Reserved)" 3 "Signal Invalid";
VAL_ 262 BCM_FrntFogLmpSts 0 "OFF" 1 "ON" 2 "Fault (Reserved)" 3 "Signal Invalid";
VAL_ 262 BCM_PosLmpSts 0 "OFF" 1 "ON" 2 "Fault (Reserved)" 3 "Signal Invalid";
VAL_ 262 BCM_HornSts 0 "OFF" 1 "ON" 2 "Fault (Reserved)" 3 "Signal Invalid";
VAL_ 262 BCM_TurnIndicatorSts 0 "OFF" 1 "Left On" 2 "Right On" 3 "Left and Right On";
VAL_ 263 STAT_CDL_LED 0 "OFF" 1 "ON" 2 "blinking" 3 "Signal invalid";
VAL_ 263 STAT_DoorUnlockFL 0 "Locked" 1 "Unlocked" 2 "Reserved" 3 "Signal invalid";
VAL_ 263 STAT_ATWS 0 "Secured" 1 "Unsecured" 2 "Alarm" 3 "Partly secured" 4 "Reserved" 5 "Reserved" 6 "Reserved" 7 "Signal invalid";
VAL_ 263 STAT_DoorLockFL 0 "Unlocked" 1 "Locked" 2 "Reserved" 3 "Signal invalid";
VAL_ 265 BCM_STAT_BrakeSwitch 0 "Brake not pressed" 1 "Brake Pressed" 2 "Reserved" 3 "Signal invalid";
VAL_ 265 BCM_STAT_HazardWarn 0 "Not active" 1 "Active" 2 "Reserved" 3 "Signal invalid";
VAL_ 265 BCM_STAT_FuelPumpCutOFF 0 "Not active" 1 "Active" 2 "Reserved" 3 "Signal invalid";
VAL_ 265 BCM_FollowMeHomeActive 0 "Not Active" 1 "Active" 2 "Reserved" 3 "Signal Invalid";
VAL_ 265 BCM_STAT_Horn 0 "OFF" 1 "ON" 2 "Reserved" 3 "Signal invalid";
VAL_ 265 BCM_STAT_Autowiping 0 "OFF" 1 "ON" 2 "Reserved" 3 "Signal invalid";
VAL_ 265 BCM_TurnIndicator 0 "OFF" 1 "Left" 2 "Right";
VAL_ 265 BCM_WelcomeActive 0 "Not Active" 1 "Active" 2 "Reserved" 3 "Signal Invalid";
VAL_ 265 BCM_HighBeam 0 "OFF" 1 "High Beam" 2 "Flash high Beam" 3 "Fault";
VAL_ 265 ACM_Seat_Belt_Status_3rd_Row_Pas 0 "Not_buckled" 1 "Buckled" 2 "Not_Available" 3 "Failure";
VAL_ 265 ACM_Seat_Belt_Status_3rd_Row_Dri 0 "Not_buckled" 1 "Buckled" 2 "Not_Available" 3 "Failure";
VAL_ 266 LV_BatteryType 0 "Lead Acid Battery" 1 "Lithium Battery" 2 "Reversed" 3 "Invalid";
VAL_ 267 TrailerInput 0 "Trailer synchronous with CAN" 1 "Trailer synchronous with HW input" 2 "Reserved" 3 "Invalid";
VAL_ 267 TrailerSystemError 0 "No error" 1 "Error" 2 "Reserved" 3 "Invalid";
VAL_ 267 TRM_VoltageStatus 0 "No failure" 1 "Overvoltage" 2 "Undervoltage" 3 "Invalid";
VAL_ 267 TRM_STAT_BrakeLight 0 "OFF" 1 "ON" 2 "Reserved" 3 "Signal invalid";
VAL_ 267 TRM_STAT_FogLampRear 0 "OFF" 1 "ON" 2 "Failure" 3 "Signal invalid";
VAL_ 267 TRM_STAT_PositionLight 0 "PositionLight OFF" 1 "PositionLight ON" 2 "PositionLight failure" 3 "Signal invalid";
VAL_ 267 TRM_STAT_TurnIndicators 0 "OFF" 1 "Left turn lamp ON" 2 "Right turn lamp ON" 3 "Both turn lamps ON" 4 "Left turn lamp defect" 5 "Right turn lamp defect" 6 "Both turn lamp defect" 15 "Signal invalid";
VAL_ 267 TRM_STAT_ReverseLight 0 "OFF" 1 "ON" 2 "Reserved" 3 "Signal invalid";
VAL_ 267 TRM_STAT_HWBrakeLightInput 0 "Brakel Light Input not active TRM" 1 "Brakel Light Input  active TRM" 2 "Reserved" 3 "Signal invalid";
VAL_ 267 TRM_STAT_HWIndicatorInput 0 "Indicator Input not active TRM" 1 "Indicator Input active TRM" 2 "Reserved" 3 "Signal invalid";
VAL_ 267 TRM_STAT_HWPosLightInput 0 "PosLight nput not active TRM" 1 "PosLight input active TRM" 2 "Reserved" 3 "Signal invalid";
VAL_ 268 BCM_TboxAuthStatus 0 "Have not learn. Not allow action" 1 "PASSED" 2 "FALIED: Authentication fail" 3 "Invalid";
VAL_ 269 MHU_APM_ReqWindow 0 "No action" 1 "Closed(Top)" 2 "Open Bottom";
VAL_ 269 MHU_BCM_RemoteDoorCtrl 0 "Lock" 1 "Unlock" 2 "No action" 3 "Signal invalid";
VAL_ 269 MHU_BCM_reqTrunk 0 "Close" 1 "Open" 2 "No action" 3 "Signal invalid";
VAL_ 269 MHU_BCM_reqFrunk 0 "No action" 1 "Unlock" 2 "Reserved" 3 "Signal invalid";
VAL_ 269 MHU_BCM_ReqSunroof 0 "Closed" 127 "Vent" 150 "Stop" 255 "No Request";
VAL_ 270 RemoteAccessKey 0 "No command" 1 "Lock" 2 "Unlock" 3 "Tailgate unlock long press" 4 "Tailgate unlock" 5 "Long press lock" 6 "Long press unlock" 7 "Panic alarm long press" 8 "Panic alarm press" 15 "Invalid";
VAL_ 270 PassiveAccessTrunk 0 "Not pressed" 1 "Pressed" 2 "Reserved" 3 "Signal invalid";
VAL_ 270 ComfortOpen 0 "Not active" 1 "Active" 2 "Reserved" 3 "Signal invalid";
VAL_ 270 PassiveAccessDoor 0 "Not pressed" 1 "Pressed" 2 "PE switch long press" 3 "Extended Long Press";
VAL_ 270 FksOpen 0 "OFF" 1 "ON" 2 "Reserved" 3 "Signal invalid";
VAL_ 271 MHU_SetHornOnOff 0 "OFF" 1 "ON" 2 "No action" 3 "Invalid";
VAL_ 271 MHU_SetLowBeam 0 "OFF" 1 "ON" 2 "No action" 3 "Invalid";
VAL_ 271 MHU_SetHighBeam 0 "OFF" 1 "ON" 2 "No action" 3 "Invalid";
VAL_ 274 RemoteFunctionState 0 "Normal function" 1 "Remote function" 2 "Reserved" 3 "Signal Invalid";
VAL_ 274 STAT_BLS 0 "BLS not pressed" 1 "BLS pressed" 2 "Reserved" 3 "Signal invalid";
VAL_ 274 STAT_CL_50_L 0 "OFF" 1 "ON" 2 "Failure" 3 "Signal invalid";
VAL_ 274 Clamp50AdviceRemoteStart 0 "Engine Start announcement not active" 1 "Engine Start announcement active" 2 "Reserved" 3 "Invalid";
VAL_ 274 Clamp50AdviceESS 0 "Engine Start announcement not active" 1 "Engine Start announcement active" 2 "Reserved" 3 "Invalid";
VAL_ 274 STAT_CL_R_L 0 "OFF" 1 "ON" 2 "Failure" 3 "Signal invalid";
VAL_ 274 STAT_CL_15_1_L 0 "OFF" 1 "ON" 2 "Failure" 3 "Signal invalid";
VAL_ 274 STAT_CL_15_1_DME_L 0 "OFF" 1 "ON" 2 "Failure" 3 "Signal invalid";
VAL_ 274 FobId 0 "Key not available" 1 "FOB_1" 2 "FOB_2" 3 "Signal invalid";
VAL_ 274 STAT_Terminal 0 "OFF(Comfort Enable)" 1 "ACC (Park)" 2 "ON (Driver Present)" 3 "Engine start (eMotor running)" 4 "SW Update OTA" 5 "Reserved" 6 "Reserved" 7 "Signal Invalid";
VAL_ 274 STAT_CL30_C_BEV 0 "OFF" 1 "ON" 2 "Failure" 3 "Signal invalid";
VAL_ 274 BCM_Clamp_Transport 0 "Transport Disabled" 1 "Transport E-Motor Running" 2 "Transport Driver Present" 3 "Ttransport ACC" 4 "Transport OFF" 5 "Init" 6 "Reserved " 7 "Reserved ";
VAL_ 276 LV_ErrorSts 0 "None" 1 "BMS Warning" 2 "BMS temporarily fault" 3 "BMS permanent fault" 4 "Reserved" 5 "Reserved" 6 "Reserved" 7 "Invalid";
VAL_ 276 LV_Discharger_Err 0 "Normal" 1 "Error";
VAL_ 276 LV_Discharger_Sts 0 "Open" 1 "Close";
VAL_ 276 LV_Charger_Err 0 "Normal" 1 "Error";
VAL_ 276 LV_Charger_Sts 0 "Open" 1 "Close";
VAL_ 276 LV_OverVoltage 0 "No" 1 "Yes";
VAL_ 276 LV_UnderVoltage 0 "No" 1 "Yes";
VAL_ 276 LV_OverCurrent 0 "No" 1 "Yes";
VAL_ 276 LV_UnderTemp 0 "No" 1 "Yes";
VAL_ 276 LV_OverTemp 0 "No" 1 "Yes";
VAL_ 276 LV_OverCharge 0 "No" 1 "Yes";
VAL_ 276 LV_OverDischarge 0 "No" 1 "Yes";
VAL_ 276 LV_CellBalance_Sts 0 "Inactive" 1 "Active";
VAL_ 276 LV_CellBalance_Error 0 "Normal" 1 "Error";
VAL_ 276 LV_ThermalRunaway 0 "No" 1 "Yes";
VAL_ 277 BCM_ChildLock_Feedback 0 "OFF" 1 "ON" 2 "Reserved" 3 "Signal Invalid";
VAL_ 282 MHU_SET_WiperServicePositionMod 0 "OFF" 1 "ON" 2 "Reserved" 3 "Signal Invalid";
VAL_ 282 MHU_Read_KeyFobOnCenterConsole 0 "No Request" 1 "Req Read Keyfob on CenterConsol" 2 "Reserved" 3 "Signal Invalid";
VAL_ 283 TBOX_STAT_TerminalReq 0 "OFF(Comfort Enable)" 1 "ACC (Park)" 2 "ON (Driver Present)" 3 "ON (eMotor Running)" 4 "OTA" 5 "Reserved" 6 "No action" 7 "Signal invalid";
VAL_ 284 TBOX_FOTA_STAT_TerminalReq 0 "OFF(Comfort Enable)" 1 "ACC(Park)" 2 "ON (Driver Present)" 3 "FOTA" 4 "Reserved" 5 "Reserved" 6 "No action" 7 "Signal Invalid";
VAL_ 294 MHU_ISA_SpeedLimitCon_Percent 0 "0 Percent" 1 "5 Percent" 2 "10 Percent" 3 "15 percent" 4 "Reserved" 5 "Reserved" 6 "Reserved";
VAL_ 294 MHU_ISA_Speed_Setting 0 "0" 1 "5 KPH" 2 "10 KPH" 3 "15 KPH" 4 "20 KPH" 5 "5 MPH" 6 "10 MPH" 7 "15 MPH" 8 "Reserved" 9 "Reserved" 10 "Reserved" 11 "Reserved" 12 "Reserved" 13 "Reserved" 14 "Reserved";
VAL_ 295 ADAS_Mode1_status 0 "Off Mode" 1 "Mode1_standby" 2 "Mode1_active" 3 "Mode1_Passive";
VAL_ 295 ADAS_LKA_HOD_state 0 "Hands On" 1 "Hands Off Warning";
VAL_ 295 ADAS_ECU_check 0 "Available" 1 "Fault" 2 "reserved";
VAL_ 295 ADAS_LA_sens_Feed 0 "Early" 1 "Normal" 2 "Late" 3 "Reserved";
VAL_ 295 ADAS_LKA_ICON_Feed 0 "Off" 1 "Gray ICON" 2 "Green ICON" 3 "reserved";
VAL_ 295 ADAS_LDW_check 0 "Available" 1 "Fault" 2 "reserved" 3 "reserved";
VAL_ 295 ADAS_LKA_check 0 "Available" 1 "Fault" 2 "reserved" 3 "reserved";
VAL_ 295 ADAS_ALC_ICON_Feed 0 "Off" 1 "Gray ICON" 2 "Green ICON" 3 "White ICON" 4 "Yellow ICON" 5 "Red ICON";
VAL_ 295 ADAS_LA_popup 0 "No Popup" 1 "Take control Veh departing lane" 2 "Emergency steering for safety" 3 "lane keep assist in intervention" 4 "Emergency lane keep assist" 5 "reserved" 6 "reserved" 7 "Lane assist Unavailable";
VAL_ 295 ADAS_LA_AudWarning_Feed 0 "OFF feed" 1 "ON feed" 2 "Reserved" 3 "Signal invalid";
VAL_ 295 ADAS_LA_Mode_Feed 0 "OFF" 1 "Warning only" 2 "Warning and Steer" 3 "ELK" 4 "Signal Invalid";
VAL_ 295 ADAS_HWA_ICON_Feed 0 "Off" 1 "Gray ICON" 2 "Blue ICON" 3 "White ICON" 4 "Yellow ICON" 5 "Red ICON";
VAL_ 296 ADAS_RCTA_IndLeft 0 "Indicator output off" 1 "Indicator On(warning stage - 1)" 2 "Indicator flashing(warning stage - 2)" 3 "Reserved";
VAL_ 296 ADAS_RCTA_IndRight 0 "Indicator output off" 1 "Indicator On(warning stage - 1)" 2 "Indicator flashing(warning stage - 2)" 3 "Reserved";
VAL_ 296 ADAS_RCTA_SndWarn 0 "Sound Warning disable" 1 "Left Sound Warning enable" 2 "Right Sound Warning enable" 3 "Left and Right Sound Warning enable";
VAL_ 296 ADAS_IA_check 0 "Available" 1 "not Available";
VAL_ 296 ADAS_RCTA_state 0 "OFF State" 1 "Stand by state" 2 "Armed state" 3 "Warning stage" 4 "Malfunction Stage";
VAL_ 296 ADAS_RCTA_sens_Feed 0 "Early" 1 "Normal" 2 "Late" 3 "Reserved";
VAL_ 296 ADAS_IA_Left_warning 0 "No Warning" 1 "warning stage-1" 2 "warning stage-2" 3 "warning stage-3";
VAL_ 296 ADAS_FCW_Mode_Feed 0 "Off" 1 "ON";
VAL_ 296 ADAS_FCW_Sens_Feed 0 "Early" 1 "Normal" 2 "Late" 3 "Reserved";
VAL_ 296 ADAS_FCW_state 0 "OFF State" 1 "Stand by state" 2 "Active state" 3 "reserve";
VAL_ 296 ADAS_IA_state 0 "OFF state" 1 "Stand by state" 2 "Active State" 3 "reserve";
VAL_ 296 ADAS_FCW_check 0 "Available" 1 "Temporarily not available" 2 "Permanently not available";
VAL_ 296 ADAS_IA_Right_warning 0 "No Warning" 1 "warning stage-1" 2 "warning stage-2" 3 "warning stage-3";
VAL_ 296 ADAS_IA_Mode_Feed 0 "Off" 1 "ON";
VAL_ 296 ADAS_RCTA_check 0 "Available" 1 "Temporarily not available" 2 "Permanently not available";
VAL_ 296 ADAS_RCTA_Mode_Feed 0 "Off" 1 "On";
VAL_ 296 ADAS_FCW_warning 0 "No Warning" 1 "warning stage-1" 2 "warning stage-2" 3 "warning stage-3";
VAL_ 296 ADAS_LA_LeftLaneColor_Feed 0 "No color" 1 "Gray" 2 "White" 3 "Green" 4 "Blue" 5 "Yellow" 6 "Red" 7 "Reserved";
VAL_ 296 ADAS_LA_RightLaneColor_Feed 0 "No color" 1 "Gray" 2 "White" 3 "Green" 4 "Blue" 5 "Yellow" 6 "Red" 7 "Reserved";
VAL_ 297 MHU_SETTING_DMSWarning 0 "OFF" 1 "Warning only" 2 "Warning + Chime" 3 "Signal invalid";
VAL_ 303 ST_KL 0 "Init" 1 "Reserved" 2 "KL30" 3 "Reserved" 4 "Reserved" 5 "Reserved" 6 "KL30B-ON" 7 "KL30C-ON (BEV Only)" 8 "KLR-ON" 9 "KL15-change" 10 "KL15-ON" 11 "KL50-delay (ICE only)" 12 "KL50-Change(ICE only)" 13 "KL50-ON (ICE only)" 14 "Reserved" 15 "Signal invalid";
VAL_ 303 ST_KL_KEY_VLD 0 "Init" 1 "Key invalid" 2 "Key search activ" 3 "Key valid AR" 4 "Key valid IR" 5 "Key 10sec delay" 6 "Reserved" 7 "Reserved" 8 "Reserved" 9 "Reserved" 10 "Reserved" 11 "Reserved" 12 "Reserved" 13 "Reserved" 14 "Error" 15 "Signal invalid";
VAL_ 303 ST_STCD_PENG 0 "Startcondition traction not fulfilled" 1 "Startcondition traction fulfilled" 2 "Startcondition traction  implausible fulfilled" 3 "Signal invalid";
VAL_ 303 ST_SSB 0 "SSB not pressed" 1 "SSB pressed" 2 "Reserve" 3 "Signal invalid";
VAL_ 303 RWDT_BLS 0 "BLTS and BLS not applied" 1 "BLS applied" 2 "BLTS  applied" 3 "BLTS and BLS  valid applied" 4 "Reserved" 5 "Reserved" 6 "Reserved" 7 "Error (Invalid signal from BLTS or BLS)" 8 "Init" 15 "Signal invalid";
VAL_ 303 RQ_DRVG_RDI 0 "No action" 1 "Engine start advice" 2 "Reserved" 3 "Signal invalid";
VAL_ 303 CTR_ENG_STOP 0 "Init" 1 "Default" 2 "Motor_Off" 3 "Signal invalid";
VAL_ 303 ST_VEH_CON 0 "Initial (VSM_STM_STATE_INIT)" 1 "Standby, driver absent (VSM_STM_STATE_STANDBY)" 2 "Basis operation, driver present (VSM_STM_STATE_BASICOP)" 3 "Basis operation, vehicle coasting (VSM_STM_STATE_BASICOP_ROLL)" 4 "Engine postrun (VSM_STM_STATE_15OFF_DRIVE)" 5 "Ignition On (VSM_STM_STATE_IGNITION)" 6 "Ignition On, vehicle coasting (VSM_STM_STATE_IGNITION_ROLL)" 7 "Engine On, vehicle not coasting (VSM_STM_STATE_ENG_IDLE)" 8 "Driving (VSM_STM_STATE_DRIVE)" 9 "Impending start of engine (VSM_STM_STATE_ENG_START_PRE)" 10 "Impending start of engine, vehicle coasting (VSM_STM_STATE_ENG_START_PRE_ROLL)" 11 "Start engine (VSM_STM_STATE_ENG_START)" 12 "Start engine, vehicle coasting (VSM_STM_STATE_ENG_START_ROLL)" 13 "Car wash operation (VSM_STM_STATE_WASH)" 14 "Error (VSM_STM_STATE_ERROR)" 15 "Signal invalid";
VAL_ 304 ADAS_AEB_State 0 "OFF State" 1 "Stand by Mode" 2 "Active Mode" 3 "Hold Mode";
VAL_ 304 ADAS_RAEB_check 0 "Available" 1 "Temporarily not available" 2 "Permanently not available";
VAL_ 304 ADAS_AEB_check 0 "Available" 1 "Temporarily not available" 2 "Permanently not available";
VAL_ 304 ADAS_AEB_Mode_Feed 0 "Off" 1 "ON";
VAL_ 304 ADAS_RAEB_Mode_Feed 0 "Off" 1 "ON";
VAL_ 304 ADAS_AEB_Warning 0 "No warning" 1 "Braking" 2 "Post Feedback";
VAL_ 304 ADAS_RAEB_Warning 0 "No warning" 1 "Braking" 2 "Postfeedback";
VAL_ 304 ADAS_RAEB_State 0 "OFF State" 1 "Stand by Mode" 2 "Active Mode" 3 "Hold Mode";
VAL_ 307 ADAS_BSD_check 0 "Available" 1 "Temporarily not available" 2 "Permanently not available";
VAL_ 307 ADAS_BSD_state 0 "OFF State" 1 "Stand by state" 2 "Armed state" 3 "Static Warning" 4 "Flashing Warning" 5 "Malfunction stage" 6 "Reserved" 7 "Invalid";
VAL_ 307 ADAS_BSD_AudChime_Feed 0 "Off" 1 "On";
VAL_ 307 ADAS_BSD_IndLeft 0 "Indicator output off" 1 "Indicator On(warning stage - 1)" 2 "Indicator flashing(warning stage - 2)" 3 "Sensor Fault";
VAL_ 307 ADAS_BSD_IndRight 0 "Indicator output off" 1 "Indicator On(warning stage - 1)" 2 "Indicator flashing(warning stage - 2)" 3 "Sensor Fault";
VAL_ 307 ADAS_BSD_SndWarn 0 "Sound Warning disable" 1 "Left Sound Warning enable" 2 "Right Sound Warning enable" 3 "Left and Right Sound Warning enable";
VAL_ 307 ADAS_BSD_Mode_Feed 0 "Off" 1 "On";
VAL_ 307 ADAS_BSD_sens_Feed 0 "Early" 1 "Normal" 2 "Late" 3 "Reserved";
VAL_ 308 ADAS_ISA_SpeedLimitCnt_Spd_Feed 0 "0" 1 "5 KPH" 2 "10 KPH" 3 "15 KPH" 4 "20 KPH" 5 "5 MPH" 6 "10 MPH" 7 "15 MPH" 8 "Reserved" 9 "Reserved" 10 "Reserved" 11 "Reserved" 12 "Reserved" 13 "Reserved" 14 "Reserved";
VAL_ 308 ADAS_ISA_SpeedLimitCnt_Per_Feed 0 "0 Percent" 1 "5 Percent" 2 "10 Percent" 3 "15 percent" 4 "Reserved" 5 "Reserved" 6 "Reserved";
VAL_ 308 ADAS_far_lane_info 0 "left and right not detected" 1 "left detected&right not detected" 2 "left not detected and right detected" 3 "both detected";
VAL_ 310 PnC_activation 0 "ON" 1 "OFF";
VAL_ 310 PnCandEIM_Switch 0 "PnC" 1 "EMI";
VAL_ 310 PnC_trigger1 0 "Available" 1 "Not Available";
VAL_ 310 PnC_trigger2 0 "Available" 1 "Not Available";
VAL_ 310 PnC_Cert_Del 0 "Available" 1 "Del_Cert";
VAL_ 310 PnC_feature_enable 0 "Enable" 1 "Disable";
VAL_ 311 OK_OldSessionJoined 0 "Error" 1 "No Error";
VAL_ 311 OK_NewSessionEstablished 0 "Error" 1 "No Error";
VAL_ 311 OK_CertificateExpireSoon 0 "Error" 1 "No Error";
VAL_ 311 PnC_OK 0 "Error" 1 "No Error" 2 "Init";
VAL_ 311 Failed_CertificateNoAllowAtEVSE 0 "Error" 1 "No Error";
VAL_ 311 Failed_ContactorError 0 "Error" 1 "No Error";
VAL_ 311 Failed_NoChargeServiceSelectd 0 "Error" 1 "No Error";
VAL_ 311 PnC_Failed 0 "Error" 1 "No Error";
VAL_ 311 Failed_ServiceIDInvalid 0 "Error" 1 "No Error";
VAL_ 311 Falied_UnknownSession 0 "Error" 1 "No Error";
VAL_ 311 Failed_SignatureError 0 "Error" 1 "No Error";
VAL_ 311 Failed_SequenceError 0 "Error" 1 "No Error";
VAL_ 311 Failed_CertChainError 0 "Error" 1 "No Error";
VAL_ 311 Failed_NoCertificateAvailable 0 "Error" 1 "No Error";
VAL_ 311 Failed_CertificateRevoked 0 "Error" 1 "No Error";
VAL_ 311 Failed_PaymentSelectionInvalid 0 "Error" 1 "No Error";
VAL_ 311 Failed_WrongChargeParameter 0 "Error" 1 "No Error";
VAL_ 311 Failed_WrongEnergyTranferMode 0 "Error" 1 "No Error";
VAL_ 311 Failed_ChallengeInvalid 0 "Error" 1 "No Error";
VAL_ 311 Failed_ContractCancelled 0 "Error" 1 "No Error";
VAL_ 311 Failed_MeteringSignatureNotValid 0 "Error" 1 "No Error";
VAL_ 311 Failed_PowerDeliverNotApplied 0 "Error" 1 "No Error";
VAL_ 311 Failed_TarrifSelectionInvalid 0 "Error" 1 "No Error";
VAL_ 311 Failed_ChargingProfileInvalid 0 "Error" 1 "No Error";
VAL_ 311 Error_message_4 0 "Error" 1 "No Error";
VAL_ 311 Error_message_3 0 "Error" 1 "No Error";
VAL_ 311 Error_message_1 0 "Error" 1 "No Error";
VAL_ 311 Error_message_2 0 "Error" 1 "No Error";
VAL_ 311 PnC_ChargeSessionEnded 0 "In Progress" 1 "Charging_Ended";
VAL_ 311 PnC_Status 0 "Enabled" 1 "Disabled";
VAL_ 311 PnC_Contract_Status 0 "Installed" 1 "Not available";
VAL_ 311 Error_message_5 0 "Error" 1 "No Error";
VAL_ 312 AVM_AutoDsplSts 0 "OFF" 1 "ON";
VAL_ 312 AVM_auxiliarylineSts 0 "Open" 1 "Closed";
VAL_ 312 AVM_ShowAVMFdbck 0 "No Request" 1 "Hide" 2 "Show" 3 "exceed speed";
VAL_ 312 AVM_Sts 0 "off" 1 "Standby" 2 "Show AVM" 3 "Hide" 4 "Calibration" 5 "Fault";
VAL_ 313 APA_SensorFaultStsSRR 0 "Sensor Normal" 1 "Sensor Fault";
VAL_ 313 APA_SensorFaultStsSRL 0 "Sensor Normal" 1 "Sensor Fault";
VAL_ 313 APA_SensorFaultStsSFR 0 "Sensor Normal" 1 "Sensor Fault";
VAL_ 313 APA_SensorFaultStsSFL 0 "Sensor Normal" 1 "Sensor Fault";
VAL_ 317 SessionPaymentType 0 "EIM" 1 "PNC" 2 "Error";
VAL_ 320 APA_ParkingSlotType1 0 "Undecided" 1 "Vertical" 2 "Parallel" 3 "Oblique";
VAL_ 323 APA_ParkingSlotType2 0 "Undecided" 1 "Vertical" 2 "Parallel" 3 "Oblique";
VAL_ 326 APA_ParkingSlotType3 0 "Undecided" 1 "Vertical" 2 "Parallel" 3 "Oblique";
VAL_ 329 APA_ParkingSlotType4 0 "Undecided" 1 "Vertical" 2 "Parallel" 3 "Oblique";
VAL_ 332 APA_ParkingSlotType5 0 "Undecided" 1 "Vertical" 2 "Parallel" 3 "Oblique";
VAL_ 335 APA_ParkingSlotType6 0 "Undecided" 1 "Vertical" 2 "Parallel" 3 "Oblique";
VAL_ 357 VCU_AcChgGunIn 0 "disconnect" 1 "connect";
VAL_ 357 VCU_DCChgGunIn 0 "disconnect" 1 "connect";
VAL_ 357 VCU_CPValue 127 "Invalid";
VAL_ 360 MHU_AVM_AutoDsplReq 0 "off" 1 "ON";
VAL_ 360 MHU_AVM_auxiliarylineReq 0 "No Request" 1 "Request";
VAL_ 360 MHU_AVM_ShowAVMReq 0 "No Request" 1 "Hide" 2 "Show";
VAL_ 360 MHU_PA_Button 0 "No Request" 1 "Request";
VAL_ 360 MHU_APA_RecoverParking 0 "no request" 1 "request";
VAL_ 360 MHU_APA_FuncMode 0 "No Function" 1 "parking in" 2 "Parking out" 3 "drag parking";
VAL_ 360 MHU_APA_ParkOutTypeConfirm 0 "No Request" 1 "Front out" 2 "Rear out";
VAL_ 360 MHU_APA_ParkOutModeConfirm 0 "No Request" 1 "Perpendicular Parking" 2 "Parallel parking" 3 "Angled parking";
VAL_ 360 MHU_APA_ShowAPAReq 0 "No Request" 1 "Request APA on" 2 "Request APA off";
VAL_ 360 MHU_APA_ParkingStartReq 0 "no request" 1 "request APA" 2 "request RPA";
VAL_ 360 MHU_APAParkOutDircnConfirm 0 "no request" 1 "Request left" 2 "Request Right";
VAL_ 376 YSS_LONG_ACCUNFILTERED_QUAL 2 "VALID" 4 "SUBSITUTE" 6 "IN VALID" 14 "NOT AVAILABLE" 15 "UNFILLED";
VAL_ 376 YSS_LONG_ACC_QUAL 2 "VALID" 4 "SUBSITUTE" 6 "IN VALID" 14 "NOT AVAILABLE" 15 "UNFILLED";
VAL_ 377 YSS_LAT_ACCUNFILTERED_QUAL 2 "VALID" 4 "SUBSITUTE" 6 "IN VALID" 14 "NOT AVAILABLE" 15 "UNFILLED";
VAL_ 377 YSS_LAT_ACC_QUAL 2 "VALID" 4 "SUBSITUTE" 6 "IN VALID" 14 "NOT AVAILABLE" 15 "UNFILLED";
VAL_ 382 SAS_SASStsSnsr 0 "sensor value  Invalid" 1 "sensor value  valid";
VAL_ 382 SAS_SteerWhlRotSpdStatus 0 "Invalid" 1 "Valid";
VAL_ 382 SAS_SASFailure 0 "Failure" 1 "No Failure";
VAL_ 382 SAS_Calibrated 0 "Not Calibrated" 1 "Calibrated";
VAL_ 382 SAS_SteerWheelAngleValid 0 "Valid" 1 "Invalid";
VAL_ 385 VCU_Debug4 0 "No Error" 1 "Warning" 2 "Reduced HV System Power" 3 "Reduced Front EDS Power" 4 "Reduced Rear EDS Power" 5 "Front EDS Inhibit" 6 "Rear EDS Inhibit" 7 "Limp Home" 8 "Neutral Request" 9 "Soft Shutdown" 10 "Reduced HV System Power and Reduced Front EDS Power" 11 "Reduced HV System Power and Reduced Rear EDS Power" 12 "Reduced Front EDS Power and Reduced Rear EDS Power" 13 "Reduced HV System Power and Front EDS Inhibit" 14 "Reduced Rear EDS Power and Front EDS Inhibit" 15 "Reduced HV System Power and Rear EDS Inhibit" 16 "Reduced Front EDS Power and Rear EDS Inhibit" 17 "Reduced HV System Power and Limp Home" 18 "Front EDS Inhibit and Limp Home" 19 "Rear EDS Inhibit and Limp Home" 20 "Reduced HV System Power and Neutral Request" 21 "Emergency Shutdown";
